VERSION ""

NS_ :

BS_:

BU_: L_DHRR_FD L_UWB_BLE_MST_FD L_UWB_RR_FD L_UWB_BLE_SLV_FD L_UWB_FR_FD L_ROA_FR_FD L_ROA_FD L_DHRL_FD L_UWB_TRNK_FD L_UWB_FRNK_FD L_EDT_FD L_UWB_FL_FD GW_BDC_FD L_UWB_RL_FD L_SAL_FD L_WPC_FD L_TPMS_FD L_DHL_FD L_DHR_FD

BO_ 2214592593 L_BDC_FD_IAU_02_00ms: 16 GW_BDC_FD
 SG_ L_BDC_FD_IAU_Crc2Val : 0|16@1+ (1,0) [0|0] "0" Vector__XXX
 SG_ DKID_Del : 104|8@1+ (1,0) [0|0] ""  L_UWB_BLE_MST_FD,L_UWB_BLE_SLV_FD
 SG_ UWB_Ranging_Cmd_DKID : 112|8@1+ (1,0) [0|0] ""  L_UWB_BLE_MST_FD,L_UWB_BLE_SLV_FD,L_UWB_FL_FD,L_UWB_FRNK_FD,L_UWB_FR_FD,L_UWB_RL_FD,L_UWB_RR_FD,L_UWB_TRNK_FD
 SG_ UWB_Ranging_Cmd_Val : 120|8@1+ (1,0) [0|0] ""  L_UWB_BLE_MST_FD,L_UWB_BLE_SLV_FD,L_UWB_FL_FD,L_UWB_FRNK_FD,L_UWB_FR_FD,L_UWB_RL_FD,L_UWB_RR_FD,L_UWB_TRNK_FD
 SG_ L_BDC_FD_IAU_AlvCnt2Val : 16|8@1+ (1,0) [0|0] "0" Vector__XXX
 SG_ BDC_RndNum_Trgt : 24|4@1+ (1,0) [0|0] ""  L_UWB_BLE_MST_FD,L_UWB_BLE_SLV_FD,L_UWB_FL_FD,L_UWB_FRNK_FD,L_UWB_FR_FD,L_UWB_RL_FD,L_UWB_RR_FD,L_UWB_TRNK_FD
 SG_ BDC_RndNum_TRCod : 28|4@1+ (1,0) [0|0] ""  L_UWB_BLE_MST_FD,L_UWB_BLE_SLV_FD,L_UWB_FL_FD,L_UWB_FRNK_FD,L_UWB_FR_FD,L_UWB_RL_FD,L_UWB_RR_FD,L_UWB_TRNK_FD
 SG_ BDC_RndNum_Cmd : 32|4@1+ (1,0) [0|0] ""  L_UWB_BLE_MST_FD,L_UWB_BLE_SLV_FD,L_UWB_FL_FD,L_UWB_FRNK_FD,L_UWB_FR_FD,L_UWB_RL_FD,L_UWB_RR_FD,L_UWB_TRNK_FD
 SG_ BDC_RndNum : 40|48@1+ (1,0) [0|0] ""  L_UWB_BLE_MST_FD,L_UWB_BLE_SLV_FD,L_UWB_FL_FD,L_UWB_FRNK_FD,L_UWB_FR_FD,L_UWB_RL_FD,L_UWB_RR_FD,L_UWB_TRNK_FD
 SG_ BDC_Decrypt_FB : 88|2@1+ (1,0) [0|0] ""  L_UWB_BLE_MST_FD,L_UWB_BLE_SLV_FD
 SG_ DKID_Set : 96|8@1+ (1,0) [0|0] ""  L_UWB_BLE_MST_FD,L_UWB_BLE_SLV_FD

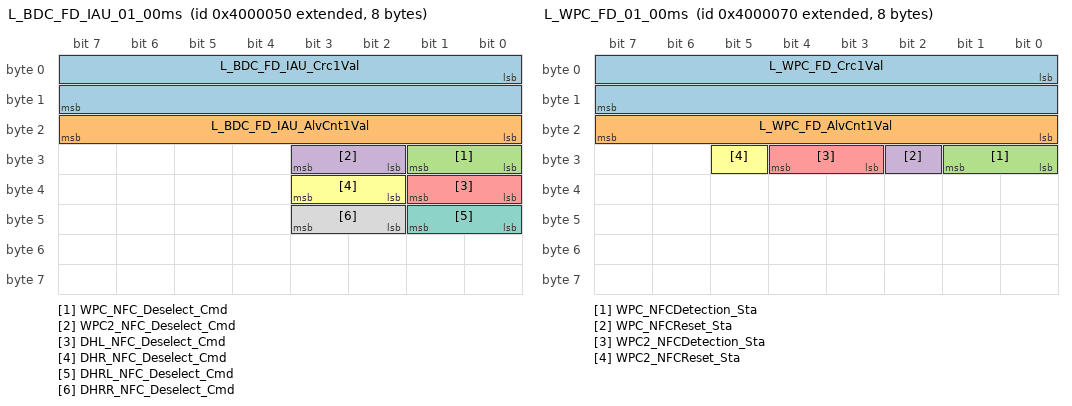
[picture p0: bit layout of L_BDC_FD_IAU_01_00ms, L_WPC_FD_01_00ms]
BO_ 2214592592 L_BDC_FD_IAU_01_00ms: 8 GW_BDC_FD
 SG_ L_BDC_FD_IAU_Crc1Val : 0|16@1+ (1,0) [0|0] "0" Vector__XXX
 SG_ L_BDC_FD_IAU_AlvCnt1Val : 16|8@1+ (1,0) [0|0] "0" Vector__XXX
 SG_ WPC_NFC_Deselect_Cmd : 24|2@1+ (1,0) [0|0] ""  L_WPC_FD
 SG_ WPC2_NFC_Deselect_Cmd : 26|2@1+ (1,0) [0|0] ""  L_WPC_FD
 SG_ DHL_NFC_Deselect_Cmd : 32|2@1+ (1,0) [0|0] ""  L_DHL_FD
 SG_ DHR_NFC_Deselect_Cmd : 34|2@1+ (1,0) [0|0] ""  L_DHR_FD
 SG_ DHRL_NFC_Deselect_Cmd : 40|2@1+ (1,0) [0|0] ""  L_DHRL_FD
 SG_ DHRR_NFC_Deselect_Cmd : 42|2@1+ (1,0) [0|0] ""  L_DHRR_FD

BO_ 2214592595 L_BDC_FD_IAU_04_00ms: 32 GW_BDC_FD
 SG_ L_BDC_FD_IAU_Crc4Val : 0|16@1+ (1,0) [0|0] "0" Vector__XXX
 SG_ L_BDC_FD_IAU_AlvCnt4Val : 16|8@1+ (1,0) [0|0] "0" Vector__XXX
 SG_ BDC_To_BLE_Enc_Data2 : 24|232@1+ (1,0) [0|0] ""  L_UWB_BLE_MST_FD,L_UWB_BLE_SLV_FD

BO_ 2214592594 L_BDC_FD_IAU_03_00ms: 32 GW_BDC_FD
 SG_ L_BDC_FD_IAU_Crc3Val : 0|16@1+ (1,0) [0|0] "0" Vector__XXX
 SG_ L_BDC_FD_IAU_AlvCnt3Val : 16|8@1+ (1,0) [0|0] "0" Vector__XXX
 SG_ BDC_To_BLE_Enc_Data1 : 24|232@1+ (1,0) [0|0] ""  L_UWB_BLE_MST_FD,L_UWB_BLE_SLV_FD

BO_ 2214592597 L_BDC_FD_IAU_06_00ms: 32 GW_BDC_FD
 SG_ L_BDC_FD_IAU_Crc6Val : 0|16@1+ (1,0) [0|0] "0" Vector__XXX
 SG_ L_BDC_FD_IAU_AlvCnt6Val : 16|8@1+ (1,0) [0|0] "0" Vector__XXX
 SG_ BDC_To_UWB_Enc_Data2 : 24|232@1+ (1,0) [0|0] ""  L_UWB_BLE_MST_FD,L_UWB_BLE_SLV_FD,L_UWB_FL_FD,L_UWB_FRNK_FD,L_UWB_FR_FD,L_UWB_RL_FD,L_UWB_RR_FD,L_UWB_TRNK_FD

BO_ 2214592596 L_BDC_FD_IAU_05_00ms: 32 GW_BDC_FD
 SG_ L_BDC_FD_IAU_Crc5Val : 0|16@1+ (1,0) [0|0] "0" Vector__XXX
 SG_ L_BDC_FD_IAU_AlvCnt5Val : 16|8@1+ (1,0) [0|0] "0" Vector__XXX
 SG_ BDC_To_UWB_Enc_Data1 : 24|232@1+ (1,0) [0|0] ""  L_UWB_BLE_MST_FD,L_UWB_BLE_SLV_FD,L_UWB_FL_FD,L_UWB_FRNK_FD,L_UWB_FR_FD,L_UWB_RL_FD,L_UWB_RR_FD,L_UWB_TRNK_FD

BO_ 2214592598 L_BDC_FD_IAU_07_00ms: 32 GW_BDC_FD
 SG_ L_BDC_FD_IAU_Crc7Val : 0|16@1+ (1,0) [0|0] "0" Vector__XXX
 SG_ L_BDC_FD_IAU_AlvCnt7Val : 16|8@1+ (1,0) [0|0] "0" Vector__XXX
 SG_ BDC_To_UWB_Enc_Data3 : 24|232@1+ (1,0) [0|0] ""  L_UWB_BLE_MST_FD,L_UWB_BLE_SLV_FD,L_UWB_FL_FD,L_UWB_FRNK_FD,L_UWB_FR_FD,L_UWB_RL_FD,L_UWB_RR_FD,L_UWB_TRNK_FD

BO_ 2281701632 L_UWB_RR_FD_10_200ms: 24 L_UWB_RR_FD
 SG_ L_UWB_RR_FD_Crc10Val : 0|16@1+ (1,0) [0|0] "0" Vector__XXX
 SG_ UWB_RR_SW_MCU_Ver_Major : 104|8@1+ (1,0) [0|0] ""  L_UWB_BLE_MST_FD
 SG_ UWB_RR_SW_MCU_Ver_Minor : 112|8@1+ (1,0) [0|0] ""  L_UWB_BLE_MST_FD
 SG_ UWB_RR_SW_IC_Ver_Major : 120|8@1+ (1,0) [0|0] ""  L_UWB_BLE_MST_FD
 SG_ UWB_RR_SW_IC_Ver_Minor : 128|8@1+ (1,0) [0|0] ""  L_UWB_BLE_MST_FD
 SG_ UWB_RR_DTC : 136|8@1+ (1,0) [0|0] ""  L_UWB_BLE_MST_FD
 SG_ L_UWB_RR_FD_AlvCnt10Val : 16|8@1+ (1,0) [0|0] "0" Vector__XXX
 SG_ UWB_RR_Status1 : 24|4@1+ (1,0) [0|7] ""  GW_BDC_FD,L_UWB_BLE_MST_FD
 SG_ UWB_RR_Status2 : 28|4@1+ (1,0) [0|0] ""  GW_BDC_FD,L_UWB_BLE_MST_FD
 SG_ UWB_RR_Status3 : 32|4@1+ (1,0) [0|0] ""  GW_BDC_FD,L_UWB_BLE_MST_FD
 SG_ UWB_RR_Status4 : 36|4@1+ (1,0) [0|0] ""  GW_BDC_FD,L_UWB_BLE_MST_FD
 SG_ UWB_RR_Status5 : 40|4@1+ (1,0) [0|0] ""  GW_BDC_FD,L_UWB_BLE_MST_FD
 SG_ UWB_RR_Status6 : 44|4@1+ (1,0) [0|0] ""  GW_BDC_FD,L_UWB_BLE_MST_FD
 SG_ UWB_RR_Status7 : 48|4@1+ (1,0) [0|0] ""  GW_BDC_FD,L_UWB_BLE_MST_FD
 SG_ UWB_RR_Status8 : 52|4@1+ (1,0) [0|0] ""  GW_BDC_FD,L_UWB_BLE_MST_FD
 SG_ UWB_RR_Status9 : 56|4@1+ (1,0) [0|0] ""  GW_BDC_FD,L_UWB_BLE_MST_FD
 SG_ UWB_RR_Status10 : 60|4@1+ (1,0) [0|0] ""  GW_BDC_FD,L_UWB_BLE_MST_FD
 SG_ UWB_RR_Status11 : 64|4@1+ (1,0) [0|0] ""  GW_BDC_FD,L_UWB_BLE_MST_FD
 SG_ UWB_RR_Status12 : 68|4@1+ (1,0) [0|0] ""  GW_BDC_FD,L_UWB_BLE_MST_FD
 SG_ UWB_RR_Status13 : 72|4@1+ (1,0) [0|0] ""  GW_BDC_FD,L_UWB_BLE_MST_FD
 SG_ UWB_RR_Status14 : 76|4@1+ (1,0) [0|0] ""  GW_BDC_FD,L_UWB_BLE_MST_FD
 SG_ UWB_RR_Status15 : 80|4@1+ (1,0) [0|0] ""  GW_BDC_FD,L_UWB_BLE_MST_FD
 SG_ UWB_RR_Status16 : 84|4@1+ (1,0) [0|0] ""  GW_BDC_FD,L_UWB_BLE_MST_FD
 SG_ UWB_RR_HW_Ver_Major : 88|8@1+ (1,0) [0|0] ""  L_UWB_BLE_MST_FD
 SG_ UWB_RR_HW_Ver_Minor : 96|8@1+ (1,0) [0|0] ""  L_UWB_BLE_MST_FD

BO_ 2525342209 L_UWB_FR_FD_06_00ms: 32 L_UWB_FR_FD
 SG_ L_UWB_FR_FD_Crc6Val : 0|16@1+ (1,0) [0|0] "" Vector__XXX
 SG_ L_UWB_FR_FD_AlvCnt6Val : 16|8@1+ (1,0) [0|0] "" Vector__XXX
 SG_ FR_SWID_4_IVD_1 : 24|232@1+ (1,0) [0|0] ""  L_UWB_BLE_MST_FD

BO_ 2281701648 L_UWB_TRNK_FD_10_200ms: 24 L_UWB_TRNK_FD
 SG_ L_UWB_TRNK_FD_Crc10Val : 0|16@1+ (1,0) [0|0] "0" Vector__XXX
 SG_ UWB_TRNK_SW_MCU_Ver_Major : 104|8@1+ (1,0) [0|0] ""  L_UWB_BLE_MST_FD
 SG_ UWB_TRNK_SW_MCU_Ver_Minor : 112|8@1+ (1,0) [0|0] ""  L_UWB_BLE_MST_FD
 SG_ UWB_TRNK_SW_IC_Ver_Major : 120|8@1+ (1,0) [0|0] ""  L_UWB_BLE_MST_FD
 SG_ UWB_TRNK_SW_IC_Ver_Minor : 128|8@1+ (1,0) [0|0] ""  L_UWB_BLE_MST_FD
 SG_ UWB_TRNK_DTC : 136|8@1+ (1,0) [0|0] ""  L_UWB_BLE_MST_FD
 SG_ L_UWB_TRNK_FD_AlvCnt10Val : 16|8@1+ (1,0) [0|0] "0" Vector__XXX
 SG_ UWB_TRNK_Status1 : 24|4@1+ (1,0) [0|7] ""  GW_BDC_FD,L_UWB_BLE_MST_FD
 SG_ UWB_TRNK_Status2 : 28|4@1+ (1,0) [0|0] ""  GW_BDC_FD,L_UWB_BLE_MST_FD
 SG_ UWB_TRNK_Status3 : 32|4@1+ (1,0) [0|0] ""  GW_BDC_FD,L_UWB_BLE_MST_FD
 SG_ UWB_TRNK_Status4 : 36|4@1+ (1,0) [0|0] ""  GW_BDC_FD,L_UWB_BLE_MST_FD
 SG_ UWB_TRNK_Status5 : 40|4@1+ (1,0) [0|0] ""  GW_BDC_FD,L_UWB_BLE_MST_FD
 SG_ UWB_TRNK_Status6 : 44|4@1+ (1,0) [0|0] ""  GW_BDC_FD,L_UWB_BLE_MST_FD
 SG_ UWB_TRNK_Status7 : 48|4@1+ (1,0) [0|0] ""  GW_BDC_FD,L_UWB_BLE_MST_FD
 SG_ UWB_TRNK_Status8 : 52|4@1+ (1,0) [0|0] ""  GW_BDC_FD,L_UWB_BLE_MST_FD
 SG_ UWB_TRNK_Status9 : 56|4@1+ (1,0) [0|0] ""  GW_BDC_FD,L_UWB_BLE_MST_FD
 SG_ UWB_TRNK_Status10 : 60|4@1+ (1,0) [0|0] ""  GW_BDC_FD,L_UWB_BLE_MST_FD
 SG_ UWB_TRNK_Status11 : 64|4@1+ (1,0) [0|0] ""  GW_BDC_FD,L_UWB_BLE_MST_FD
 SG_ UWB_TRNK_Status12 : 68|4@1+ (1,0) [0|0] ""  GW_BDC_FD,L_UWB_BLE_MST_FD
 SG_ UWB_TRNK_Status13 : 72|4@1+ (1,0) [0|0] ""  GW_BDC_FD,L_UWB_BLE_MST_FD
 SG_ UWB_TRNK_Status14 : 76|4@1+ (1,0) [0|0] ""  GW_BDC_FD,L_UWB_BLE_MST_FD
 SG_ UWB_TRNK_Status15 : 80|4@1+ (1,0) [0|0] ""  GW_BDC_FD,L_UWB_BLE_MST_FD
 SG_ UWB_TRNK_Status16 : 84|4@1+ (1,0) [0|0] ""  GW_BDC_FD,L_UWB_BLE_MST_FD
 SG_ UWB_TRNK_HW_Ver_Major : 88|8@1+ (1,0) [0|0] ""  L_UWB_BLE_MST_FD
 SG_ UWB_TRNK_HW_Ver_Minor : 96|8@1+ (1,0) [0|0] ""  L_UWB_BLE_MST_FD

BO_ 2214592624 L_WPC_FD_01_00ms: 8 L_WPC_FD
 SG_ L_WPC_FD_Crc1Val : 0|16@1+ (1,0) [0|0] "0" Vector__XXX
 SG_ L_WPC_FD_AlvCnt1Val : 16|8@1+ (1,0) [0|0] "0" Vector__XXX
 SG_ WPC_NFCDetection_Sta : 24|2@1+ (1,0) [0|0] ""  GW_BDC_FD
 SG_ WPC_NFCReset_Sta : 26|1@1+ (1,0) [0|0] ""  GW_BDC_FD
 SG_ WPC2_NFCDetection_Sta : 27|2@1+ (1,0) [0|0] ""  GW_BDC_FD
 SG_ WPC2_NFCReset_Sta : 29|1@1+ (1,0) [0|0] ""  GW_BDC_FD

BO_ 2281701664 L_ROA_FD_01_200ms: 32 L_ROA_FD
 SG_ L_ROA_FD_Crc1Val : 0|16@1+ (1,0) [0|0] "0" Vector__XXX
 SG_ L_ROA_FD_AlvCnt1Val : 16|8@1+ (1,0) [0|0] "0" Vector__XXX
 SG_ ROA_SW_Ver_Major : 24|7@1+ (1,0) [0|0] ""  GW_BDC_FD
 SG_ ROA_SW_Ver_Minor1 : 31|7@1+ (1,0) [0|0] ""  GW_BDC_FD
 SG_ ROA_SW_Ver_Minor2 : 38|7@1+ (1,0) [0|0] ""  GW_BDC_FD
 SG_ ROA_ClassStat : 45|3@1+ (1,0) [0|0] ""  GW_BDC_FD
 SG_ ROA_SnSrStat : 48|3@1+ (1,0) [0|0] ""  GW_BDC_FD
 SG_ ROA_DetInfo : 51|3@1+ (1,0) [0|0] ""  GW_BDC_FD
 SG_ ROA_SnSrBlckgeErrStat : 54|2@1+ (1,0) [0|0] ""  GW_BDC_FD
 SG_ ROA_SnSrErrStat : 56|2@1+ (1,0) [0|0] ""  GW_BDC_FD

BO_ 2281701666 L_ROA_FR_FD_01_200ms: 32 L_ROA_FR_FD
 SG_ L_ROA_FR_FD_Crc1Val : 0|16@1+ (1,0) [0|0] "0" Vector__XXX
 SG_ L_ROA_FR_FD_AlvCnt1Val : 16|8@1+ (1,0) [0|0] "0" Vector__XXX
 SG_ ROA_FR_SW_Ver_Major : 24|7@1+ (1,0) [0|0] ""  L_ROA_FD
 SG_ ROA_FR_SW_Ver_Minor1 : 31|7@1+ (1,0) [0|0] ""  L_ROA_FD
 SG_ ROA_FR_SW_Ver_Minor2 : 38|7@1+ (1,0) [0|0] ""  L_ROA_FD
 SG_ ROA_FR_ClassStat : 45|3@1+ (1,0) [0|0] ""  L_ROA_FD
 SG_ ROA_FR_SnSrStat : 48|3@1+ (1,0) [0|0] ""  L_ROA_FD
 SG_ ROA_FR_DetInfo : 51|3@1+ (1,0) [0|0] ""  L_ROA_FD
 SG_ ROA_FR_SnSrBlckgeErrStat : 54|2@1+ (1,0) [0|0] ""  L_ROA_FD
 SG_ ROA_FR_SnSrErrStat : 56|2@1+ (1,0) [0|0] ""  L_ROA_FD

BO_ 2214592608 L_BDC_FD_ROA_02_00ms: 32 GW_BDC_FD
 SG_ L_BDC_FD_ROA_Crc2Val : 0|16@1+ (1,0) [0|0] "0" Vector__XXX
 SG_ L_BDC_FD_ROA_AlvCnt2Val : 16|8@1+ (1,0) [0|0] "0" Vector__XXX
 SG_ BDCROADataByte0 : 24|8@1+ (1,0) [0|0] ""  L_ROA_FD,L_ROA_FR_FD
 SG_ BDCROADataByte1 : 32|8@1+ (1,0) [0|0] ""  L_ROA_FD,L_ROA_FR_FD
 SG_ BDCROADataByte2 : 40|8@1+ (1,0) [0|0] ""  L_ROA_FD,L_ROA_FR_FD
 SG_ BDCROADataByte3 : 48|8@1+ (1,0) [0|0] ""  L_ROA_FD,L_ROA_FR_FD
 SG_ BDCROADataByte4 : 56|8@1+ (1,0) [0|0] ""  L_ROA_FD,L_ROA_FR_FD
 SG_ BDCROADataByte5 : 64|8@1+ (1,0) [0|0] ""  L_ROA_FD,L_ROA_FR_FD
 SG_ BDCROADataByte6 : 72|8@1+ (1,0) [0|0] ""  L_ROA_FD,L_ROA_FR_FD
 SG_ BDCROADataByte7 : 80|8@1+ (1,0) [0|0] ""  L_ROA_FD,L_ROA_FR_FD

BO_ 2525341697 L_UWB_FR_FD_04_00ms: 32 L_UWB_FR_FD
 SG_ L_UWB_FR_FD_Crc4Val : 0|16@1+ (1,0) [0|0] "" Vector__XXX
 SG_ L_UWB_FR_FD_AlvCnt4Val : 16|8@1+ (1,0) [0|0] "" Vector__XXX
 SG_ FR_SWID_3_IVD_1 : 24|232@1+ (1,0) [0|0] ""  L_UWB_BLE_MST_FD

BO_ 2281701680 L_SAL_FD_01_200ms: 32 L_SAL_FD
 SG_ L_SAL_FD_Crc1Val : 0|16@1+ (1,0) [0|0] "0" Vector__XXX
 SG_ SAL_BttmBrightnessDutyRatio : 105|8@1+ (1,0) [0|0] ""  GW_BDC_FD
 SG_ SAL_BttmFadeInTime : 113|8@1+ (1,0) [0|0] ""  GW_BDC_FD
 SG_ SAL_BttmFadeOutTimeValue : 121|8@1+ (1,0) [0|0] ""  GW_BDC_FD
 SG_ SAL_MLNShiftModOptionState : 129|2@1+ (1,0) [0|0] ""  GW_BDC_FD
 SG_ L_SAL_FD_AlvCnt1Val : 16|8@1+ (1,0) [0|0] "0" Vector__XXX
 SG_ SAL_MLSALApplyState : 24|2@1+ (1,0) [0|0] ""  GW_BDC_FD
 SG_ SAL_MLAIVoiceOptionState : 26|2@1+ (1,0) [0|0] ""  GW_BDC_FD
 SG_ SAL_MLTherapyOptionState : 28|2@1+ (1,0) [0|0] ""  GW_BDC_FD
 SG_ SAL_MLDualColorOptionState : 30|2@1+ (1,0) [0|0] ""  GW_BDC_FD
 SG_ SAL_MLNumRecommendColor : 32|4@1+ (1,0) [0|0] ""  GW_BDC_FD
 SG_ SAL_UPRColorXValue : 36|8@1+ (1,0) [0|0] ""  GW_BDC_FD
 SG_ SAL_UPRColorYValue : 44|8@1+ (1,0) [0|0] ""  GW_BDC_FD
 SG_ SAL_BrightnessDutyRatio : 52|8@1+ (1,0) [0|0] ""  GW_BDC_FD
 SG_ SAL_FadeInTime : 60|8@1+ (1,0) [0|0] ""  GW_BDC_FD
 SG_ SAL_FadeOutTimeValue : 68|8@1+ (1,0) [0|0] ""  GW_BDC_FD
 SG_ SAL_MLEarlyEveningOptionState : 76|2@1+ (1,0) [0|0] ""  GW_BDC_FD
 SG_ SAL_MLTempChgOptionState : 78|2@1+ (1,0) [0|0] ""  GW_BDC_FD
 SG_ SAL_MLPhoneCallModOptionState : 80|2@1+ (1,0) [0|0] ""  GW_BDC_FD
 SG_ SAL_MLDoorWarnOptionState : 82|3@1+ (1,0) [0|0] ""  GW_BDC_FD
 SG_ SAL_MLHazardModOptionState : 85|2@1+ (1,0) [0|0] ""  GW_BDC_FD
 SG_ SAL_MLLowFuelModOptionState : 87|2@1+ (1,0) [0|0] ""  GW_BDC_FD
 SG_ SAL_BttmColorXValue : 89|8@1+ (1,0) [0|0] ""  GW_BDC_FD
 SG_ SAL_BttmColorYValue : 97|8@1+ (1,0) [0|0] ""  GW_BDC_FD

BO_ 1025 BDC_FD_SMK_02_200ms: 32 GW_BDC_FD
 SG_ BDC_FD_SMK_Crc2Val : 0|16@1+ (1,0) [0|0] "" Vector__XXX
 SG_ SMK_RpmLoByteVal_Copy_0 : 104|8@1+ (1,0) [0|0] "" Vector__XXX
 SG_ SMK_VehSpdDrctVal_Copy_0 : 112|8@1+ (1,0) [0|0] "" Vector__XXX
 SG_ Fob_BattStaInfo_Copy_0 : 120|2@1+ (1,0) [0|0] "" Vector__XXX
 SG_ Fob_FoundDrvWlcmArea_Copy_0 : 122|2@1+ (1,0) [0|0] "" Vector__XXX
 SG_ Fob_FoundAsstWlcmArea_Copy_0 : 124|2@1+ (1,0) [0|0] "" Vector__XXX
 SG_ Fob_FoundExtrnlArea_Copy_0 : 126|2@1+ (1,0) [0|0] "" Vector__XXX
 SG_ Fob_FoundIntArea_Copy_0 : 128|2@1+ (1,0) [0|0] "" Vector__XXX
 SG_ Fob_LearntSta_Copy_0 : 130|2@1+ (1,0) [0|0] "" Vector__XXX
 SG_ RSPA_LearntSta_Copy_0 : 132|2@1+ (1,0) [0|0] "" Vector__XXX
 SG_ RSPA_RFSigErrSta_Copy_0 : 134|2@1+ (1,0) [0|0] "" Vector__XXX
 SG_ RSPA_CanErrSta_Copy_0 : 136|2@1+ (1,0) [0|0] "" Vector__XXX
 SG_ RSPA_ModSta_SMK_Copy_0 : 138|3@1+ (1,0) [0|0] "" Vector__XXX
 SG_ RSPA_FobBattSta_Copy_0 : 141|3@1+ (1,0) [0|0] "" Vector__XXX
 SG_ Fob_BtnReleasedSta_Copy_0 : 144|2@1+ (1,0) [0|0] "" Vector__XXX
 SG_ Fob_FoundWlcmArea_Copy_0 : 146|2@1+ (1,0) [0|0] "" Vector__XXX
 SG_ USM_WALModSta_Copy_0 : 148|3@1+ (1,0) [0|0] "" Vector__XXX
 SG_ USM_SmrtTrnkTlgtModSta_Copy_0 : 152|3@1+ (1,0) [0|0] "" Vector__XXX
 SG_ USM_SAUModSta : 155|3@1+ (1,0) [0|0] "" Vector__XXX
 SG_ SMK_RLHndLkSnsrSta_Copy_0 : 158|2@1+ (1,0) [0|0] "" Vector__XXX
 SG_ BDC_FD_SMK_AlvCnt2Val : 16|8@1+ (1,0) [0|0] "" Vector__XXX
 SG_ SMK_RLDrHndUnLkSnsrSta_Copy_0 : 160|2@1+ (1,0) [0|0] "" Vector__XXX
 SG_ SMK_RRDrHndLkSnsrSta_Copy_0 : 162|2@1+ (1,0) [0|0] "" Vector__XXX
 SG_ SMK_RRDrHndUnLkSnsrSta_Copy_0 : 164|2@1+ (1,0) [0|0] "" Vector__XXX
 SG_ Fob_FoundCabinArea_Copy_0 : 166|2@1+ (1,0) [0|0] "" Vector__XXX
 SG_ SMK_ResultRmtStrt : 168|3@1+ (1,0) [0|0] "" Vector__XXX
 SG_ SMK_EncryptTeleOptSta : 171|2@1+ (1,0) [0|0] "" Vector__XXX
 SG_ Auth_ISKLearnSta2_Copy_0 : 173|3@1+ (1,0) [0|0] "" Vector__XXX
 SG_ Auth_ISKLearnSta_Copy_0 : 176|3@1+ (1,0) [0|0] "" Vector__XXX
 SG_ SMK_TlPwrOnSta_Copy_0 : 179|2@1+ (1,0) [0|0] "" Vector__XXX
 SG_ Fob_FoundForChargingDoor_Copy_0 : 181|2@1+ (1,0) [0|0] "" Vector__XXX
 SG_ SSB_StrtStpBtnSw1Sta_Copy_0 : 24|2@1+ (1,0) [0|0] ""  L_UWB_BLE_MST_FD
 SG_ SSB_StrtStpBtnSw2Sta_Copy_0 : 26|2@1+ (1,0) [0|0] ""  L_UWB_BLE_MST_FD
 SG_ SMK_AuthSta_Copy_0 : 28|3@1+ (1,0) [0|0] "" Vector__XXX
 SG_ SMK_TlPwrOnOpt_Copy_0 : 31|1@1+ (1,0) [0|0] "" Vector__XXX
 SG_ SMK_Ign1InSta_Copy_0 : 32|2@1+ (1,0) [0|0] "" Vector__XXX
 SG_ SMK_Ign1RlySta_Copy_0 : 34|2@1+ (1,0) [0|0] "" Vector__XXX
 SG_ SMK_Ign2InSta_Copy_0 : 36|2@1+ (1,0) [0|0] "" Vector__XXX
 SG_ SMK_Ign2RlySta_Copy_0 : 38|2@1+ (1,0) [0|0] "" Vector__XXX
 SG_ SMK_StrtFdbckSta_Copy_0 : 40|2@1+ (1,0) [0|0] "" Vector__XXX
 SG_ SMK_StrtrRlyOutSta_Copy_0 : 42|2@1+ (1,0) [0|0] "" Vector__XXX
 SG_ SMK_AccInSta_Copy_0 : 44|2@1+ (1,0) [0|0] "" Vector__XXX
 SG_ SMK_AccRlySta_Copy_0 : 46|2@1+ (1,0) [0|0] "" Vector__XXX
 SG_ SMK_CLUAccIndOnReq_Copy_0 : 48|2@1+ (1,0) [0|0] "" Vector__XXX
 SG_ SMK_VDModeActSta_Copy_0 : 50|2@1+ (1,0) [0|0] "" Vector__XXX
 SG_ SMK_SCULckUnlckSta_Copy_0 : 52|2@1+ (1,0) [0|0] "" Vector__XXX
 SG_ SMK_TlEngRunSta_Copy_0 : 54|2@1+ (1,0) [0|0] "" Vector__XXX
 SG_ SMK_TlCrnkModSta_Copy_0 : 56|2@1+ (1,0) [0|0] "" Vector__XXX
 SG_ SMK_RmtKeyEngRunSta_Copy_0 : 58|2@1+ (1,0) [0|0] "" Vector__XXX
 SG_ SMK_RmtKeyCrnkModSta_Copy_0 : 60|2@1+ (1,0) [0|0] "" Vector__XXX
 SG_ SMK_AsstTgglBtnSta_Copy_0 : 62|2@1+ (1,0) [0|0] "" Vector__XXX
 SG_ SMK_DrvTglBtnSta_Copy_0 : 64|2@1+ (1,0) [0|0] "" Vector__XXX
 SG_ SMK_RrLftTglBtnSta_Copy_0 : 66|2@1+ (1,0) [0|0] "" Vector__XXX
 SG_ SMK_RrRtTglBtnSta_Copy_0 : 68|2@1+ (1,0) [0|0] "" Vector__XXX
 SG_ SMK_TgglBtnStuckSta_Copy_0 : 70|2@1+ (1,0) [0|0] "" Vector__XXX
 SG_ SMK_AsstDrHndUnLkSnsrSta_Copy_0 : 72|2@1+ (1,0) [0|0] "" Vector__XXX
 SG_ SMK_BrkSwSta_Copy_0 : 74|2@1+ (1,0) [0|0] "" Vector__XXX
 SG_ SMK_GearPosPSwSta_Copy_0 : 76|2@1+ (1,0) [0|0] "" Vector__XXX
 SG_ SMK_CltchIgnLkSwSta_Copy_0 : 78|2@1+ (1,0) [0|0] "" Vector__XXX
 SG_ SMK_DrvDrHndLkSnsrSta_Copy_0 : 80|2@1+ (1,0) [0|0] "" Vector__XXX
 SG_ SMK_DrvDrHndUnLkSnsrSta_Copy_0 : 82|2@1+ (1,0) [0|0] "" Vector__XXX
 SG_ SMK_AsstDrHndLkSnsrSta_Copy_0 : 84|2@1+ (1,0) [0|0] "" Vector__XXX
 SG_ LFAnt_FltSta_Copy_0 : 86|2@1+ (1,0) [0|0] "" Vector__XXX
 SG_ LFAnt_SrchSta_Copy_0 : 88|2@1+ (1,0) [0|0] "" Vector__XXX
 SG_ Lamp_HzrdBlnkngSta_Copy_0 : 90|3@1+ (1,0) [0|0] "" Vector__XXX
 SG_ Lamp_SmrtWlcmLtOnReq_Copy_0 : 93|2@1+ (1,0) [0|0] "" Vector__XXX
 SG_ SMK_RpmHiByteVal_Copy_0 : 96|8@1+ (1,0) [0|0] "" Vector__XXX

BO_ 2529540353 L_UWB_RR_FD_05_00ms: 32 L_UWB_RR_FD
 SG_ L_UWB_RR_FD_Crc5Val : 0|16@1+ (1,0) [0|0] "" Vector__XXX
 SG_ L_UWB_RR_FD_AlvCnt5Val : 16|8@1+ (1,0) [0|0] "" Vector__XXX
 SG_ RR_SWID_3_IVD_2 : 24|24@1+ (1,0) [0|0] ""  L_UWB_BLE_MST_FD

BO_ 2521142529 L_UWB_BLE_SLV_FD_09_00ms: 32 L_UWB_BLE_SLV_FD
 SG_ L_UWB_BLE_SLV_FD_Crc9Val : 0|16@1+ (1,0) [0|0] "" Vector__XXX
 SG_ L_UWB_BLE_SLV_FD_AlvCnt9Val : 16|8@1+ (1,0) [0|0] "" Vector__XXX
 SG_ SLV_SWID_2_IVD_1 : 24|232@1+ (1,0) [0|0] ""  L_UWB_BLE_MST_FD

BO_ 2533738753 L_UWB_FRNK_FD_05_00ms: 32 L_UWB_FRNK_FD
 SG_ L_UWB_FRNK_FD_Crc5Val : 0|16@1+ (1,0) [0|0] "" Vector__XXX
 SG_ L_UWB_FRNK_FD_AlvCnt5Val : 16|8@1+ (1,0) [0|0] "" Vector__XXX
 SG_ FRNK_SWID_3_IVD_2 : 24|24@1+ (1,0) [0|0] ""  L_UWB_BLE_MST_FD

BO_ 2529540865 L_UWB_RR_FD_07_00ms: 32 L_UWB_RR_FD
 SG_ L_UWB_RR_FD_Crc7Val : 0|16@1+ (1,0) [0|0] "" Vector__XXX
 SG_ L_UWB_RR_FD_AlvCnt7Val : 16|8@1+ (1,0) [0|0] "" Vector__XXX
 SG_ RR_SWID_4_IVD_2 : 24|24@1+ (1,0) [0|0] ""  L_UWB_BLE_MST_FD

BO_ 2521143041 L_UWB_BLE_SLV_FD_11_00ms: 32 L_UWB_BLE_SLV_FD
 SG_ L_UWB_BLE_SLV_FD_Crc11Val : 0|16@1+ (1,0) [0|0] "" Vector__XXX
 SG_ L_UWB_BLE_SLV_FD_AlvCnt11Val : 16|8@1+ (1,0) [0|0] "" Vector__XXX
 SG_ SLV_SWID_3_IVD_1 : 24|232@1+ (1,0) [0|0] ""  L_UWB_BLE_MST_FD

BO_ 2533739265 L_UWB_FRNK_FD_07_00ms: 32 L_UWB_FRNK_FD
 SG_ L_UWB_FRNK_FD_Crc7Val : 0|16@1+ (1,0) [0|0] "" Vector__XXX
 SG_ L_UWB_FRNK_FD_AlvCnt7Val : 16|8@1+ (1,0) [0|0] "" Vector__XXX
 SG_ FRNK_SWID_4_IVD_2 : 24|24@1+ (1,0) [0|0] ""  L_UWB_BLE_MST_FD

BO_ 2214593024 L_EDT_FD_BLE_Dvp_01_00ms: 32 L_EDT_FD
 SG_ EDT_BLE_Dvp_Data : 0|256@1+ (1,0) [0|0] ""  L_UWB_BLE_MST_FD,L_UWB_BLE_SLV_FD,L_UWB_FL_FD,L_UWB_FRNK_FD,L_UWB_FR_FD,L_UWB_RL_FD,L_UWB_RR_FD,L_UWB_TRNK_FD

BO_ 2214593025 L_EDT_FD_DH_Dvp_02_00ms: 32 L_EDT_FD
 SG_ EDT_DH_Dvp_Data : 0|255@1+ (1,0) [0|0] ""  L_UWB_BLE_MST_FD,L_UWB_BLE_SLV_FD

BO_ 2214593026 L_EDT_FD_UWB_Dvp_03_00ms: 32 L_EDT_FD
 SG_ EDT_UWB_Dvp_Data : 0|256@1+ (1,0) [0|0] ""  L_UWB_BLE_MST_FD,L_UWB_BLE_SLV_FD,L_UWB_FL_FD,L_UWB_FRNK_FD,L_UWB_FR_FD,L_UWB_RL_FD,L_UWB_RR_FD,L_UWB_TRNK_FD

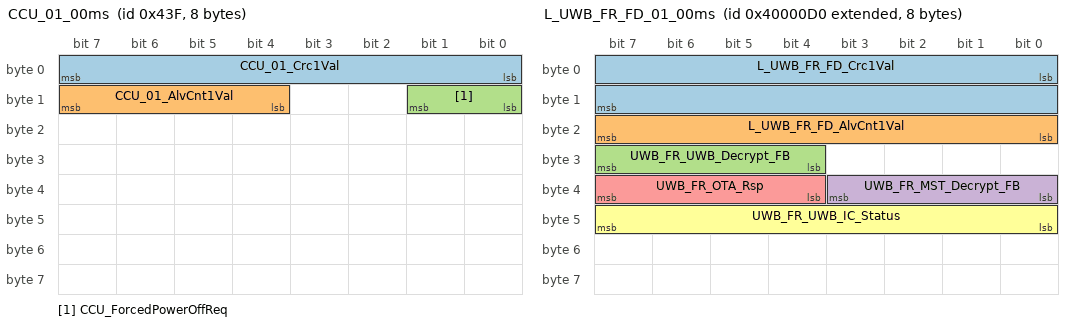
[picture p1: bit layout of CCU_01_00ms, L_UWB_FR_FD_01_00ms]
BO_ 1087 CCU_01_00ms: 8 GW_BDC_FD
 SG_ CCU_01_Crc1Val : 0|8@1+ (1,0) [0|0] "" Vector__XXX
 SG_ CCU_01_AlvCnt1Val : 12|4@1+ (1,0) [0|0] "" Vector__XXX
 SG_ CCU_ForcedPowerOffReq : 8|2@1+ (1,0) [0|0] ""  L_DHL_FD,L_DHRL_FD,L_DHRR_FD,L_DHR_FD,L_ROA_FD,L_ROA_FR_FD,L_SAL_FD,L_TPMS_FD,L_UWB_BLE_MST_FD,L_UWB_BLE_SLV_FD,L_UWB_FL_FD,L_UWB_FRNK_FD,L_UWB_FR_FD,L_UWB_RL_FD,L_UWB_RR_FD,L_UWB_TRNK_FD,L_WPC_FD

BO_ 2214592730 L_UWB_BLE_SLV_FD_22_00ms: 32 L_UWB_BLE_SLV_FD
 SG_ L_UWB_BLE_SLV_FD_Crc22Val : 0|16@1+ (1,0) [0|0] "0" Vector__XXX
 SG_ L_UWB_BLE_SLV_FD_AlvCnt22Val : 16|8@1+ (1,0) [0|0] "0" Vector__XXX
 SG_ SLV_DisconnectDKID : 24|8@1+ (1,0) [0|0] ""  L_EDT_FD
 SG_ SLV_DisconnectReason : 32|8@1+ (1,0) [0|0] ""  L_EDT_FD
 SG_ SLV_BLE_ErrorReturn : 40|8@1+ (1,0) [0|0] ""  L_EDT_FD,L_UWB_BLE_MST_FD

BO_ 2525340161 L_UWB_FL_FD_06_00ms: 32 L_UWB_FL_FD
 SG_ L_UWB_FL_FD_Crc6Val : 0|16@1+ (1,0) [0|0] "" Vector__XXX
 SG_ L_UWB_FL_FD_AlvCnt6Val : 16|8@1+ (1,0) [0|0] "" Vector__XXX
 SG_ FL_SWID_4_IVD_1 : 24|232@1+ (1,0) [0|0] ""  L_UWB_BLE_MST_FD

BO_ 2214592735 L_UWB_FR_FD_Dvp_01_00ms: 32 L_UWB_FR_FD
 SG_ UWB_FR_Dvp_Data : 0|255@1+ (1,0) [0|0] ""  L_EDT_FD

BO_ 2214592720 L_UWB_FR_FD_01_00ms: 8 L_UWB_FR_FD
 SG_ L_UWB_FR_FD_Crc1Val : 0|16@1+ (1,0) [0|0] "0" Vector__XXX
 SG_ L_UWB_FR_FD_AlvCnt1Val : 16|8@1+ (1,0) [0|0] "0" Vector__XXX
 SG_ UWB_FR_UWB_Decrypt_FB : 28|4@1+ (1,0) [0|0] ""  GW_BDC_FD
 SG_ UWB_FR_MST_Decrypt_FB : 32|4@1+ (1,0) [0|0] ""  L_UWB_BLE_MST_FD
 SG_ UWB_FR_OTA_Rsp : 36|4@1+ (1,0) [0|0] ""  L_UWB_BLE_MST_FD
 SG_ UWB_FR_UWB_IC_Status : 40|8@1+ (1,0) [0|0] ""  L_EDT_FD

BO_ 2214592721 L_UWB_FR_FD_02_00ms: 16 L_UWB_FR_FD
 SG_ L_UWB_FR_FD_Crc2Val : 0|16@1+ (1,0) [0|0] "0" Vector__XXX
 SG_ L_UWB_FR_FD_AlvCnt2Val : 16|8@1+ (1,0) [0|0] "0" Vector__XXX
 SG_ UWB_FR_FOB_RSD_Enc_Result : 24|64@1+ (1,0) [0|0] ""  GW_BDC_FD

CM_ BO_ 2214592593 "[EC] On Event and On Change";
CM_ SG_ 2214592593 L_BDC_FD_IAU_Crc2Val "L_BDC_FD_IAU_CyclicRedundancyCheck2Value";
CM_ SG_ 2214592593 DKID_Del "BLE DK ID Delete";
CM_ SG_ 2214592593 UWB_Ranging_Cmd_DKID "UWB Ranging CMD DKID to UWB";
CM_ SG_ 2214592593 UWB_Ranging_Cmd_Val "UWB Ranging CMD Value to UWB";
CM_ SG_ 2214592593 L_BDC_FD_IAU_AlvCnt2Val "L_BDC_FD_IAU_AliveCounter2Value";
CM_ SG_ 2214592593 BDC_RndNum_Trgt "Local Random Number Target Define";
CM_ SG_ 2214592593 BDC_RndNum_TRCod "Local Random Number TRCode";
CM_ SG_ 2214592593 BDC_RndNum_Cmd "Local Random Number CMD";
CM_ SG_ 2214592593 BDC_RndNum "Local Random Number from BDC";
CM_ SG_ 2214592593 BDC_Decrypt_FB "BLE Enc Data Decryption Feed Back";
CM_ SG_ 2214592593 DKID_Set "BLE DK ID Setting";
CM_ BO_ 2214592592 "[EC] On Event and On Change";
CM_ SG_ 2214592592 L_BDC_FD_IAU_Crc1Val "L_BDC_FD_IAU_CyclicRedundancyCheck1Value";
CM_ SG_ 2214592592 L_BDC_FD_IAU_AlvCnt1Val "L_BDC_FD_IAU_AliveCounter1Value";
CM_ SG_ 2214592592 WPC_NFC_Deselect_Cmd "NFC Searchig Start/Stop command to WPC";
CM_ SG_ 2214592592 WPC2_NFC_Deselect_Cmd "NFC Searchig Start/Stop command to WPC#2";
CM_ SG_ 2214592592 DHL_NFC_Deselect_Cmd "NFC Searchig Start/Stop command to DHL";
CM_ SG_ 2214592592 DHR_NFC_Deselect_Cmd "NFC Searchig Start/Stop command to DHR";
CM_ SG_ 2214592592 DHRL_NFC_Deselect_Cmd "NFC Searchig Start/Stop command to DHRL";
CM_ SG_ 2214592592 DHRR_NFC_Deselect_Cmd "NFC Searchig Start/Stop command to DHRR";
CM_ BO_ 2214592595 "[EC] On Event and On Change";
CM_ SG_ 2214592595 L_BDC_FD_IAU_Crc4Val "L_BDC_FD_IAU_CyclicRedundancyCheck4Value";
CM_ SG_ 2214592595 L_BDC_FD_IAU_AlvCnt4Val "L_BDC_FD_IAU_AliveCounter4Value";
CM_ SG_ 2214592595 BDC_To_BLE_Enc_Data2 "Encrypted Data From BDC to BLE";
CM_ BO_ 2214592594 "[EC] On Event and On Change";
CM_ SG_ 2214592594 L_BDC_FD_IAU_Crc3Val "L_BDC_FD_IAU_CyclicRedundancyCheck3Value";
CM_ SG_ 2214592594 L_BDC_FD_IAU_AlvCnt3Val "L_BDC_FD_IAU_AliveCounter3Value";
CM_ SG_ 2214592594 BDC_To_BLE_Enc_Data1 "Encrypted Data From BDC to BLE";
CM_ BO_ 2214592597 "[EC] On Event and On Change";
CM_ SG_ 2214592597 L_BDC_FD_IAU_Crc6Val "L_BDC_FD_IAU_CyclicRedundancyCheck6Value";
CM_ SG_ 2214592597 L_BDC_FD_IAU_AlvCnt6Val "L_BDC_FD_IAU_AliveCounter6Value";
CM_ SG_ 2214592597 BDC_To_UWB_Enc_Data2 "Encrypted Data From BDC to UWB ALL";
CM_ BO_ 2214592596 "[EC] On Event and On Change";
CM_ SG_ 2214592596 L_BDC_FD_IAU_Crc5Val "L_BDC_FD_IAU_CyclicRedundancyCheck5Value";
CM_ SG_ 2214592596 L_BDC_FD_IAU_AlvCnt5Val "L_BDC_FD_IAU_AliveCounter5Value";
CM_ SG_ 2214592596 BDC_To_UWB_Enc_Data1 "Encrypted Data From BDC to UWB ALL";
CM_ BO_ 2214592598 "[EC] On Event and On Change";
CM_ SG_ 2214592598 L_BDC_FD_IAU_Crc7Val "L_BDC_FD_IAU_CyclicRedundancyCheck7Value";
CM_ SG_ 2214592598 L_BDC_FD_IAU_AlvCnt7Val "L_BDC_FD_IAU_AliveCounter7Value";
CM_ SG_ 2214592598 BDC_To_UWB_Enc_Data3 "Encrypted Data From BDC to UWB ALL";
CM_ BO_ 2281701632 "[PE] Periodic and On Event";
CM_ SG_ 2281701632 L_UWB_RR_FD_Crc10Val "L_UWB_RR_FD_CyclicRedundancyCheck10Value";
CM_ SG_ 2281701632 UWB_RR_SW_MCU_Ver_Major "UWB RR SW MCU Version Major";
CM_ SG_ 2281701632 UWB_RR_SW_MCU_Ver_Minor "UWB RR SW MCU Version Minor";
CM_ SG_ 2281701632 UWB_RR_SW_IC_Ver_Major "UWB RR SW IC Version Major";
CM_ SG_ 2281701632 UWB_RR_SW_IC_Ver_Minor "UWB RR SW IC Version Minor";
CM_ SG_ 2281701632 UWB_RR_DTC "UWB RR DTC Data";
CM_ SG_ 2281701632 L_UWB_RR_FD_AlvCnt10Val "L_UWB_RR_FD_AliveCounter10Value";
CM_ SG_ 2281701632 UWB_RR_Status1 "UWB_RR Processing Status 1";
CM_ SG_ 2281701632 UWB_RR_Status2 "UWB_RR Processing Status 2";
CM_ SG_ 2281701632 UWB_RR_Status3 "UWB_RR Processing Status 3";
CM_ SG_ 2281701632 UWB_RR_Status4 "UWB_RR Processing Status 4";
CM_ SG_ 2281701632 UWB_RR_Status5 "UWB_RR Processing Status 5";
CM_ SG_ 2281701632 UWB_RR_Status6 "UWB_RR Processing Status 6";
CM_ SG_ 2281701632 UWB_RR_Status7 "UWB_RR Processing Status 7";
CM_ SG_ 2281701632 UWB_RR_Status8 "UWB_RR Processing Status 8";
CM_ SG_ 2281701632 UWB_RR_Status9 "UWB_RR Processing Status 9";
CM_ SG_ 2281701632 UWB_RR_Status10 "UWB_RR Processing Status 10";
CM_ SG_ 2281701632 UWB_RR_Status11 "UWB_RR Processing Status 11";
CM_ SG_ 2281701632 UWB_RR_Status12 "UWB_RR Processing Status 12";
CM_ SG_ 2281701632 UWB_RR_Status13 "UWB_RR Processing Status 13";
CM_ SG_ 2281701632 UWB_RR_Status14 "UWB_RR Processing Status 14";
CM_ SG_ 2281701632 UWB_RR_Status15 "UWB_RR Processing Status 15";
CM_ SG_ 2281701632 UWB_RR_Status16 "UWB_RR Processing Status 16";
CM_ SG_ 2281701632 UWB_RR_HW_Ver_Major "UWB RR HW Version Major";
CM_ SG_ 2281701632 UWB_RR_HW_Ver_Minor "UWB RR HW Version Minor";
CM_ BO_ 2525342209 "[EW] On Event and On Write";
CM_ SG_ 2525342209 L_UWB_FR_FD_Crc6Val "L_UWB_FR_FD_CyclicRedundancyCheck6Value";
CM_ SG_ 2525342209 L_UWB_FR_FD_AlvCnt6Val "L_UWB_FR_FD_AliveCounter6Value";
CM_ SG_ 2525342209 FR_SWID_4_IVD_1 "UWB FR SW Unit 4 IVD1";
CM_ BO_ 2281701648 "[PE] Periodic and On Event";
CM_ SG_ 2281701648 L_UWB_TRNK_FD_Crc10Val "L_UWB_TRNK_FD_CyclicRedundancyCheck10Value";
CM_ SG_ 2281701648 UWB_TRNK_SW_MCU_Ver_Major "UWB TRNK SW MCU Version Major";
CM_ SG_ 2281701648 UWB_TRNK_SW_MCU_Ver_Minor "UWB TRNK SW MCU Version Minor";
CM_ SG_ 2281701648 UWB_TRNK_SW_IC_Ver_Major "UWB TRNK SW IC Version Major";
CM_ SG_ 2281701648 UWB_TRNK_SW_IC_Ver_Minor "UWB TRNK SW IC Version Minor";
CM_ SG_ 2281701648 UWB_TRNK_DTC "UWB TRNK DTC Data";
CM_ SG_ 2281701648 L_UWB_TRNK_FD_AlvCnt10Val "L_UWB_TRNK_FD_AliveCounter10Value";
CM_ SG_ 2281701648 UWB_TRNK_Status1 "UWB_TRNK Processing Status 1";
CM_ SG_ 2281701648 UWB_TRNK_Status2 "UWB_TRNK Processing Status 2";
CM_ SG_ 2281701648 UWB_TRNK_Status3 "UWB_TRNK Processing Status 3";
CM_ SG_ 2281701648 UWB_TRNK_Status4 "UWB_TRNK Processing Status 4";
CM_ SG_ 2281701648 UWB_TRNK_Status5 "UWB_TRNK Processing Status 5";
CM_ SG_ 2281701648 UWB_TRNK_Status6 "UWB_TRNK Processing Status 6";
CM_ SG_ 2281701648 UWB_TRNK_Status7 "UWB_TRNK Processing Status 7";
CM_ SG_ 2281701648 UWB_TRNK_Status8 "UWB_TRNK Processing Status 8";
CM_ SG_ 2281701648 UWB_TRNK_Status9 "UWB_TRNK Processing Status 9";
CM_ SG_ 2281701648 UWB_TRNK_Status10 "UWB_TRNK Processing Status 10";
CM_ SG_ 2281701648 UWB_TRNK_Status11 "UWB_TRNK Processing Status 11";
CM_ SG_ 2281701648 UWB_TRNK_Status12 "UWB_TRNK Processing Status 12";
CM_ SG_ 2281701648 UWB_TRNK_Status13 "UWB_TRNK Processing Status 13";
CM_ SG_ 2281701648 UWB_TRNK_Status14 "UWB_TRNK Processing Status 14";
CM_ SG_ 2281701648 UWB_TRNK_Status15 "UWB_TRNK Processing Status 15";
CM_ SG_ 2281701648 UWB_TRNK_Status16 "UWB_TRNK Processing Status 16";
CM_ SG_ 2281701648 UWB_TRNK_HW_Ver_Major "UWB TRNK HW Version Major";
CM_ SG_ 2281701648 UWB_TRNK_HW_Ver_Minor "UWB TRNK HW Version Minor";
CM_ BO_ 2214592624 "[EC] On Event and On Change";
CM_ SG_ 2214592624 L_WPC_FD_Crc1Val "L_WPC_FD_CyclicRedundancyCheck1Value";
CM_ SG_ 2214592624 L_WPC_FD_AlvCnt1Val "L_WPC_FD_AliveCounter1Value";
CM_ SG_ 2214592624 WPC_NFCDetection_Sta "Indicate NFC Device is detected or not";
CM_ SG_ 2214592624 WPC_NFCReset_Sta "NFC Deselect Result";
CM_ SG_ 2214592624 WPC2_NFCDetection_Sta "Indicate NFC Device of WPC2 is detected or not  in Dual WPC";
CM_ SG_ 2214592624 WPC2_NFCReset_Sta "NFC Deselect Result of WPC2 in DUAL WPC";
CM_ BO_ 2281701664 "[PE] Periodic and On Event";
CM_ SG_ 2281701664 L_ROA_FD_Crc1Val "L_ROA_FD_CyclicRedundancyCheck1Value";
CM_ SG_ 2281701664 L_ROA_FD_AlvCnt1Val "L_ROA_FD_AliveCounter1Value";
CM_ SG_ 2281701664 ROA_SW_Ver_Major "Radar ROA SW Version Major";
CM_ SG_ 2281701664 ROA_SW_Ver_Minor1 "Radar ROA SW Version Minor1";
CM_ SG_ 2281701664 ROA_SW_Ver_Minor2 "Radar ROA SW Version Minor2";
CM_ SG_ 2281701664 ROA_ClassStat "ROA Sensor Status for diagnosis";
CM_ SG_ 2281701664 ROA_SnSrStat "ROA Sensor Status";
CM_ SG_ 2281701664 ROA_DetInfo "ROA Detection info";
CM_ SG_ 2281701664 ROA_SnSrBlckgeErrStat "ROA Sensor Blockage Error";
CM_ SG_ 2281701664 ROA_SnSrErrStat "ROA Internal Error";
CM_ BO_ 2281701666 "[PE] Periodic and On Event";
CM_ SG_ 2281701666 L_ROA_FR_FD_Crc1Val "L_ROA_FR_FD_CyclicRedundancyCheck1Value";
CM_ SG_ 2281701666 L_ROA_FR_FD_AlvCnt1Val "L_ROA_FR_FD_AliveCounter1Value";
CM_ SG_ 2281701666 ROA_FR_SW_Ver_Major "Radar ROA_FR SW Version Major";
CM_ SG_ 2281701666 ROA_FR_SW_Ver_Minor1 "Radar ROA_FR SW Version Minor1";
CM_ SG_ 2281701666 ROA_FR_SW_Ver_Minor2 "Radar ROA_FR SW Version Minor2";
CM_ SG_ 2281701666 ROA_FR_ClassStat "ROA_FR Sensor Status for diagnosis";
CM_ SG_ 2281701666 ROA_FR_SnSrStat "ROA_FR Sensor Status";
CM_ SG_ 2281701666 ROA_FR_DetInfo "ROA_FR Detection info";
CM_ SG_ 2281701666 ROA_FR_SnSrBlckgeErrStat "ROA_FR Sensor Blockage Error";
CM_ SG_ 2281701666 ROA_FR_SnSrErrStat "ROA_FR Internal Error";
CM_ BO_ 2214592608 "[EW] On Event and On Write";
CM_ SG_ 2214592608 L_BDC_FD_ROA_Crc2Val "L_BDC_FD_ROA_CyclicRedundancyCheck2Value";
CM_ SG_ 2214592608 L_BDC_FD_ROA_AlvCnt2Val "L_BDC_FD_ROA_AliveCounter2Value";
CM_ SG_ 2214592608 BDCROADataByte0 "Parameter Data";
CM_ SG_ 2214592608 BDCROADataByte1 "Parameter Data";
CM_ SG_ 2214592608 BDCROADataByte2 "Parameter Data";
CM_ SG_ 2214592608 BDCROADataByte3 "Parameter Data";
CM_ SG_ 2214592608 BDCROADataByte4 "Parameter Data";
CM_ SG_ 2214592608 BDCROADataByte5 "Parameter Data";
CM_ SG_ 2214592608 BDCROADataByte6 "Parameter Data";
CM_ SG_ 2214592608 BDCROADataByte7 "Parameter Data";
CM_ BO_ 2525341697 "[EW] On Event and On Write";
CM_ SG_ 2525341697 L_UWB_FR_FD_Crc4Val "L_UWB_FR_FD_CyclicRedundancyCheck4Value";
CM_ SG_ 2525341697 L_UWB_FR_FD_AlvCnt4Val "L_UWB_FR_FD_AliveCounter4Value";
CM_ SG_ 2525341697 FR_SWID_3_IVD_1 "UWB FR SW Unit 3 IVD1";
CM_ BO_ 2281701680 "[PE] Periodic and On Event";
CM_ SG_ 2281701680 L_SAL_FD_Crc1Val "L_SAL_FD_CyclicRedundancyCheck1Value";
CM_ SG_ 2281701680 SAL_BttmBrightnessDutyRatio "Current Brigthness duty ratio on Bottom area";
CM_ SG_ 2281701680 SAL_BttmFadeInTime "Current Fade in time on Bottom area";
CM_ SG_ 2281701680 SAL_BttmFadeOutTimeValue "Current Fade Out time on Bottom area";
CM_ SG_ 2281701680 SAL_MLNShiftModOptionState "N shift Option State";
CM_ SG_ 2281701680 L_SAL_FD_AlvCnt1Val "L_SAL_FD_AliveCounter1Value";
CM_ SG_ 2281701680 SAL_UPRColorXValue "Current Color X value on upr area";
CM_ SG_ 2281701680 SAL_UPRColorYValue "Curremt Color Y value on Upr area";
CM_ SG_ 2281701680 SAL_BrightnessDutyRatio "Current Brigthness duty ratio";
CM_ SG_ 2281701680 SAL_FadeInTime "Current Fade in time value";
CM_ SG_ 2281701680 SAL_FadeOutTimeValue "Current Fade out time value";
CM_ SG_ 2281701680 SAL_BttmColorXValue "Current Color X value on Bottom area";
CM_ SG_ 2281701680 SAL_BttmColorYValue "Current Color Y value on Bottom area";
CM_ BO_ 1025 "[PE] Periodic and On Event";
CM_ SG_ 1025 BDC_FD_SMK_Crc2Val "BDC_FD_SMK_CyclicRedundancyCheck2Value";
CM_ SG_ 1025 SMK_RpmLoByteVal_Copy_0 "SMK_RpmLowByteValue ##2G##SMK - SMKmsg65 - C_RPMLowByte";
CM_ SG_ 1025 SMK_VehSpdDrctVal_Copy_0 "SMK_VehicleSpeedDirectValue ##2G##SMK - SMKmsg65 - C_VehicleSpeedDirect";
CM_ SG_ 1025 Fob_BattStaInfo_Copy_0 "Fob_BatteryStatusInformation ##2G##SMK - SMKmsg17 - C_FOBBatteryStatusInfo";
CM_ SG_ 1025 Fob_FoundDrvWlcmArea_Copy_0 "Fob_FoundDriverWelcomeArea ##2G##SMK - SMKmsg17 - C_WelcomeFobFoundDrv";
CM_ SG_ 1025 Fob_FoundAsstWlcmArea_Copy_0 "Fob_FoundAssistWelcomeArea ##2G##SMK - SMKmsg17 - C_WelcomeFobFoundAst";
CM_ SG_ 1025 Fob_FoundExtrnlArea_Copy_0 "Fob_FoundExternalArea ##2G##SMK - SMKmsg18 - C_ExtFobPos";
CM_ SG_ 1025 Fob_FoundIntArea_Copy_0 "Fob_FoundInternalArea ##2G##SMK - SMKmsg18 - C_IntFobPos";
CM_ SG_ 1025 Fob_LearntSta_Copy_0 "Fob_LearntStatus ##2G##SMK - SMKmsg18 - C_FobLearntState";
CM_ SG_ 1025 RSPA_RFSigErrSta_Copy_0 "RSPA_RFSignalErrorState";
CM_ SG_ 1025 RSPA_CanErrSta_Copy_0 "RSPA_CANErrorState";
CM_ SG_ 1025 RSPA_ModSta_SMK_Copy_0 "RSPA_ModeStatus ##2G##SMK - SMKmsg18 - C_SMKRSPAMode";
CM_ SG_ 1025 RSPA_FobBattSta_Copy_0 "RSPA_FobBatteryStatus ##2G##SMK - SMKmsg18 - C_FobBATState";
CM_ SG_ 1025 Fob_FoundWlcmArea_Copy_0 "Fob_FoundWlcmArea ##2G##SMK - SMKmsg17 -C_FobFoundWlcmArea";
CM_ SG_ 1025 USM_WALModSta_Copy_0 "USM_WalkAwayLockModeStatus ##2G##SMK - SMKmsg20 - C_WALRValue";
CM_ SG_ 1025 USM_SmrtTrnkTlgtModSta_Copy_0 "USM_SmartTunkTailgateModeStatus ##2G##SMK - SMKmsg20 - C_HfreeTrunkTgRValue";
CM_ SG_ 1025 BDC_FD_SMK_AlvCnt2Val "BDC_FD_SMK_AliveCounter2Value";
CM_ SG_ 1025 SMK_ResultRmtStrt "This signal is used to check for Tele Engine Running Result.";
CM_ SG_ 1025 SMK_EncryptTeleOptSta "This signal is used to check for option applied Remote Start Encryption.";
CM_ SG_ 1025 Auth_ISKLearnSta2_Copy_0 "This signal is State of IAU Learning for New China BLE";
CM_ SG_ 1025 Auth_ISKLearnSta_Copy_0 "Fob_FoundAssistWelcomeArea ##2G##SMK - SMKmsg178 - C_IBUISKLearnState";
CM_ SG_ 1025 SMK_TlPwrOnSta_Copy_0 "This signal is state of Tele Power On";
CM_ SG_ 1025 SSB_StrtStpBtnSw1Sta_Copy_0 "SSB_StartStopButtonSwitch1Status ##2G##SMK - SMKmsg19 - C_SSBSW1";
CM_ SG_ 1025 SSB_StrtStpBtnSw2Sta_Copy_0 "SSB_StartStopButtonSwitch2Status ##2G##SMK - SMKmsg19 - C_SSBSW2";
CM_ SG_ 1025 SMK_AuthSta_Copy_0 "SMK_AuthentificationStatus ##2G##SMK - SMKmsg18 - C_AuthState";
CM_ SG_ 1025 SMK_TlPwrOnOpt_Copy_0 "This signal is used to check option status of Tele Power On";
CM_ SG_ 1025 SMK_Ign1InSta_Copy_0 "SMK_Ign1InputStatus ##2G##SMK - SMKmsg19 - C_Ign1SMK";
CM_ SG_ 1025 SMK_Ign1RlySta_Copy_0 "SMK_Ign1RelayStatus ##2G##SMK - SMKmsg19 - C_Ign1RelayState";
CM_ SG_ 1025 SMK_Ign2InSta_Copy_0 "SMK_Ign2InputStatus ##2G##SMK - SMKmsg19 - C_Ign2SMK";
CM_ SG_ 1025 SMK_Ign2RlySta_Copy_0 "SMK_Ign2RelayStatus ##2G##SMK - SMKmsg19 - C_Ign2RelayState";
CM_ SG_ 1025 SMK_StrtFdbckSta_Copy_0 "SMK_StartFeedbackStatus ##2G##SMK - SMKmsg19 - C_StartFeedback";
CM_ SG_ 1025 SMK_StrtrRlyOutSta_Copy_0 "SMK_StarterRelayOutputStatus ##2G##SMK - SMKmsg18 - C_StarterRlyState";
CM_ SG_ 1025 SMK_AccInSta_Copy_0 "SMK_AccInputStatus ##2G##SMK - SMKmsg19 - C_AccSMK";
CM_ SG_ 1025 SMK_AccRlySta_Copy_0 "SMK_AccRelayStatus ##2G##SMK - SMKmsg19 - C_AccRelayStatus";
CM_ SG_ 1025 SMK_CLUAccIndOnReq_Copy_0 "SMK_ClusterACCIndicatorOnRequest ##2G##SMK - SMKmsg19 - C_AccINDforCLU";
CM_ SG_ 1025 SMK_VDModeActSta_Copy_0 "SMK_VirtualDriverModeActState";
CM_ SG_ 1025 SMK_SCULckUnlckSta_Copy_0 "SCU Lock/Unlock Status";
CM_ SG_ 1025 SMK_TlEngRunSta_Copy_0 "SMK_TeleEngineRunStatus ##2G##SMK - SMKmsg18 - C_SMKTeleEngineRunning";
CM_ SG_ 1025 SMK_TlCrnkModSta_Copy_0 "SMK_TeleCrankingModeStatus ##2G##SMK - SMKmsg18 - C_SMKTeleCrankingState";
CM_ SG_ 1025 SMK_RmtKeyEngRunSta_Copy_0 "SMK_RemoteKeyEngineRunStatus";
CM_ SG_ 1025 SMK_RmtKeyCrnkModSta_Copy_0 "SMK_RemoteKeyCrankingModeStatus";
CM_ SG_ 1025 SMK_AsstTgglBtnSta_Copy_0 "SMK_AssistToggleButtonStatus ##2G##SMK - SMKmsg19 - C_AstToggleButton";
CM_ SG_ 1025 SMK_DrvTglBtnSta_Copy_0 "SMK_DriverToggleButtonStatus ##2G##SMK - SMKmsg19 - C_DrvToggleButton";
CM_ SG_ 1025 SMK_RrLftTglBtnSta_Copy_0 "SMK_RearLeftToggleButtonStatus ##2G##SMK - SMKmsg19 - C_RRDRVToggleButton";
CM_ SG_ 1025 SMK_RrRtTglBtnSta_Copy_0 "SMK_RearRightToggleButtonStatus ##2G##SMK - SMKmsg19 - C_RRASTToggleButton";
CM_ SG_ 1025 SMK_TgglBtnStuckSta_Copy_0 "SMK_ToggleButtonStuckStatus ##2G##SMK - SMKmsg18 - C_ToggleButtonStuck";
CM_ SG_ 1025 SMK_AsstDrHndUnLkSnsrSta_Copy_0 "SMK_AssistToggleButtonStatus ##2G##SMK - SMKmsg19 - C_ASTDoorUnLock";
CM_ SG_ 1025 SMK_BrkSwSta_Copy_0 "SMK_BrakeSwitchStatus ##2G##SMK - SMKmsg19 - C_BrakeSW";
CM_ SG_ 1025 SMK_GearPosPSwSta_Copy_0 "SMK_GearPositionPSwitchStatus ##2G##SMK - SMKmsg19 - C_PpositionClutch";
CM_ SG_ 1025 SMK_CltchIgnLkSwSta_Copy_0 "SMK_ClutchIgnLockSwitchStatus ##2G##SMK - SMKmsg19 - C_ClutchIgnLockSW";
CM_ SG_ 1025 SMK_DrvDrHndLkSnsrSta_Copy_0 "SMK_DriverToggleButtonStatus ##2G##SMK - SMKmsg19 - C_DRVDoorLock";
CM_ SG_ 1025 SMK_DrvDrHndUnLkSnsrSta_Copy_0 "SMK_AssistToggleButtonStatus ##2G##SMK - SMKmsg19 - C_DRVDoorUnlock";
CM_ SG_ 1025 SMK_AsstDrHndLkSnsrSta_Copy_0 "SMK_AssistToggleButtonStatus ##2G##SMK - SMKmsg19 - C_ASTDoorLock";
CM_ SG_ 1025 LFAnt_FltSta_Copy_0 "LFAntenna_FaultSatus ##2G##SMK - SMKmsg18 - C_LFANTState";
CM_ SG_ 1025 LFAnt_SrchSta_Copy_0 "LFAntenna_SearchingStatus ##2G##SMK - SMKmsg19 - C_LFSearchingOn";
CM_ SG_ 1025 Lamp_HzrdBlnkngSta_Copy_0 "Lamp_HazardBlinkingStatus ##2G##SMK - SMKmsg17 - C_HazardFromSMK";
CM_ SG_ 1025 Lamp_SmrtWlcmLtOnReq_Copy_0 "Lamp_SmartWelcomeLightOnRequest ##2G##SMK - SMKmsg17 - C_WlightOn";
CM_ SG_ 1025 SMK_RpmHiByteVal_Copy_0 "SMK_RpmHighByteValue ##2G##SMK - SMKmsg65 - C_RPMHighByte";
CM_ BO_ 2529540353 "[EW] On Event and On Write";
CM_ SG_ 2529540353 L_UWB_RR_FD_Crc5Val "L_UWB_RR_FD_CyclicRedundancyCheck5Value";
CM_ SG_ 2529540353 L_UWB_RR_FD_AlvCnt5Val "L_UWB_RR_FD_AliveCounter5Value";
CM_ SG_ 2529540353 RR_SWID_3_IVD_2 "UWB RR SW Unit 3 IVD2";
CM_ BO_ 2521142529 "[EW] On Event and On Write";
CM_ SG_ 2521142529 L_UWB_BLE_SLV_FD_Crc9Val "L_UWB_BLE_SLV_FD_CyclicRedundancyCheck9Value";
CM_ SG_ 2521142529 L_UWB_BLE_SLV_FD_AlvCnt9Val "L_UWB_BLE_SLV_FD_AliveCounter9Value";
CM_ SG_ 2521142529 SLV_SWID_2_IVD_1 "Slave SW Unit 2 IVD1";
CM_ BO_ 2533738753 "[EW] On Event and On Write";
CM_ SG_ 2533738753 L_UWB_FRNK_FD_Crc5Val "L_UWB_FRNK_FD_CyclicRedundancyCheck5Value";
CM_ SG_ 2533738753 L_UWB_FRNK_FD_AlvCnt5Val "L_UWB_FRNK_FD_AliveCounter5Value";
CM_ SG_ 2533738753 FRNK_SWID_3_IVD_2 "UWB FRNK SW Unit 3 IVD2";
CM_ BO_ 2529540865 "[EW] On Event and On Write";
CM_ SG_ 2529540865 L_UWB_RR_FD_Crc7Val "L_UWB_RR_FD_CyclicRedundancyCheck7Value";
CM_ SG_ 2529540865 L_UWB_RR_FD_AlvCnt7Val "L_UWB_RR_FD_AliveCounter7Value";
CM_ SG_ 2529540865 RR_SWID_4_IVD_2 "UWB RR SW Unit 4 IVD2";
CM_ BO_ 2521143041 "[EW] On Event and On Write";
CM_ SG_ 2521143041 L_UWB_BLE_SLV_FD_Crc11Val "L_UWB_BLE_SLV_FD_CyclicRedundancyCheck11Value";
CM_ SG_ 2521143041 L_UWB_BLE_SLV_FD_AlvCnt11Val "L_UWB_BLE_SLV_FD_AliveCounter11Value";
CM_ SG_ 2521143041 SLV_SWID_3_IVD_1 "Slave SW Unit 3 IVD1";
CM_ BO_ 2533739265 "[EW] On Event and On Write";
CM_ SG_ 2533739265 L_UWB_FRNK_FD_Crc7Val "L_UWB_FRNK_FD_CyclicRedundancyCheck7Value";
CM_ SG_ 2533739265 L_UWB_FRNK_FD_AlvCnt7Val "L_UWB_FRNK_FD_AliveCounter7Value";
CM_ SG_ 2533739265 FRNK_SWID_4_IVD_2 "UWB FRNK SW Unit 4 IVD2";
CM_ BO_ 2214593024 "[EW] On Event and On Write";
CM_ SG_ 2214593024 EDT_BLE_Dvp_Data "Development Message";
CM_ BO_ 2214593025 "[EW] On Event and On Write";
CM_ SG_ 2214593025 EDT_DH_Dvp_Data "Development Message";
CM_ BO_ 2214593026 "[EW] On Event and On Write";
CM_ SG_ 2214593026 EDT_UWB_Dvp_Data "Development Message";
CM_ BO_ 1087 "[EC] On Event and On Change";
CM_ SG_ 1087 CCU_01_Crc1Val "CCU_01_CyclicRedundancyCheck1Value";
CM_ SG_ 1087 CCU_01_AlvCnt1Val "CCU_01_AliveCounter1Value";
CM_ SG_ 1087 CCU_ForcedPowerOffReq "CCU sends this signal to ICU for  the power off logic according to the conditions(vehicle normal mode/there are non-sleep ECUs in 1 hour/all ECUs go into the sleep mode)";
CM_ BO_ 2214592730 "[EC] On Event and On Change";
CM_ SG_ 2214592730 L_UWB_BLE_SLV_FD_Crc22Val "L_UWB_BLE_SLV_FD_CyclicRedundancyCheck22Value";
CM_ SG_ 2214592730 L_UWB_BLE_SLV_FD_AlvCnt22Val "L_UWB_BLE_SLV_FD_AliveCounter22Value";
CM_ SG_ 2214592730 SLV_DisconnectDKID "Disconnected DK ID";
CM_ SG_ 2214592730 SLV_DisconnectReason "Disconnected Reason";
CM_ SG_ 2214592730 SLV_BLE_ErrorReturn "Slave BLE Error Data";
CM_ BO_ 2525340161 "[EW] On Event and On Write";
CM_ SG_ 2525340161 L_UWB_FL_FD_Crc6Val "L_UWB_FL_FD_CyclicRedundancyCheck6Value";
CM_ SG_ 2525340161 L_UWB_FL_FD_AlvCnt6Val "L_UWB_FL_FD_AliveCounter6Value";
CM_ SG_ 2525340161 FL_SWID_4_IVD_1 "UWB FL SW Unit 4 IVD1";
CM_ BO_ 2214592735 "[EW] On Event and On Write";
CM_ SG_ 2214592735 UWB_FR_Dvp_Data "Development Message";
CM_ BO_ 2214592720 "[EC] On Event and On Change";
CM_ SG_ 2214592720 L_UWB_FR_FD_Crc1Val "L_UWB_FR_FD_CyclicRedundancyCheck1Value";
CM_ SG_ 2214592720 L_UWB_FR_FD_AlvCnt1Val "L_UWB_FR_FD_AliveCounter1Value";
CM_ SG_ 2214592720 UWB_FR_UWB_Decrypt_FB "Decryption Feedback for UWB (to BDC)";
CM_ SG_ 2214592720 UWB_FR_MST_Decrypt_FB "UWB FR Decryption FeedBack (to Master)";
CM_ SG_ 2214592720 UWB_FR_OTA_Rsp "UWB FR OTA response";
CM_ SG_ 2214592720 UWB_FR_UWB_IC_Status "UWB IC Status Message";
CM_ BO_ 2214592721 "[EC] On Event and On Change";
CM_ SG_ 2214592721 L_UWB_FR_FD_Crc2Val "L_UWB_FR_FD_CyclicRedundancyCheck2Value";
CM_ SG_ 2214592721 L_UWB_FR_FD_AlvCnt2Val "L_UWB_FR_FD_AliveCounter2Value";
CM_ SG_ 2214592721 UWB_FR_FOB_RSD_Enc_Result "UWB Ranging Result with FOB";
BA_DEF_ BO_  "CANFD_BRS" ENUM  "0","1";
BA_DEF_ BO_  "GenMsgEVName" STRING ;
BA_DEF_ BU_  "NmAsrNodeIdentifier" HEX 0 255;
BA_DEF_ BU_  "NmAsrCanMsgReducedTime" INT 0 1000;
BA_DEF_  "NmAsrWaitBusSleepTime" INT 0 100000;
BA_DEF_  "NmAsrTimeoutTime" INT 0 100000;
BA_DEF_  "NmAsrRepeatMessageTime" INT 0 100000;
BA_DEF_  "NmAsrMessageCount" INT 0 255;
BA_DEF_  "NmAsrCanMsgCycleTime" INT 0 100;
BA_DEF_  "NmAsrBaseAddress" HEX 0 536870911;
BA_DEF_ BO_  "NmAsrMessage" ENUM  "No","Yes";
BA_DEF_ BO_  "DiagState" ENUM  "No","Yes";
BA_DEF_ BO_  "DiagResponse" ENUM  "No","Yes";
BA_DEF_ BO_  "DiagRequest" ENUM  "No","Yes";
BA_DEF_ BO_  "TpMessage" ENUM  "No","Yes";
BA_DEF_ BO_  "UsrMsgIDSforwardDeviation" INT 0 100;
BA_DEF_ BO_  "UsrMsgIDSbackwardDeviation" INT 50 1000;
BA_DEF_  "BusType" STRING ;
BA_DEF_  "DBName" STRING ;
BA_DEF_  "Baudrate" INT 50000 1000000;
BA_DEF_  "BRS" INT 0 1;
BA_DEF_  "GenEnvVarEndingDsp" STRING ;
BA_DEF_  "GenEnvVarEndingSnd" STRING ;
BA_DEF_  "GenEnvVarPrefix" STRING ;
BA_DEF_  "GenNWMApBusSleep" STRING ;
BA_DEF_  "GenNWMApCanNormal" STRING ;
BA_DEF_  "GenNWMApCanOff" STRING ;
BA_DEF_  "GenNWMApCanOn" STRING ;
BA_DEF_  "GenNWMApCanSleep" STRING ;
BA_DEF_  "GenNWMApCanWakeUp" STRING ;
BA_DEF_  "GenNWMGotoMode_Awake" STRING ;
BA_DEF_  "GenNWMGotoMode_BusSleep" STRING ;
BA_DEF_  "GenNWMSleepTime" INT 1375 1650;
BA_DEF_  "GenNWMTalkNM" STRING ;
BA_DEF_  "Manufacturer" STRING ;
BA_DEF_  "NmBaseAddress" HEX 0 2047;
BA_DEF_  "NmMessageCount" INT 0 128;
BA_DEF_  "NmType" STRING ;
BA_DEF_  "SamplePointMax" INT 50 85;
BA_DEF_  "SamplePointMin" INT 55 85;
BA_DEF_  "SyncJumpWidthMax" INT 1 8;
BA_DEF_  "SyncJumpWidthMin" INT 1 4;
BA_DEF_  "VersionDay" INT 1 31;
BA_DEF_  "VersionMonth" INT 1 12;
BA_DEF_  "VersionNumber" INT 0 999999;
BA_DEF_  "VersionNumberInternal" INT 0 9999;
BA_DEF_  "VersionWeek" INT 1 53;
BA_DEF_  "VersionYear" INT 0 9999;
BA_DEF_ BU_  "NmStationAddress" HEX 0 127;
BA_DEF_ BU_  "NmNode" ENUM  "No","Yes";
BA_DEF_ BU_  "GenNodSleepTime" INT 1375 1650;
BA_DEF_ BU_  "ILUsed" ENUM  "No","Yes";
BA_DEF_ BU_  "NmCAN" INT 1 2;
BA_DEF_ BU_  "NodeLayerModules" STRING ;
BA_DEF_ BU_  "NWM_Knoten" ENUM  "No","Yes";
BA_DEF_ BO_  "GenMsgCycleTime" INT 0 2000;
BA_DEF_ BO_  "GenMsgStartDelayTime" INT 0 2000;
BA_DEF_ BO_  "GenMsgSendType" ENUM  "Cyclic","NoMsgSendType";
BA_DEF_ BO_  "GenMsgCycleTimeFast" INT 0 500;
BA_DEF_ BO_  "GenMsgDelayTime" INT 0 20;
BA_DEF_ BO_  "GenMsgILSupport" ENUM  "No","Yes";
BA_DEF_ BO_  "GenMsgNrOfRepetition" INT 0 3;
BA_DEF_ BO_  "TpTxIndex" INT 0 65535;
BA_DEF_ BO_  "VFrameFormat" ENUM  "StandardCAN","ExtendedCAN","reserved","reserved","reserved","reserved","reserved","reserved","reserved","reserved","reserved","reserved","reserved","reserved","StandardCAN_FD","ExtendedCAN_FD";
BA_DEF_ SG_  "UserSigValidity" ENUM  "B+","ACC","IG","IG1","IG2","IG3","IG1 or IG2","IG1 or IG3","Undef";
BA_DEF_ SG_  "TimeoutValue" STRING ;
BA_DEF_ SG_  "UsrSigPurpose" ENUM  "Undef","FN","DIAG","DIAG(Req)","DIAG(Res)","DIAG(Func)","DEV","CCP","NM","TP";
BA_DEF_ SG_  "GenSigStartValue" INT 0 1215752192;
BA_DEF_ SG_  "NetworkRequest" ENUM  "Yes","No";
BA_DEF_ SG_  "NetworkRequestHoldingTime" INT 0 65535;
BA_DEF_ SG_  "Description" STRING ;
BA_DEF_ SG_  "Version" STRING ;
BA_DEF_ SG_  "GenSigEnvVarType" ENUM  "Int","Float","Undef";
BA_DEF_ SG_  "GenSigSendType" ENUM  "Cyclic","OnWrite","OnWriteWithRepetition","OnChange","OnChangeWithRepetition","IfActive","IfActiveWithRepetition","NoSigSendType","OnChangeAndIfActive","OnChangeAndIfActiveWithRepetition";
BA_DEF_ SG_  "GwSigLatencyTime" INT 0 65536;
BA_DEF_ SG_  "GwSigMissingSourceType" ENUM  "Undef","OldValue","DefaultValue","InitialValue";
BA_DEF_ SG_  "NWM-WakeupAllowed" ENUM  "<n.a.>";
BA_DEF_ SG_  "RoutingFactor" INT 1 1215752192;
BA_DEF_  "Datarate" INT 1000000 8000000;
BA_DEF_ SG_  "SystemSignalLongSymbol" STRING ;
BA_DEF_REL_ BU_SG_REL_  "GenSigTimeoutTime" INT 0 7000;
BA_DEF_DEF_  "CANFD_BRS" "1";
BA_DEF_DEF_  "GenMsgEVName" "@Signame";
BA_DEF_DEF_  "NmAsrNodeIdentifier" 0;
BA_DEF_DEF_  "NmAsrCanMsgReducedTime" 1000;
BA_DEF_DEF_  "NmAsrWaitBusSleepTime" 1500;
BA_DEF_DEF_  "NmAsrTimeoutTime" 1000;
BA_DEF_DEF_  "NmAsrRepeatMessageTime" 1200;
BA_DEF_DEF_  "NmAsrMessageCount" 255;
BA_DEF_DEF_  "NmAsrCanMsgCycleTime" 100;
BA_DEF_DEF_  "NmAsrBaseAddress" 402391040;
BA_DEF_DEF_  "NmAsrMessage" "No";
BA_DEF_DEF_  "DiagState" "No";
BA_DEF_DEF_  "DiagResponse" "No";
BA_DEF_DEF_  "DiagRequest" "No";
BA_DEF_DEF_  "TpMessage" "No";
BA_DEF_DEF_  "UsrMsgIDSforwardDeviation" 10;
BA_DEF_DEF_  "UsrMsgIDSbackwardDeviation" 100;
BA_DEF_DEF_  "BusType" "CAN FD";
BA_DEF_DEF_  "DBName" "";
BA_DEF_DEF_  "Baudrate" 500000;
BA_DEF_DEF_  "BRS" 1;
BA_DEF_DEF_  "GenEnvVarEndingDsp" "Dsp_";
BA_DEF_DEF_  "GenEnvVarEndingSnd" "_";
BA_DEF_DEF_  "GenEnvVarPrefix" "Env";
BA_DEF_DEF_  "GenNWMApBusSleep" "AppNmCanBusSleep()";
BA_DEF_DEF_  "GenNWMApCanNormal" "AppNmCanNormal()";
BA_DEF_DEF_  "GenNWMApCanOff" "ApplCanOffline()";
BA_DEF_DEF_  "GenNWMApCanOn" "ApplCanOnline()";
BA_DEF_DEF_  "GenNWMApCanSleep" "ApplNmCanSleep()";
BA_DEF_DEF_  "GenNWMApCanWakeUp" "ApplCanWakeUp()";
BA_DEF_DEF_  "GenNWMGotoMode_Awake" "GotoMode_Awake()";
BA_DEF_DEF_  "GenNWMGotoMode_BusSleep" "GotoMode_BusSleep()";
BA_DEF_DEF_  "GenNWMSleepTime" 1500;
BA_DEF_DEF_  "GenNWMTalkNM" "TalkNM()";
BA_DEF_DEF_  "Manufacturer" "HMC";
BA_DEF_DEF_  "NmBaseAddress" 1280;
BA_DEF_DEF_  "NmMessageCount" 128;
BA_DEF_DEF_  "NmType" "AsrNm";
BA_DEF_DEF_  "SamplePointMax" 80;
BA_DEF_DEF_  "SamplePointMin" 80;
BA_DEF_DEF_  "SyncJumpWidthMax" 3;
BA_DEF_DEF_  "SyncJumpWidthMin" 2;
BA_DEF_DEF_  "VersionDay" 1;
BA_DEF_DEF_  "VersionMonth" 1;
BA_DEF_DEF_  "VersionNumber" 0;
BA_DEF_DEF_  "VersionNumberInternal" 0;
BA_DEF_DEF_  "VersionWeek" 1;
BA_DEF_DEF_  "VersionYear" 0;
BA_DEF_DEF_  "NmStationAddress" 0;
BA_DEF_DEF_  "NmNode" "No";
BA_DEF_DEF_  "GenNodSleepTime" 1500;
BA_DEF_DEF_  "ILUsed" "Yes";
BA_DEF_DEF_  "NmCAN" 1;
BA_DEF_DEF_  "NodeLayerModules" "AsrNM33.DLL,CANoeILNLVector.DLL";
BA_DEF_DEF_  "NWM_Knoten" "Yes";
BA_DEF_DEF_  "GenMsgCycleTime" 200;
BA_DEF_DEF_  "GenMsgStartDelayTime" 0;
BA_DEF_DEF_  "GenMsgSendType" "NoMsgSendType";
BA_DEF_DEF_  "GenMsgCycleTimeFast" 40;
BA_DEF_DEF_  "GenMsgDelayTime" 20;
BA_DEF_DEF_  "GenMsgILSupport" "Yes";
BA_DEF_DEF_  "GenMsgNrOfRepetition" 3;
BA_DEF_DEF_  "TpTxIndex" 0;
BA_DEF_DEF_  "VFrameFormat" "StandardCAN";
BA_DEF_DEF_  "UserSigValidity" "IG";
BA_DEF_DEF_  "TimeoutValue" "";
BA_DEF_DEF_  "UsrSigPurpose" "FN";
BA_DEF_DEF_  "GenSigStartValue" 0;
BA_DEF_DEF_  "NetworkRequest" "No";
BA_DEF_DEF_  "NetworkRequestHoldingTime" 0;
BA_DEF_DEF_  "Description" "";
BA_DEF_DEF_  "Version" "";
BA_DEF_DEF_  "GenSigEnvVarType" "Undef";
BA_DEF_DEF_  "GenSigSendType" "NoSigSendType";
BA_DEF_DEF_  "GwSigLatencyTime" 40;
BA_DEF_DEF_  "GwSigMissingSourceType" "Undef";
BA_DEF_DEF_  "NWM-WakeupAllowed" "<n.a.>";
BA_DEF_DEF_  "RoutingFactor" 1;
BA_DEF_DEF_  "Datarate" 1000000;
BA_DEF_DEF_REL_ "GenSigTimeoutTime" 500;
BA_DEF_DEF_  "SystemSignalLongSymbol" "";
BA_ "VersionNumber" 240801;
BA_ "VersionYear" 1;
BA_ "DBName" "Local_FD_BDC";
BA_ "NmAsrNodeIdentifier" BU_ L_DHRR_FD 45;
BA_ "NmNode" BU_ L_DHRR_FD 1;
BA_ "NmStationAddress" BU_ L_DHRR_FD 45;
BA_ "NmAsrNodeIdentifier" BU_ L_UWB_BLE_MST_FD 32;
BA_ "NmNode" BU_ L_UWB_BLE_MST_FD 1;
BA_ "NmStationAddress" BU_ L_UWB_BLE_MST_FD 32;
BA_ "NmAsrNodeIdentifier" BU_ L_UWB_RR_FD 38;
BA_ "NmNode" BU_ L_UWB_RR_FD 1;
BA_ "NmStationAddress" BU_ L_UWB_RR_FD 38;
BA_ "NmAsrNodeIdentifier" BU_ L_UWB_BLE_SLV_FD 33;
BA_ "NmNode" BU_ L_UWB_BLE_SLV_FD 1;
BA_ "NmStationAddress" BU_ L_UWB_BLE_SLV_FD 33;
BA_ "NmAsrNodeIdentifier" BU_ L_UWB_FR_FD 35;
BA_ "NmNode" BU_ L_UWB_FR_FD 1;
BA_ "NmStationAddress" BU_ L_UWB_FR_FD 35;
BA_ "NmAsrNodeIdentifier" BU_ L_DHRL_FD 44;
BA_ "NmNode" BU_ L_DHRL_FD 1;
BA_ "NmStationAddress" BU_ L_DHRL_FD 44;
BA_ "NmAsrNodeIdentifier" BU_ L_UWB_TRNK_FD 39;
BA_ "NmNode" BU_ L_UWB_TRNK_FD 1;
BA_ "NmStationAddress" BU_ L_UWB_TRNK_FD 39;
BA_ "NmAsrNodeIdentifier" BU_ L_UWB_FRNK_FD 36;
BA_ "NmNode" BU_ L_UWB_FRNK_FD 1;
BA_ "NmStationAddress" BU_ L_UWB_FRNK_FD 36;
BA_ "NmAsrNodeIdentifier" BU_ L_UWB_FL_FD 34;
BA_ "NmNode" BU_ L_UWB_FL_FD 1;
BA_ "NmStationAddress" BU_ L_UWB_FL_FD 34;
BA_ "NmAsrNodeIdentifier" BU_ GW_BDC_FD 128;
BA_ "NmNode" BU_ GW_BDC_FD 1;
BA_ "NmStationAddress" BU_ GW_BDC_FD 128;
BA_ "NmAsrNodeIdentifier" BU_ L_UWB_RL_FD 37;
BA_ "NmNode" BU_ L_UWB_RL_FD 1;
BA_ "NmStationAddress" BU_ L_UWB_RL_FD 37;
BA_ "NmAsrNodeIdentifier" BU_ L_SAL_FD 169;
BA_ "NmNode" BU_ L_SAL_FD 1;
BA_ "NmStationAddress" BU_ L_SAL_FD 169;
BA_ "NmAsrNodeIdentifier" BU_ L_WPC_FD 30;
BA_ "NmNode" BU_ L_WPC_FD 1;
BA_ "NmStationAddress" BU_ L_WPC_FD 30;
BA_ "NmAsrNodeIdentifier" BU_ L_TPMS_FD 40;
BA_ "NmNode" BU_ L_TPMS_FD 1;
BA_ "NmStationAddress" BU_ L_TPMS_FD 40;
BA_ "NmAsrNodeIdentifier" BU_ L_DHL_FD 42;
BA_ "NmNode" BU_ L_DHL_FD 1;
BA_ "NmStationAddress" BU_ L_DHL_FD 42;
BA_ "NmAsrNodeIdentifier" BU_ L_DHR_FD 43;
BA_ "NmNode" BU_ L_DHR_FD 1;
BA_ "NmStationAddress" BU_ L_DHR_FD 43;
BA_ "GenMsgCycleTime" BO_ 2214592593 0;
BA_ "VFrameFormat" BO_ 2214592593 15;
BA_ "GenMsgCycleTime" BO_ 2214592592 0;
BA_ "VFrameFormat" BO_ 2214592592 15;
BA_ "GenMsgCycleTime" BO_ 2214592595 0;
BA_ "VFrameFormat" BO_ 2214592595 15;
BA_ "GenMsgCycleTime" BO_ 2214592594 0;
BA_ "VFrameFormat" BO_ 2214592594 15;
BA_ "GenMsgCycleTime" BO_ 2214592597 0;
BA_ "VFrameFormat" BO_ 2214592597 15;
BA_ "GenMsgCycleTime" BO_ 2214592596 0;
BA_ "VFrameFormat" BO_ 2214592596 15;
BA_ "GenMsgCycleTime" BO_ 2214592598 0;
BA_ "VFrameFormat" BO_ 2214592598 15;
BA_ "GenMsgSendType" BO_ 2281701632 0;
BA_ "VFrameFormat" BO_ 2281701632 15;
BA_ "GenMsgDelayTime" BO_ 2525342209 10;
BA_ "GenMsgCycleTime" BO_ 2525342209 0;
BA_ "VFrameFormat" BO_ 2525342209 15;
BA_ "GenMsgSendType" BO_ 2281701648 0;
BA_ "VFrameFormat" BO_ 2281701648 15;
BA_ "GenMsgCycleTime" BO_ 2214592624 0;
BA_ "VFrameFormat" BO_ 2214592624 15;
BA_ "GenMsgSendType" BO_ 2281701664 0;
BA_ "VFrameFormat" BO_ 2281701664 15;
BA_ "GenMsgSendType" BO_ 2281701666 0;
BA_ "VFrameFormat" BO_ 2281701666 15;
BA_ "GenMsgDelayTime" BO_ 2214592608 10;
BA_ "GenMsgCycleTime" BO_ 2214592608 0;
BA_ "VFrameFormat" BO_ 2214592608 15;
BA_ "GenMsgDelayTime" BO_ 2525341697 10;
BA_ "GenMsgCycleTime" BO_ 2525341697 0;
BA_ "VFrameFormat" BO_ 2525341697 15;
BA_ "GenMsgSendType" BO_ 2281701680 0;
BA_ "VFrameFormat" BO_ 2281701680 15;
BA_ "GenMsgStartDelayTime" BO_ 1025 30;
BA_ "GenMsgSendType" BO_ 1025 0;
BA_ "VFrameFormat" BO_ 1025 14;
BA_ "GenMsgDelayTime" BO_ 2529540353 10;
BA_ "GenMsgCycleTime" BO_ 2529540353 0;
BA_ "VFrameFormat" BO_ 2529540353 15;
BA_ "GenMsgDelayTime" BO_ 2521142529 10;
BA_ "GenMsgCycleTime" BO_ 2521142529 0;
BA_ "VFrameFormat" BO_ 2521142529 15;
BA_ "GenMsgDelayTime" BO_ 2533738753 10;
BA_ "GenMsgCycleTime" BO_ 2533738753 0;
BA_ "VFrameFormat" BO_ 2533738753 15;
BA_ "GenMsgDelayTime" BO_ 2529540865 10;
BA_ "GenMsgCycleTime" BO_ 2529540865 0;
BA_ "VFrameFormat" BO_ 2529540865 15;
BA_ "GenMsgDelayTime" BO_ 2521143041 10;
BA_ "GenMsgCycleTime" BO_ 2521143041 0;
BA_ "VFrameFormat" BO_ 2521143041 15;
BA_ "GenMsgDelayTime" BO_ 2533739265 10;
BA_ "GenMsgCycleTime" BO_ 2533739265 0;
BA_ "VFrameFormat" BO_ 2533739265 15;
BA_ "GenMsgDelayTime" BO_ 2214593024 10;
BA_ "GenMsgCycleTime" BO_ 2214593024 0;
BA_ "VFrameFormat" BO_ 2214593024 15;
BA_ "GenMsgDelayTime" BO_ 2214593025 10;
BA_ "GenMsgCycleTime" BO_ 2214593025 0;
BA_ "VFrameFormat" BO_ 2214593025 15;
BA_ "GenMsgDelayTime" BO_ 2214593026 10;
BA_ "GenMsgCycleTime" BO_ 2214593026 0;
BA_ "VFrameFormat" BO_ 2214593026 15;
BA_ "GenMsgCycleTime" BO_ 1087 0;
BA_ "VFrameFormat" BO_ 1087 14;
BA_ "GenMsgCycleTime" BO_ 2214592730 0;
BA_ "VFrameFormat" BO_ 2214592730 15;
BA_ "GenMsgDelayTime" BO_ 2525340161 10;
BA_ "GenMsgCycleTime" BO_ 2525340161 0;
BA_ "VFrameFormat" BO_ 2525340161 15;
BA_ "GenMsgDelayTime" BO_ 2214592735 10;
BA_ "GenMsgCycleTime" BO_ 2214592735 0;
BA_ "VFrameFormat" BO_ 2214592735 15;
BA_ "GenMsgCycleTime" BO_ 2214592720 0;
BA_ "VFrameFormat" BO_ 2214592720 15;
BA_ "GenMsgCycleTime" BO_ 2214592721 0;
BA_ "VFrameFormat" BO_ 2214592721 15;
BA_ "Version" SG_ 2214592593 L_BDC_FD_IAU_Crc2Val "23.01.02";
BA_ "UserSigValidity" SG_ 2214592593 L_BDC_FD_IAU_Crc2Val 3;
BA_ "GenSigStartValue" SG_ 2214592593 L_BDC_FD_IAU_Crc2Val 65535;
BA_ "GenSigSendType" SG_ 2214592593 L_BDC_FD_IAU_Crc2Val 4;
BA_ "Description" SG_ 2214592593 L_BDC_FD_IAU_Crc2Val "The data area for CRC calculation is based on the data length (DLC) of the message DB.

The CRC shall be calculated over the entire data block (excluding the CRC bytes) including the user data, alive counter and Data ID



- CRC Polynomial (0x1021) , Ini";
BA_ "Version" SG_ 2214592593 DKID_Del "23.01.02";
BA_ "UserSigValidity" SG_ 2214592593 DKID_Del 0;
BA_ "GenSigSendType" SG_ 2214592593 DKID_Del 4;
BA_ "Version" SG_ 2214592593 UWB_Ranging_Cmd_DKID "23.01.02";
BA_ "UserSigValidity" SG_ 2214592593 UWB_Ranging_Cmd_DKID 0;
BA_ "GenSigSendType" SG_ 2214592593 UWB_Ranging_Cmd_DKID 4;
BA_ "Version" SG_ 2214592593 UWB_Ranging_Cmd_Val "23.01.02";
BA_ "UserSigValidity" SG_ 2214592593 UWB_Ranging_Cmd_Val 0;
BA_ "GenSigSendType" SG_ 2214592593 UWB_Ranging_Cmd_Val 4;
BA_ "Version" SG_ 2214592593 L_BDC_FD_IAU_AlvCnt2Val "23.01.02";
BA_ "UserSigValidity" SG_ 2214592593 L_BDC_FD_IAU_AlvCnt2Val 3;
BA_ "GenSigSendType" SG_ 2214592593 L_BDC_FD_IAU_AlvCnt2Val 4;
BA_ "Description" SG_ 2214592593 L_BDC_FD_IAU_AlvCnt2Val "For the first transmission request for a data element the counter shall be initialized with 0 and shall be incremented by 1 for every subsequent send request. 

When the counter reaches the maximum value(0xFF), then it shall restart with 0 for the next s";
BA_ "Version" SG_ 2214592593 BDC_RndNum_Trgt "23.01.02";
BA_ "UserSigValidity" SG_ 2214592593 BDC_RndNum_Trgt 0;
BA_ "GenSigSendType" SG_ 2214592593 BDC_RndNum_Trgt 4;
BA_ "Version" SG_ 2214592593 BDC_RndNum_TRCod "23.01.02";
BA_ "UserSigValidity" SG_ 2214592593 BDC_RndNum_TRCod 0;
BA_ "GenSigSendType" SG_ 2214592593 BDC_RndNum_TRCod 4;
BA_ "Version" SG_ 2214592593 BDC_RndNum_Cmd "23.01.02";
BA_ "UserSigValidity" SG_ 2214592593 BDC_RndNum_Cmd 0;
BA_ "GenSigSendType" SG_ 2214592593 BDC_RndNum_Cmd 4;
BA_ "Version" SG_ 2214592593 BDC_RndNum "23.01.02";
BA_ "UserSigValidity" SG_ 2214592593 BDC_RndNum 0;
BA_ "GenSigSendType" SG_ 2214592593 BDC_RndNum 4;
BA_ "Version" SG_ 2214592593 BDC_Decrypt_FB "23.01.02";
BA_ "UserSigValidity" SG_ 2214592593 BDC_Decrypt_FB 0;
BA_ "GenSigSendType" SG_ 2214592593 BDC_Decrypt_FB 4;
BA_ "Version" SG_ 2214592593 DKID_Set "23.01.02";
BA_ "UserSigValidity" SG_ 2214592593 DKID_Set 0;
BA_ "GenSigSendType" SG_ 2214592593 DKID_Set 4;
BA_ "Version" SG_ 2214592592 L_BDC_FD_IAU_Crc1Val "23.01.02";
BA_ "UserSigValidity" SG_ 2214592592 L_BDC_FD_IAU_Crc1Val 3;
BA_ "GenSigStartValue" SG_ 2214592592 L_BDC_FD_IAU_Crc1Val 65535;
BA_ "GenSigSendType" SG_ 2214592592 L_BDC_FD_IAU_Crc1Val 4;
BA_ "Description" SG_ 2214592592 L_BDC_FD_IAU_Crc1Val "The data area for CRC calculation is based on the data length (DLC) of the message DB.

The CRC shall be calculated over the entire data block (excluding the CRC bytes) including the user data, alive counter and Data ID



- CRC Polynomial (0x1021) , Ini";
BA_ "Version" SG_ 2214592592 L_BDC_FD_IAU_AlvCnt1Val "23.01.02";
BA_ "UserSigValidity" SG_ 2214592592 L_BDC_FD_IAU_AlvCnt1Val 3;
BA_ "GenSigSendType" SG_ 2214592592 L_BDC_FD_IAU_AlvCnt1Val 4;
BA_ "Description" SG_ 2214592592 L_BDC_FD_IAU_AlvCnt1Val "For the first transmission request for a data element the counter shall be initialized with 0 and shall be incremented by 1 for every subsequent send request. 

When the counter reaches the maximum value(0xFF), then it shall restart with 0 for the next s";
BA_ "Version" SG_ 2214592592 WPC_NFC_Deselect_Cmd "23.01.02";
BA_ "UserSigValidity" SG_ 2214592592 WPC_NFC_Deselect_Cmd 0;
BA_ "GenSigSendType" SG_ 2214592592 WPC_NFC_Deselect_Cmd 4;
BA_ "Version" SG_ 2214592592 WPC2_NFC_Deselect_Cmd "24.06.01";
BA_ "UserSigValidity" SG_ 2214592592 WPC2_NFC_Deselect_Cmd 0;
BA_ "GenSigSendType" SG_ 2214592592 WPC2_NFC_Deselect_Cmd 4;
BA_ "Version" SG_ 2214592592 DHL_NFC_Deselect_Cmd "23.01.02";
BA_ "UserSigValidity" SG_ 2214592592 DHL_NFC_Deselect_Cmd 0;
BA_ "GenSigSendType" SG_ 2214592592 DHL_NFC_Deselect_Cmd 4;
BA_ "Version" SG_ 2214592592 DHR_NFC_Deselect_Cmd "23.01.02";
BA_ "UserSigValidity" SG_ 2214592592 DHR_NFC_Deselect_Cmd 0;
BA_ "GenSigSendType" SG_ 2214592592 DHR_NFC_Deselect_Cmd 4;
BA_ "Version" SG_ 2214592592 DHRL_NFC_Deselect_Cmd "23.06.01";
BA_ "UserSigValidity" SG_ 2214592592 DHRL_NFC_Deselect_Cmd 0;
BA_ "GenSigSendType" SG_ 2214592592 DHRL_NFC_Deselect_Cmd 4;
BA_ "Version" SG_ 2214592592 DHRR_NFC_Deselect_Cmd "23.06.01";
BA_ "UserSigValidity" SG_ 2214592592 DHRR_NFC_Deselect_Cmd 0;
BA_ "GenSigSendType" SG_ 2214592592 DHRR_NFC_Deselect_Cmd 4;
BA_ "Version" SG_ 2214592595 L_BDC_FD_IAU_Crc4Val "23.01.02";
BA_ "UserSigValidity" SG_ 2214592595 L_BDC_FD_IAU_Crc4Val 3;
BA_ "GenSigStartValue" SG_ 2214592595 L_BDC_FD_IAU_Crc4Val 65535;
BA_ "GenSigSendType" SG_ 2214592595 L_BDC_FD_IAU_Crc4Val 4;
BA_ "Description" SG_ 2214592595 L_BDC_FD_IAU_Crc4Val "The data area for CRC calculation is based on the data length (DLC) of the message DB.

The CRC shall be calculated over the entire data block (excluding the CRC bytes) including the user data, alive counter and Data ID



- CRC Polynomial (0x1021) , Ini";
BA_ "Version" SG_ 2214592595 L_BDC_FD_IAU_AlvCnt4Val "23.01.02";
BA_ "UserSigValidity" SG_ 2214592595 L_BDC_FD_IAU_AlvCnt4Val 3;
BA_ "GenSigSendType" SG_ 2214592595 L_BDC_FD_IAU_AlvCnt4Val 4;
BA_ "Description" SG_ 2214592595 L_BDC_FD_IAU_AlvCnt4Val "For the first transmission request for a data element the counter shall be initialized with 0 and shall be incremented by 1 for every subsequent send request. 

When the counter reaches the maximum value(0xFF), then it shall restart with 0 for the next s";
BA_ "Version" SG_ 2214592595 BDC_To_BLE_Enc_Data2 "23.01.02";
BA_ "UserSigValidity" SG_ 2214592595 BDC_To_BLE_Enc_Data2 0;
BA_ "GenSigSendType" SG_ 2214592595 BDC_To_BLE_Enc_Data2 4;
BA_ "Version" SG_ 2214592594 L_BDC_FD_IAU_Crc3Val "23.01.02";
BA_ "UserSigValidity" SG_ 2214592594 L_BDC_FD_IAU_Crc3Val 3;
BA_ "GenSigStartValue" SG_ 2214592594 L_BDC_FD_IAU_Crc3Val 65535;
BA_ "GenSigSendType" SG_ 2214592594 L_BDC_FD_IAU_Crc3Val 4;
BA_ "Description" SG_ 2214592594 L_BDC_FD_IAU_Crc3Val "The data area for CRC calculation is based on the data length (DLC) of the message DB.

The CRC shall be calculated over the entire data block (excluding the CRC bytes) including the user data, alive counter and Data ID



- CRC Polynomial (0x1021) , Ini";
BA_ "Version" SG_ 2214592594 L_BDC_FD_IAU_AlvCnt3Val "23.01.02";
BA_ "UserSigValidity" SG_ 2214592594 L_BDC_FD_IAU_AlvCnt3Val 3;
BA_ "GenSigSendType" SG_ 2214592594 L_BDC_FD_IAU_AlvCnt3Val 4;
BA_ "Description" SG_ 2214592594 L_BDC_FD_IAU_AlvCnt3Val "For the first transmission request for a data element the counter shall be initialized with 0 and shall be incremented by 1 for every subsequent send request. 

When the counter reaches the maximum value(0xFF), then it shall restart with 0 for the next s";
BA_ "Version" SG_ 2214592594 BDC_To_BLE_Enc_Data1 "23.01.02";
BA_ "UserSigValidity" SG_ 2214592594 BDC_To_BLE_Enc_Data1 0;
BA_ "GenSigSendType" SG_ 2214592594 BDC_To_BLE_Enc_Data1 4;
BA_ "Version" SG_ 2214592597 L_BDC_FD_IAU_Crc6Val "23.01.02";
BA_ "UserSigValidity" SG_ 2214592597 L_BDC_FD_IAU_Crc6Val 3;
BA_ "GenSigStartValue" SG_ 2214592597 L_BDC_FD_IAU_Crc6Val 65535;
BA_ "GenSigSendType" SG_ 2214592597 L_BDC_FD_IAU_Crc6Val 4;
BA_ "Description" SG_ 2214592597 L_BDC_FD_IAU_Crc6Val "The data area for CRC calculation is based on the data length (DLC) of the message DB.

The CRC shall be calculated over the entire data block (excluding the CRC bytes) including the user data, alive counter and Data ID



- CRC Polynomial (0x1021) , Ini";
BA_ "Version" SG_ 2214592597 L_BDC_FD_IAU_AlvCnt6Val "23.01.02";
BA_ "UserSigValidity" SG_ 2214592597 L_BDC_FD_IAU_AlvCnt6Val 3;
BA_ "GenSigSendType" SG_ 2214592597 L_BDC_FD_IAU_AlvCnt6Val 4;
BA_ "Description" SG_ 2214592597 L_BDC_FD_IAU_AlvCnt6Val "For the first transmission request for a data element the counter shall be initialized with 0 and shall be incremented by 1 for every subsequent send request. 

When the counter reaches the maximum value(0xFF), then it shall restart with 0 for the next s";
BA_ "Version" SG_ 2214592597 BDC_To_UWB_Enc_Data2 "23.01.02";
BA_ "UserSigValidity" SG_ 2214592597 BDC_To_UWB_Enc_Data2 0;
BA_ "GenSigSendType" SG_ 2214592597 BDC_To_UWB_Enc_Data2 4;
BA_ "Version" SG_ 2214592596 L_BDC_FD_IAU_Crc5Val "23.01.02";
BA_ "UserSigValidity" SG_ 2214592596 L_BDC_FD_IAU_Crc5Val 3;
BA_ "GenSigStartValue" SG_ 2214592596 L_BDC_FD_IAU_Crc5Val 65535;
BA_ "GenSigSendType" SG_ 2214592596 L_BDC_FD_IAU_Crc5Val 4;
BA_ "Description" SG_ 2214592596 L_BDC_FD_IAU_Crc5Val "The data area for CRC calculation is based on the data length (DLC) of the message DB.

The CRC shall be calculated over the entire data block (excluding the CRC bytes) including the user data, alive counter and Data ID



- CRC Polynomial (0x1021) , Ini";
BA_ "Version" SG_ 2214592596 L_BDC_FD_IAU_AlvCnt5Val "23.01.02";
BA_ "UserSigValidity" SG_ 2214592596 L_BDC_FD_IAU_AlvCnt5Val 3;
BA_ "GenSigSendType" SG_ 2214592596 L_BDC_FD_IAU_AlvCnt5Val 4;
BA_ "Description" SG_ 2214592596 L_BDC_FD_IAU_AlvCnt5Val "For the first transmission request for a data element the counter shall be initialized with 0 and shall be incremented by 1 for every subsequent send request. 

When the counter reaches the maximum value(0xFF), then it shall restart with 0 for the next s";
BA_ "Version" SG_ 2214592596 BDC_To_UWB_Enc_Data1 "23.01.02";
BA_ "UserSigValidity" SG_ 2214592596 BDC_To_UWB_Enc_Data1 0;
BA_ "GenSigSendType" SG_ 2214592596 BDC_To_UWB_Enc_Data1 4;
BA_ "Version" SG_ 2214592598 L_BDC_FD_IAU_Crc7Val "23.01.02";
BA_ "UserSigValidity" SG_ 2214592598 L_BDC_FD_IAU_Crc7Val 3;
BA_ "GenSigStartValue" SG_ 2214592598 L_BDC_FD_IAU_Crc7Val 65535;
BA_ "GenSigSendType" SG_ 2214592598 L_BDC_FD_IAU_Crc7Val 4;
BA_ "Description" SG_ 2214592598 L_BDC_FD_IAU_Crc7Val "The data area for CRC calculation is based on the data length (DLC) of the message DB.

The CRC shall be calculated over the entire data block (excluding the CRC bytes) including the user data, alive counter and Data ID



- CRC Polynomial (0x1021) , Ini";
BA_ "Version" SG_ 2214592598 L_BDC_FD_IAU_AlvCnt7Val "23.01.02";
BA_ "UserSigValidity" SG_ 2214592598 L_BDC_FD_IAU_AlvCnt7Val 3;
BA_ "GenSigSendType" SG_ 2214592598 L_BDC_FD_IAU_AlvCnt7Val 4;
BA_ "Description" SG_ 2214592598 L_BDC_FD_IAU_AlvCnt7Val "For the first transmission request for a data element the counter shall be initialized with 0 and shall be incremented by 1 for every subsequent send request. 

When the counter reaches the maximum value(0xFF), then it shall restart with 0 for the next s";
BA_ "Version" SG_ 2214592598 BDC_To_UWB_Enc_Data3 "23.01.02";
BA_ "UserSigValidity" SG_ 2214592598 BDC_To_UWB_Enc_Data3 0;
BA_ "GenSigSendType" SG_ 2214592598 BDC_To_UWB_Enc_Data3 4;
BA_ "Version" SG_ 2281701632 L_UWB_RR_FD_Crc10Val "23.01.02";
BA_ "UserSigValidity" SG_ 2281701632 L_UWB_RR_FD_Crc10Val 3;
BA_ "GenSigStartValue" SG_ 2281701632 L_UWB_RR_FD_Crc10Val 65535;
BA_ "GenSigSendType" SG_ 2281701632 L_UWB_RR_FD_Crc10Val 4;
BA_ "Description" SG_ 2281701632 L_UWB_RR_FD_Crc10Val "The data area for CRC calculation is based on the data length (DLC) of the message DB.

The CRC shall be calculated over the entire data block (excluding the CRC bytes) including the user data, alive counter and Data ID



- CRC Polynomial (0x1021) , Ini";
BA_ "Version" SG_ 2281701632 UWB_RR_SW_MCU_Ver_Major "23.01.02";
BA_ "UserSigValidity" SG_ 2281701632 UWB_RR_SW_MCU_Ver_Major 0;
BA_ "GenSigSendType" SG_ 2281701632 UWB_RR_SW_MCU_Ver_Major 4;
BA_ "Version" SG_ 2281701632 UWB_RR_SW_MCU_Ver_Minor "23.01.02";
BA_ "UserSigValidity" SG_ 2281701632 UWB_RR_SW_MCU_Ver_Minor 0;
BA_ "GenSigSendType" SG_ 2281701632 UWB_RR_SW_MCU_Ver_Minor 4;
BA_ "Version" SG_ 2281701632 UWB_RR_SW_IC_Ver_Major "23.01.02";
BA_ "UserSigValidity" SG_ 2281701632 UWB_RR_SW_IC_Ver_Major 0;
BA_ "GenSigSendType" SG_ 2281701632 UWB_RR_SW_IC_Ver_Major 4;
BA_ "Version" SG_ 2281701632 UWB_RR_SW_IC_Ver_Minor "23.01.02";
BA_ "UserSigValidity" SG_ 2281701632 UWB_RR_SW_IC_Ver_Minor 0;
BA_ "GenSigSendType" SG_ 2281701632 UWB_RR_SW_IC_Ver_Minor 4;
BA_ "Version" SG_ 2281701632 UWB_RR_DTC "23.01.02";
BA_ "UserSigValidity" SG_ 2281701632 UWB_RR_DTC 0;
BA_ "GenSigSendType" SG_ 2281701632 UWB_RR_DTC 4;
BA_ "Version" SG_ 2281701632 L_UWB_RR_FD_AlvCnt10Val "23.01.02";
BA_ "UserSigValidity" SG_ 2281701632 L_UWB_RR_FD_AlvCnt10Val 3;
BA_ "GenSigSendType" SG_ 2281701632 L_UWB_RR_FD_AlvCnt10Val 4;
BA_ "Description" SG_ 2281701632 L_UWB_RR_FD_AlvCnt10Val "For the first transmission request for a data element the counter shall be initialized with 0 and shall be incremented by 1 for every subsequent send request. 

When the counter reaches the maximum value(0xFF), then it shall restart with 0 for the next s";
BA_ "Version" SG_ 2281701632 UWB_RR_Status1 "24.04.04";
BA_ "UserSigValidity" SG_ 2281701632 UWB_RR_Status1 0;
BA_ "GenSigSendType" SG_ 2281701632 UWB_RR_Status1 4;
BA_ "Description" SG_ 2281701632 UWB_RR_Status1 "UWB_RR Processing Status 1";
BA_ "Version" SG_ 2281701632 UWB_RR_Status2 "24.04.04";
BA_ "UserSigValidity" SG_ 2281701632 UWB_RR_Status2 0;
BA_ "GenSigSendType" SG_ 2281701632 UWB_RR_Status2 4;
BA_ "Description" SG_ 2281701632 UWB_RR_Status2 "UWB_RR Processing Status 2";
BA_ "Version" SG_ 2281701632 UWB_RR_Status3 "24.04.04";
BA_ "UserSigValidity" SG_ 2281701632 UWB_RR_Status3 0;
BA_ "GenSigSendType" SG_ 2281701632 UWB_RR_Status3 4;
BA_ "Description" SG_ 2281701632 UWB_RR_Status3 "UWB_RR Processing Status 3";
BA_ "Version" SG_ 2281701632 UWB_RR_Status4 "24.04.04";
BA_ "UserSigValidity" SG_ 2281701632 UWB_RR_Status4 0;
BA_ "GenSigSendType" SG_ 2281701632 UWB_RR_Status4 4;
BA_ "Description" SG_ 2281701632 UWB_RR_Status4 "UWB_RR Processing Status 4";
BA_ "Version" SG_ 2281701632 UWB_RR_Status5 "24.04.04";
BA_ "UserSigValidity" SG_ 2281701632 UWB_RR_Status5 0;
BA_ "GenSigSendType" SG_ 2281701632 UWB_RR_Status5 4;
BA_ "Description" SG_ 2281701632 UWB_RR_Status5 "UWB_RR Processing Status 5";
BA_ "Version" SG_ 2281701632 UWB_RR_Status6 "24.04.04";
BA_ "UserSigValidity" SG_ 2281701632 UWB_RR_Status6 0;
BA_ "GenSigSendType" SG_ 2281701632 UWB_RR_Status6 4;
BA_ "Description" SG_ 2281701632 UWB_RR_Status6 "UWB_RR Processing Status 6";
BA_ "Version" SG_ 2281701632 UWB_RR_Status7 "24.04.04";
BA_ "UserSigValidity" SG_ 2281701632 UWB_RR_Status7 0;
BA_ "GenSigSendType" SG_ 2281701632 UWB_RR_Status7 4;
BA_ "Description" SG_ 2281701632 UWB_RR_Status7 "UWB_RR Processing Status 7";
BA_ "Version" SG_ 2281701632 UWB_RR_Status8 "24.04.04";
BA_ "UserSigValidity" SG_ 2281701632 UWB_RR_Status8 0;
BA_ "GenSigSendType" SG_ 2281701632 UWB_RR_Status8 4;
BA_ "Description" SG_ 2281701632 UWB_RR_Status8 "UWB_RR Processing Status 8";
BA_ "Version" SG_ 2281701632 UWB_RR_Status9 "24.04.04";
BA_ "UserSigValidity" SG_ 2281701632 UWB_RR_Status9 0;
BA_ "GenSigSendType" SG_ 2281701632 UWB_RR_Status9 4;
BA_ "Description" SG_ 2281701632 UWB_RR_Status9 "UWB_RR Processing Status 9";
BA_ "Version" SG_ 2281701632 UWB_RR_Status10 "24.04.04";
BA_ "UserSigValidity" SG_ 2281701632 UWB_RR_Status10 0;
BA_ "GenSigSendType" SG_ 2281701632 UWB_RR_Status10 4;
BA_ "Description" SG_ 2281701632 UWB_RR_Status10 "UWB_RR Processing Status 10";
BA_ "Version" SG_ 2281701632 UWB_RR_Status11 "24.04.04";
BA_ "UserSigValidity" SG_ 2281701632 UWB_RR_Status11 0;
BA_ "GenSigSendType" SG_ 2281701632 UWB_RR_Status11 4;
BA_ "Description" SG_ 2281701632 UWB_RR_Status11 "UWB_RR Processing Status 11";
BA_ "Version" SG_ 2281701632 UWB_RR_Status12 "24.04.04";
BA_ "UserSigValidity" SG_ 2281701632 UWB_RR_Status12 0;
BA_ "GenSigSendType" SG_ 2281701632 UWB_RR_Status12 4;
BA_ "Description" SG_ 2281701632 UWB_RR_Status12 "UWB_RR Processing Status 12";
BA_ "Version" SG_ 2281701632 UWB_RR_Status13 "24.04.04";
BA_ "UserSigValidity" SG_ 2281701632 UWB_RR_Status13 0;
BA_ "GenSigSendType" SG_ 2281701632 UWB_RR_Status13 4;
BA_ "Description" SG_ 2281701632 UWB_RR_Status13 "UWB_RR Processing Status 13";
BA_ "Version" SG_ 2281701632 UWB_RR_Status14 "24.04.04";
BA_ "UserSigValidity" SG_ 2281701632 UWB_RR_Status14 0;
BA_ "GenSigSendType" SG_ 2281701632 UWB_RR_Status14 4;
BA_ "Description" SG_ 2281701632 UWB_RR_Status14 "UWB_RR Processing Status 14";
BA_ "Version" SG_ 2281701632 UWB_RR_Status15 "24.04.04";
BA_ "UserSigValidity" SG_ 2281701632 UWB_RR_Status15 0;
BA_ "GenSigSendType" SG_ 2281701632 UWB_RR_Status15 4;
BA_ "Description" SG_ 2281701632 UWB_RR_Status15 "UWB_RR Processing Status 15";
BA_ "Version" SG_ 2281701632 UWB_RR_Status16 "24.04.04";
BA_ "UserSigValidity" SG_ 2281701632 UWB_RR_Status16 0;
BA_ "GenSigSendType" SG_ 2281701632 UWB_RR_Status16 4;
BA_ "Description" SG_ 2281701632 UWB_RR_Status16 "UWB_RR Processing Status 16";
BA_ "Version" SG_ 2281701632 UWB_RR_HW_Ver_Major "23.01.02";
BA_ "UserSigValidity" SG_ 2281701632 UWB_RR_HW_Ver_Major 0;
BA_ "GenSigSendType" SG_ 2281701632 UWB_RR_HW_Ver_Major 4;
BA_ "Version" SG_ 2281701632 UWB_RR_HW_Ver_Minor "23.01.02";
BA_ "UserSigValidity" SG_ 2281701632 UWB_RR_HW_Ver_Minor 0;
BA_ "GenSigSendType" SG_ 2281701632 UWB_RR_HW_Ver_Minor 4;
BA_ "Version" SG_ 2525342209 L_UWB_FR_FD_Crc6Val "24.07.05";
BA_ "RoutingFactor" SG_ 2525342209 L_UWB_FR_FD_Crc6Val 0;
BA_ "UserSigValidity" SG_ 2525342209 L_UWB_FR_FD_Crc6Val 3;
BA_ "GenSigStartValue" SG_ 2525342209 L_UWB_FR_FD_Crc6Val 65535;
BA_ "GenSigSendType" SG_ 2525342209 L_UWB_FR_FD_Crc6Val 2;
BA_ "Description" SG_ 2525342209 L_UWB_FR_FD_Crc6Val "The data area for CRC calculation is based on the data length (DLC) of the message DB.

The CRC shall be calculated over the entire data block (excluding the CRC bytes) including the user data, alive counter and Data ID



- CRC Polynomial (0x1021) , Ini";
BA_ "Version" SG_ 2525342209 L_UWB_FR_FD_AlvCnt6Val "24.07.05";
BA_ "RoutingFactor" SG_ 2525342209 L_UWB_FR_FD_AlvCnt6Val 0;
BA_ "UserSigValidity" SG_ 2525342209 L_UWB_FR_FD_AlvCnt6Val 3;
BA_ "GenSigSendType" SG_ 2525342209 L_UWB_FR_FD_AlvCnt6Val 2;
BA_ "Description" SG_ 2525342209 L_UWB_FR_FD_AlvCnt6Val "For the first transmission request for a data element the counter shall be initialized with 0 and shall be incremented by 1 for every subsequent send request. 

When the counter reaches the maximum value(0xFF), then it shall restart with 0 for the next s";
BA_ "Version" SG_ 2525342209 FR_SWID_4_IVD_1 "24.07.05";
BA_ "RoutingFactor" SG_ 2525342209 FR_SWID_4_IVD_1 0;
BA_ "UserSigValidity" SG_ 2525342209 FR_SWID_4_IVD_1 0;
BA_ "GenSigSendType" SG_ 2525342209 FR_SWID_4_IVD_1 2;
BA_ "Version" SG_ 2281701648 L_UWB_TRNK_FD_Crc10Val "23.01.02";
BA_ "UserSigValidity" SG_ 2281701648 L_UWB_TRNK_FD_Crc10Val 3;
BA_ "GenSigStartValue" SG_ 2281701648 L_UWB_TRNK_FD_Crc10Val 65535;
BA_ "GenSigSendType" SG_ 2281701648 L_UWB_TRNK_FD_Crc10Val 4;
BA_ "Description" SG_ 2281701648 L_UWB_TRNK_FD_Crc10Val "The data area for CRC calculation is based on the data length (DLC) of the message DB.

The CRC shall be calculated over the entire data block (excluding the CRC bytes) including the user data, alive counter and Data ID



- CRC Polynomial (0x1021) , Ini";
BA_ "Version" SG_ 2281701648 UWB_TRNK_SW_MCU_Ver_Major "23.01.02";
BA_ "UserSigValidity" SG_ 2281701648 UWB_TRNK_SW_MCU_Ver_Major 0;
BA_ "GenSigSendType" SG_ 2281701648 UWB_TRNK_SW_MCU_Ver_Major 4;
BA_ "Version" SG_ 2281701648 UWB_TRNK_SW_MCU_Ver_Minor "23.01.02";
BA_ "UserSigValidity" SG_ 2281701648 UWB_TRNK_SW_MCU_Ver_Minor 0;
BA_ "GenSigSendType" SG_ 2281701648 UWB_TRNK_SW_MCU_Ver_Minor 4;
BA_ "Version" SG_ 2281701648 UWB_TRNK_SW_IC_Ver_Major "23.01.02";
BA_ "UserSigValidity" SG_ 2281701648 UWB_TRNK_SW_IC_Ver_Major 0;
BA_ "GenSigSendType" SG_ 2281701648 UWB_TRNK_SW_IC_Ver_Major 4;
BA_ "Version" SG_ 2281701648 UWB_TRNK_SW_IC_Ver_Minor "23.01.02";
BA_ "UserSigValidity" SG_ 2281701648 UWB_TRNK_SW_IC_Ver_Minor 0;
BA_ "GenSigSendType" SG_ 2281701648 UWB_TRNK_SW_IC_Ver_Minor 4;
BA_ "Version" SG_ 2281701648 UWB_TRNK_DTC "23.01.02";
BA_ "UserSigValidity" SG_ 2281701648 UWB_TRNK_DTC 0;
BA_ "GenSigSendType" SG_ 2281701648 UWB_TRNK_DTC 4;
BA_ "Version" SG_ 2281701648 L_UWB_TRNK_FD_AlvCnt10Val "23.01.02";
BA_ "UserSigValidity" SG_ 2281701648 L_UWB_TRNK_FD_AlvCnt10Val 3;
BA_ "GenSigSendType" SG_ 2281701648 L_UWB_TRNK_FD_AlvCnt10Val 4;
BA_ "Description" SG_ 2281701648 L_UWB_TRNK_FD_AlvCnt10Val "For the first transmission request for a data element the counter shall be initialized with 0 and shall be incremented by 1 for every subsequent send request. 

When the counter reaches the maximum value(0xFF), then it shall restart with 0 for the next s";
BA_ "Version" SG_ 2281701648 UWB_TRNK_Status1 "24.04.04";
BA_ "UserSigValidity" SG_ 2281701648 UWB_TRNK_Status1 0;
BA_ "GenSigSendType" SG_ 2281701648 UWB_TRNK_Status1 4;
BA_ "Description" SG_ 2281701648 UWB_TRNK_Status1 "UWB_TRNK Processing Status 1";
BA_ "Version" SG_ 2281701648 UWB_TRNK_Status2 "24.04.04";
BA_ "UserSigValidity" SG_ 2281701648 UWB_TRNK_Status2 0;
BA_ "GenSigSendType" SG_ 2281701648 UWB_TRNK_Status2 4;
BA_ "Description" SG_ 2281701648 UWB_TRNK_Status2 "UWB_TRNK Processing Status 2";
BA_ "Version" SG_ 2281701648 UWB_TRNK_Status3 "24.04.04";
BA_ "UserSigValidity" SG_ 2281701648 UWB_TRNK_Status3 0;
BA_ "GenSigSendType" SG_ 2281701648 UWB_TRNK_Status3 4;
BA_ "Description" SG_ 2281701648 UWB_TRNK_Status3 "UWB_TRNK Processing Status 3";
BA_ "Version" SG_ 2281701648 UWB_TRNK_Status4 "24.04.04";
BA_ "UserSigValidity" SG_ 2281701648 UWB_TRNK_Status4 0;
BA_ "GenSigSendType" SG_ 2281701648 UWB_TRNK_Status4 4;
BA_ "Description" SG_ 2281701648 UWB_TRNK_Status4 "UWB_TRNK Processing Status 4";
BA_ "Version" SG_ 2281701648 UWB_TRNK_Status5 "24.04.04";
BA_ "UserSigValidity" SG_ 2281701648 UWB_TRNK_Status5 0;
BA_ "GenSigSendType" SG_ 2281701648 UWB_TRNK_Status5 4;
BA_ "Description" SG_ 2281701648 UWB_TRNK_Status5 "UWB_TRNK Processing Status 5";
BA_ "Version" SG_ 2281701648 UWB_TRNK_Status6 "24.04.04";
BA_ "UserSigValidity" SG_ 2281701648 UWB_TRNK_Status6 0;
BA_ "GenSigSendType" SG_ 2281701648 UWB_TRNK_Status6 4;
BA_ "Description" SG_ 2281701648 UWB_TRNK_Status6 "UWB_TRNK Processing Status 6";
BA_ "Version" SG_ 2281701648 UWB_TRNK_Status7 "24.04.04";
BA_ "UserSigValidity" SG_ 2281701648 UWB_TRNK_Status7 0;
BA_ "GenSigSendType" SG_ 2281701648 UWB_TRNK_Status7 4;
BA_ "Description" SG_ 2281701648 UWB_TRNK_Status7 "UWB_TRNK Processing Status 7";
BA_ "Version" SG_ 2281701648 UWB_TRNK_Status8 "24.04.04";
BA_ "UserSigValidity" SG_ 2281701648 UWB_TRNK_Status8 0;
BA_ "GenSigSendType" SG_ 2281701648 UWB_TRNK_Status8 4;
BA_ "Description" SG_ 2281701648 UWB_TRNK_Status8 "UWB_TRNK Processing Status 8";
BA_ "Version" SG_ 2281701648 UWB_TRNK_Status9 "24.04.04";
BA_ "UserSigValidity" SG_ 2281701648 UWB_TRNK_Status9 0;
BA_ "GenSigSendType" SG_ 2281701648 UWB_TRNK_Status9 4;
BA_ "Description" SG_ 2281701648 UWB_TRNK_Status9 "UWB_TRNK Processing Status 9";
BA_ "Version" SG_ 2281701648 UWB_TRNK_Status10 "24.04.04";
BA_ "UserSigValidity" SG_ 2281701648 UWB_TRNK_Status10 0;
BA_ "GenSigSendType" SG_ 2281701648 UWB_TRNK_Status10 4;
BA_ "Description" SG_ 2281701648 UWB_TRNK_Status10 "UWB_TRNK Processing Status 10";
BA_ "Version" SG_ 2281701648 UWB_TRNK_Status11 "24.04.04";
BA_ "UserSigValidity" SG_ 2281701648 UWB_TRNK_Status11 0;
BA_ "GenSigSendType" SG_ 2281701648 UWB_TRNK_Status11 4;
BA_ "Description" SG_ 2281701648 UWB_TRNK_Status11 "UWB_TRNK Processing Status 11";
BA_ "Version" SG_ 2281701648 UWB_TRNK_Status12 "24.04.04";
BA_ "UserSigValidity" SG_ 2281701648 UWB_TRNK_Status12 0;
BA_ "GenSigSendType" SG_ 2281701648 UWB_TRNK_Status12 4;
BA_ "Description" SG_ 2281701648 UWB_TRNK_Status12 "UWB_TRNK Processing Status 12";
BA_ "Version" SG_ 2281701648 UWB_TRNK_Status13 "24.04.04";
BA_ "UserSigValidity" SG_ 2281701648 UWB_TRNK_Status13 0;
BA_ "GenSigSendType" SG_ 2281701648 UWB_TRNK_Status13 4;
BA_ "Description" SG_ 2281701648 UWB_TRNK_Status13 "UWB_TRNK Processing Status 13";
BA_ "Version" SG_ 2281701648 UWB_TRNK_Status14 "24.04.04";
BA_ "UserSigValidity" SG_ 2281701648 UWB_TRNK_Status14 0;
BA_ "GenSigSendType" SG_ 2281701648 UWB_TRNK_Status14 4;
BA_ "Description" SG_ 2281701648 UWB_TRNK_Status14 "UWB_TRNK Processing Status 14";
BA_ "Version" SG_ 2281701648 UWB_TRNK_Status15 "24.04.04";
BA_ "UserSigValidity" SG_ 2281701648 UWB_TRNK_Status15 0;
BA_ "GenSigSendType" SG_ 2281701648 UWB_TRNK_Status15 4;
BA_ "Description" SG_ 2281701648 UWB_TRNK_Status15 "UWB_TRNK Processing Status 15";
BA_ "Version" SG_ 2281701648 UWB_TRNK_Status16 "24.04.04";
BA_ "UserSigValidity" SG_ 2281701648 UWB_TRNK_Status16 0;
BA_ "GenSigSendType" SG_ 2281701648 UWB_TRNK_Status16 4;
BA_ "Description" SG_ 2281701648 UWB_TRNK_Status16 "UWB_TRNK Processing Status 16";
BA_ "Version" SG_ 2281701648 UWB_TRNK_HW_Ver_Major "23.01.02";
BA_ "UserSigValidity" SG_ 2281701648 UWB_TRNK_HW_Ver_Major 0;
BA_ "GenSigSendType" SG_ 2281701648 UWB_TRNK_HW_Ver_Major 4;
BA_ "Version" SG_ 2281701648 UWB_TRNK_HW_Ver_Minor "23.01.02";
BA_ "UserSigValidity" SG_ 2281701648 UWB_TRNK_HW_Ver_Minor 0;
BA_ "GenSigSendType" SG_ 2281701648 UWB_TRNK_HW_Ver_Minor 4;
BA_ "Version" SG_ 2214592624 L_WPC_FD_Crc1Val "23.01.02";
BA_ "UserSigValidity" SG_ 2214592624 L_WPC_FD_Crc1Val 3;
BA_ "GenSigStartValue" SG_ 2214592624 L_WPC_FD_Crc1Val 65535;
BA_ "GenSigSendType" SG_ 2214592624 L_WPC_FD_Crc1Val 4;
BA_ "Description" SG_ 2214592624 L_WPC_FD_Crc1Val "The data area for CRC calculation is based on the data length (DLC) of the message DB.

The CRC shall be calculated over the entire data block (excluding the CRC bytes) including the user data, alive counter and Data ID



- CRC Polynomial (0x1021) , Ini";
BA_ "Version" SG_ 2214592624 L_WPC_FD_AlvCnt1Val "23.01.02";
BA_ "UserSigValidity" SG_ 2214592624 L_WPC_FD_AlvCnt1Val 3;
BA_ "GenSigSendType" SG_ 2214592624 L_WPC_FD_AlvCnt1Val 4;
BA_ "Description" SG_ 2214592624 L_WPC_FD_AlvCnt1Val "For the first transmission request for a data element the counter shall be initialized with 0 and shall be incremented by 1 for every subsequent send request. 

When the counter reaches the maximum value(0xFF), then it shall restart with 0 for the next s";
BA_ "Version" SG_ 2214592624 WPC_NFCDetection_Sta "23.01.02";
BA_ "UserSigValidity" SG_ 2214592624 WPC_NFCDetection_Sta 0;
BA_ "GenSigSendType" SG_ 2214592624 WPC_NFCDetection_Sta 4;
BA_ "Version" SG_ 2214592624 WPC_NFCReset_Sta "23.01.02";
BA_ "UserSigValidity" SG_ 2214592624 WPC_NFCReset_Sta 0;
BA_ "GenSigSendType" SG_ 2214592624 WPC_NFCReset_Sta 4;
BA_ "Version" SG_ 2214592624 WPC2_NFCDetection_Sta "24.07.02";
BA_ "UserSigValidity" SG_ 2214592624 WPC2_NFCDetection_Sta 0;
BA_ "GenSigSendType" SG_ 2214592624 WPC2_NFCDetection_Sta 4;
BA_ "Version" SG_ 2214592624 WPC2_NFCReset_Sta "24.07.02";
BA_ "UserSigValidity" SG_ 2214592624 WPC2_NFCReset_Sta 0;
BA_ "GenSigSendType" SG_ 2214592624 WPC2_NFCReset_Sta 4;
BA_ "Version" SG_ 2281701664 L_ROA_FD_Crc1Val "23.01.03";
BA_ "UserSigValidity" SG_ 2281701664 L_ROA_FD_Crc1Val 3;
BA_ "GenSigStartValue" SG_ 2281701664 L_ROA_FD_Crc1Val 65535;
BA_ "GenSigSendType" SG_ 2281701664 L_ROA_FD_Crc1Val 4;
BA_ "Description" SG_ 2281701664 L_ROA_FD_Crc1Val "The data area for CRC calculation is based on the data length (DLC) of the message DB.

The CRC shall be calculated over the entire data block (excluding the CRC bytes) including the user data, alive counter and Data ID



- CRC Polynomial (0x1021) , Ini";
BA_ "Version" SG_ 2281701664 L_ROA_FD_AlvCnt1Val "23.01.03";
BA_ "UserSigValidity" SG_ 2281701664 L_ROA_FD_AlvCnt1Val 3;
BA_ "GenSigSendType" SG_ 2281701664 L_ROA_FD_AlvCnt1Val 4;
BA_ "Description" SG_ 2281701664 L_ROA_FD_AlvCnt1Val "For the first transmission request for a data element the counter shall be initialized with 0 and shall be incremented by 1 for every subsequent send request. 

When the counter reaches the maximum value(0xFF), then it shall restart with 0 for the next s";
BA_ "Version" SG_ 2281701664 ROA_SW_Ver_Major "23.01.03";
BA_ "UserSigValidity" SG_ 2281701664 ROA_SW_Ver_Major 0;
BA_ "GenSigSendType" SG_ 2281701664 ROA_SW_Ver_Major 4;
BA_ "Version" SG_ 2281701664 ROA_SW_Ver_Minor1 "23.01.03";
BA_ "UserSigValidity" SG_ 2281701664 ROA_SW_Ver_Minor1 0;
BA_ "GenSigSendType" SG_ 2281701664 ROA_SW_Ver_Minor1 4;
BA_ "Version" SG_ 2281701664 ROA_SW_Ver_Minor2 "23.01.03";
BA_ "UserSigValidity" SG_ 2281701664 ROA_SW_Ver_Minor2 0;
BA_ "GenSigSendType" SG_ 2281701664 ROA_SW_Ver_Minor2 4;
BA_ "Version" SG_ 2281701664 ROA_ClassStat "23.01.03";
BA_ "UserSigValidity" SG_ 2281701664 ROA_ClassStat 0;
BA_ "GenSigSendType" SG_ 2281701664 ROA_ClassStat 4;
BA_ "Version" SG_ 2281701664 ROA_SnSrStat "23.01.03";
BA_ "UserSigValidity" SG_ 2281701664 ROA_SnSrStat 0;
BA_ "GenSigSendType" SG_ 2281701664 ROA_SnSrStat 4;
BA_ "Version" SG_ 2281701664 ROA_DetInfo "23.01.03";
BA_ "UserSigValidity" SG_ 2281701664 ROA_DetInfo 0;
BA_ "GenSigSendType" SG_ 2281701664 ROA_DetInfo 4;
BA_ "Version" SG_ 2281701664 ROA_SnSrBlckgeErrStat "23.01.03";
BA_ "UserSigValidity" SG_ 2281701664 ROA_SnSrBlckgeErrStat 0;
BA_ "GenSigSendType" SG_ 2281701664 ROA_SnSrBlckgeErrStat 4;
BA_ "Version" SG_ 2281701664 ROA_SnSrErrStat "23.01.03";
BA_ "UserSigValidity" SG_ 2281701664 ROA_SnSrErrStat 0;
BA_ "GenSigSendType" SG_ 2281701664 ROA_SnSrErrStat 4;
BA_ "Version" SG_ 2281701666 L_ROA_FR_FD_Crc1Val "23.01.03";
BA_ "UserSigValidity" SG_ 2281701666 L_ROA_FR_FD_Crc1Val 3;
BA_ "GenSigStartValue" SG_ 2281701666 L_ROA_FR_FD_Crc1Val 65535;
BA_ "GenSigSendType" SG_ 2281701666 L_ROA_FR_FD_Crc1Val 4;
BA_ "Description" SG_ 2281701666 L_ROA_FR_FD_Crc1Val "The data area for CRC calculation is based on the data length (DLC) of the message DB.

The CRC shall be calculated over the entire data block (excluding the CRC bytes) including the user data, alive counter and Data ID



- CRC Polynomial (0x1021) , Ini";
BA_ "Version" SG_ 2281701666 L_ROA_FR_FD_AlvCnt1Val "23.01.03";
BA_ "UserSigValidity" SG_ 2281701666 L_ROA_FR_FD_AlvCnt1Val 3;
BA_ "GenSigSendType" SG_ 2281701666 L_ROA_FR_FD_AlvCnt1Val 4;
BA_ "Description" SG_ 2281701666 L_ROA_FR_FD_AlvCnt1Val "For the first transmission request for a data element the counter shall be initialized with 0 and shall be incremented by 1 for every subsequent send request. 

When the counter reaches the maximum value(0xFF), then it shall restart with 0 for the next s";
BA_ "Version" SG_ 2281701666 ROA_FR_SW_Ver_Major "23.01.03";
BA_ "UserSigValidity" SG_ 2281701666 ROA_FR_SW_Ver_Major 0;
BA_ "GenSigSendType" SG_ 2281701666 ROA_FR_SW_Ver_Major 4;
BA_ "Version" SG_ 2281701666 ROA_FR_SW_Ver_Minor1 "23.01.03";
BA_ "UserSigValidity" SG_ 2281701666 ROA_FR_SW_Ver_Minor1 0;
BA_ "GenSigSendType" SG_ 2281701666 ROA_FR_SW_Ver_Minor1 4;
BA_ "Version" SG_ 2281701666 ROA_FR_SW_Ver_Minor2 "23.01.03";
BA_ "UserSigValidity" SG_ 2281701666 ROA_FR_SW_Ver_Minor2 0;
BA_ "GenSigSendType" SG_ 2281701666 ROA_FR_SW_Ver_Minor2 4;
BA_ "Version" SG_ 2281701666 ROA_FR_ClassStat "23.01.03";
BA_ "UserSigValidity" SG_ 2281701666 ROA_FR_ClassStat 0;
BA_ "GenSigSendType" SG_ 2281701666 ROA_FR_ClassStat 4;
BA_ "Version" SG_ 2281701666 ROA_FR_SnSrStat "23.01.03";
BA_ "UserSigValidity" SG_ 2281701666 ROA_FR_SnSrStat 0;
BA_ "GenSigSendType" SG_ 2281701666 ROA_FR_SnSrStat 4;
BA_ "Version" SG_ 2281701666 ROA_FR_DetInfo "23.01.03";
BA_ "UserSigValidity" SG_ 2281701666 ROA_FR_DetInfo 0;
BA_ "GenSigSendType" SG_ 2281701666 ROA_FR_DetInfo 4;
BA_ "Version" SG_ 2281701666 ROA_FR_SnSrBlckgeErrStat "23.01.03";
BA_ "UserSigValidity" SG_ 2281701666 ROA_FR_SnSrBlckgeErrStat 0;
BA_ "GenSigSendType" SG_ 2281701666 ROA_FR_SnSrBlckgeErrStat 4;
BA_ "Version" SG_ 2281701666 ROA_FR_SnSrErrStat "23.01.03";
BA_ "UserSigValidity" SG_ 2281701666 ROA_FR_SnSrErrStat 0;
BA_ "GenSigSendType" SG_ 2281701666 ROA_FR_SnSrErrStat 4;
BA_ "Version" SG_ 2214592608 L_BDC_FD_ROA_Crc2Val "23.01.02";
BA_ "UserSigValidity" SG_ 2214592608 L_BDC_FD_ROA_Crc2Val 3;
BA_ "GenSigStartValue" SG_ 2214592608 L_BDC_FD_ROA_Crc2Val 65535;
BA_ "GenSigSendType" SG_ 2214592608 L_BDC_FD_ROA_Crc2Val 2;
BA_ "Description" SG_ 2214592608 L_BDC_FD_ROA_Crc2Val "The data area for CRC calculation is based on the data length (DLC) of the message DB.

The CRC shall be calculated over the entire data block (excluding the CRC bytes) including the user data, alive counter and Data ID



- CRC Polynomial (0x1021) , Ini";
BA_ "Version" SG_ 2214592608 L_BDC_FD_ROA_AlvCnt2Val "23.01.02";
BA_ "UserSigValidity" SG_ 2214592608 L_BDC_FD_ROA_AlvCnt2Val 3;
BA_ "GenSigSendType" SG_ 2214592608 L_BDC_FD_ROA_AlvCnt2Val 2;
BA_ "Description" SG_ 2214592608 L_BDC_FD_ROA_AlvCnt2Val "For the first transmission request for a data element the counter shall be initialized with 0 and shall be incremented by 1 for every subsequent send request. 

When the counter reaches the maximum value(0xFF), then it shall restart with 0 for the next s";
BA_ "Version" SG_ 2214592608 BDCROADataByte0 "23.01.02";
BA_ "UserSigValidity" SG_ 2214592608 BDCROADataByte0 0;
BA_ "GenSigSendType" SG_ 2214592608 BDCROADataByte0 2;
BA_ "Version" SG_ 2214592608 BDCROADataByte1 "23.01.02";
BA_ "UserSigValidity" SG_ 2214592608 BDCROADataByte1 0;
BA_ "GenSigSendType" SG_ 2214592608 BDCROADataByte1 2;
BA_ "Version" SG_ 2214592608 BDCROADataByte2 "23.01.02";
BA_ "UserSigValidity" SG_ 2214592608 BDCROADataByte2 0;
BA_ "GenSigSendType" SG_ 2214592608 BDCROADataByte2 2;
BA_ "Version" SG_ 2214592608 BDCROADataByte3 "23.01.02";
BA_ "UserSigValidity" SG_ 2214592608 BDCROADataByte3 0;
BA_ "GenSigSendType" SG_ 2214592608 BDCROADataByte3 2;
BA_ "Version" SG_ 2214592608 BDCROADataByte4 "23.01.02";
BA_ "UserSigValidity" SG_ 2214592608 BDCROADataByte4 0;
BA_ "GenSigSendType" SG_ 2214592608 BDCROADataByte4 2;
BA_ "Version" SG_ 2214592608 BDCROADataByte5 "23.01.02";
BA_ "UserSigValidity" SG_ 2214592608 BDCROADataByte5 0;
BA_ "GenSigSendType" SG_ 2214592608 BDCROADataByte5 2;
BA_ "Version" SG_ 2214592608 BDCROADataByte6 "23.01.02";
BA_ "UserSigValidity" SG_ 2214592608 BDCROADataByte6 0;
BA_ "GenSigSendType" SG_ 2214592608 BDCROADataByte6 2;
BA_ "Version" SG_ 2214592608 BDCROADataByte7 "23.01.02";
BA_ "UserSigValidity" SG_ 2214592608 BDCROADataByte7 0;
BA_ "GenSigSendType" SG_ 2214592608 BDCROADataByte7 2;
BA_ "Version" SG_ 2525341697 L_UWB_FR_FD_Crc4Val "24.07.05";
BA_ "RoutingFactor" SG_ 2525341697 L_UWB_FR_FD_Crc4Val 0;
BA_ "UserSigValidity" SG_ 2525341697 L_UWB_FR_FD_Crc4Val 3;
BA_ "GenSigStartValue" SG_ 2525341697 L_UWB_FR_FD_Crc4Val 65535;
BA_ "GenSigSendType" SG_ 2525341697 L_UWB_FR_FD_Crc4Val 2;
BA_ "Description" SG_ 2525341697 L_UWB_FR_FD_Crc4Val "The data area for CRC calculation is based on the data length (DLC) of the message DB.

The CRC shall be calculated over the entire data block (excluding the CRC bytes) including the user data, alive counter and Data ID



- CRC Polynomial (0x1021) , Ini";
BA_ "Version" SG_ 2525341697 L_UWB_FR_FD_AlvCnt4Val "24.07.05";
BA_ "RoutingFactor" SG_ 2525341697 L_UWB_FR_FD_AlvCnt4Val 0;
BA_ "UserSigValidity" SG_ 2525341697 L_UWB_FR_FD_AlvCnt4Val 3;
BA_ "GenSigSendType" SG_ 2525341697 L_UWB_FR_FD_AlvCnt4Val 2;
BA_ "Description" SG_ 2525341697 L_UWB_FR_FD_AlvCnt4Val "For the first transmission request for a data element the counter shall be initialized with 0 and shall be incremented by 1 for every subsequent send request. 

When the counter reaches the maximum value(0xFF), then it shall restart with 0 for the next s";
BA_ "Version" SG_ 2525341697 FR_SWID_3_IVD_1 "24.07.05";
BA_ "RoutingFactor" SG_ 2525341697 FR_SWID_3_IVD_1 0;
BA_ "UserSigValidity" SG_ 2525341697 FR_SWID_3_IVD_1 0;
BA_ "GenSigSendType" SG_ 2525341697 FR_SWID_3_IVD_1 2;
BA_ "Version" SG_ 2281701680 L_SAL_FD_Crc1Val "23.01.02";
BA_ "UserSigValidity" SG_ 2281701680 L_SAL_FD_Crc1Val 3;
BA_ "GenSigStartValue" SG_ 2281701680 L_SAL_FD_Crc1Val 65535;
BA_ "GenSigSendType" SG_ 2281701680 L_SAL_FD_Crc1Val 4;
BA_ "Description" SG_ 2281701680 L_SAL_FD_Crc1Val "The data area for CRC calculation is based on the data length (DLC) of the message DB.

The CRC shall be calculated over the entire data block (excluding the CRC bytes) including the user data, alive counter and Data ID



- CRC Polynomial (0x1021) , Ini";
BA_ "Version" SG_ 2281701680 SAL_BttmBrightnessDutyRatio "24.07.03";
BA_ "UserSigValidity" SG_ 2281701680 SAL_BttmBrightnessDutyRatio 0;
BA_ "GenSigSendType" SG_ 2281701680 SAL_BttmBrightnessDutyRatio 4;
BA_ "Version" SG_ 2281701680 SAL_BttmFadeInTime "24.07.03";
BA_ "UserSigValidity" SG_ 2281701680 SAL_BttmFadeInTime 0;
BA_ "GenSigSendType" SG_ 2281701680 SAL_BttmFadeInTime 4;
BA_ "Version" SG_ 2281701680 SAL_BttmFadeOutTimeValue "24.07.03";
BA_ "UserSigValidity" SG_ 2281701680 SAL_BttmFadeOutTimeValue 0;
BA_ "GenSigSendType" SG_ 2281701680 SAL_BttmFadeOutTimeValue 4;
BA_ "Version" SG_ 2281701680 SAL_MLNShiftModOptionState "24.07.03";
BA_ "UserSigValidity" SG_ 2281701680 SAL_MLNShiftModOptionState 0;
BA_ "GenSigSendType" SG_ 2281701680 SAL_MLNShiftModOptionState 4;
BA_ "Version" SG_ 2281701680 L_SAL_FD_AlvCnt1Val "23.01.02";
BA_ "UserSigValidity" SG_ 2281701680 L_SAL_FD_AlvCnt1Val 3;
BA_ "GenSigSendType" SG_ 2281701680 L_SAL_FD_AlvCnt1Val 4;
BA_ "Description" SG_ 2281701680 L_SAL_FD_AlvCnt1Val "For the first transmission request for a data element the counter shall be initialized with 0 and shall be incremented by 1 for every subsequent send request. 

When the counter reaches the maximum value(0xFF), then it shall restart with 0 for the next s";
BA_ "Version" SG_ 2281701680 SAL_MLSALApplyState "23.01.02";
BA_ "NetworkRequestHoldingTime" SG_ 2281701680 SAL_MLSALApplyState 5000;
BA_ "NetworkRequest" SG_ 2281701680 SAL_MLSALApplyState 0;
BA_ "UserSigValidity" SG_ 2281701680 SAL_MLSALApplyState 0;
BA_ "GenSigSendType" SG_ 2281701680 SAL_MLSALApplyState 4;
BA_ "Version" SG_ 2281701680 SAL_MLAIVoiceOptionState "23.01.02";
BA_ "NetworkRequestHoldingTime" SG_ 2281701680 SAL_MLAIVoiceOptionState 5000;
BA_ "NetworkRequest" SG_ 2281701680 SAL_MLAIVoiceOptionState 0;
BA_ "UserSigValidity" SG_ 2281701680 SAL_MLAIVoiceOptionState 0;
BA_ "GenSigSendType" SG_ 2281701680 SAL_MLAIVoiceOptionState 4;
BA_ "Version" SG_ 2281701680 SAL_MLTherapyOptionState "23.01.02";
BA_ "NetworkRequestHoldingTime" SG_ 2281701680 SAL_MLTherapyOptionState 5000;
BA_ "NetworkRequest" SG_ 2281701680 SAL_MLTherapyOptionState 0;
BA_ "UserSigValidity" SG_ 2281701680 SAL_MLTherapyOptionState 0;
BA_ "GenSigSendType" SG_ 2281701680 SAL_MLTherapyOptionState 4;
BA_ "Version" SG_ 2281701680 SAL_MLDualColorOptionState "23.01.02";
BA_ "NetworkRequestHoldingTime" SG_ 2281701680 SAL_MLDualColorOptionState 5000;
BA_ "NetworkRequest" SG_ 2281701680 SAL_MLDualColorOptionState 0;
BA_ "UserSigValidity" SG_ 2281701680 SAL_MLDualColorOptionState 0;
BA_ "GenSigSendType" SG_ 2281701680 SAL_MLDualColorOptionState 4;
BA_ "Version" SG_ 2281701680 SAL_MLNumRecommendColor "23.01.02";
BA_ "NetworkRequestHoldingTime" SG_ 2281701680 SAL_MLNumRecommendColor 5000;
BA_ "NetworkRequest" SG_ 2281701680 SAL_MLNumRecommendColor 0;
BA_ "UserSigValidity" SG_ 2281701680 SAL_MLNumRecommendColor 0;
BA_ "GenSigSendType" SG_ 2281701680 SAL_MLNumRecommendColor 4;
BA_ "Version" SG_ 2281701680 SAL_UPRColorXValue "23.08.00";
BA_ "UserSigValidity" SG_ 2281701680 SAL_UPRColorXValue 0;
BA_ "GenSigSendType" SG_ 2281701680 SAL_UPRColorXValue 4;
BA_ "Version" SG_ 2281701680 SAL_UPRColorYValue "23.08.00";
BA_ "UserSigValidity" SG_ 2281701680 SAL_UPRColorYValue 0;
BA_ "GenSigSendType" SG_ 2281701680 SAL_UPRColorYValue 4;
BA_ "Version" SG_ 2281701680 SAL_BrightnessDutyRatio "23.08.00";
BA_ "UserSigValidity" SG_ 2281701680 SAL_BrightnessDutyRatio 0;
BA_ "GenSigSendType" SG_ 2281701680 SAL_BrightnessDutyRatio 4;
BA_ "Version" SG_ 2281701680 SAL_FadeInTime "23.08.00";
BA_ "UserSigValidity" SG_ 2281701680 SAL_FadeInTime 0;
BA_ "GenSigSendType" SG_ 2281701680 SAL_FadeInTime 4;
BA_ "Version" SG_ 2281701680 SAL_FadeOutTimeValue "23.08.00";
BA_ "UserSigValidity" SG_ 2281701680 SAL_FadeOutTimeValue 0;
BA_ "GenSigSendType" SG_ 2281701680 SAL_FadeOutTimeValue 4;
BA_ "Version" SG_ 2281701680 SAL_MLEarlyEveningOptionState "24.02.00";
BA_ "UserSigValidity" SG_ 2281701680 SAL_MLEarlyEveningOptionState 0;
BA_ "GenSigSendType" SG_ 2281701680 SAL_MLEarlyEveningOptionState 4;
BA_ "Description" SG_ 2281701680 SAL_MLEarlyEveningOptionState "In order to improve the problem of mood lamp reflection when driving at night, 

it is necessary to apply the light dimming function optimization specification (dimming separately for early evening/night).

Regarding the addition of the OVk vehicle early";
BA_ "Version" SG_ 2281701680 SAL_MLTempChgOptionState "24.05.01";
BA_ "UserSigValidity" SG_ 2281701680 SAL_MLTempChgOptionState 0;
BA_ "GenSigSendType" SG_ 2281701680 SAL_MLTempChgOptionState 4;
BA_ "Description" SG_ 2281701680 SAL_MLTempChgOptionState "Temperature control ambient light option signal";
BA_ "Version" SG_ 2281701680 SAL_MLPhoneCallModOptionState "24.05.01";
BA_ "UserSigValidity" SG_ 2281701680 SAL_MLPhoneCallModOptionState 0;
BA_ "GenSigSendType" SG_ 2281701680 SAL_MLPhoneCallModOptionState 4;
BA_ "Description" SG_ 2281701680 SAL_MLPhoneCallModOptionState "Ambient light option signal linked to phone reception";
BA_ "Version" SG_ 2281701680 SAL_MLDoorWarnOptionState "24.05.01";
BA_ "UserSigValidity" SG_ 2281701680 SAL_MLDoorWarnOptionState 0;
BA_ "GenSigSendType" SG_ 2281701680 SAL_MLDoorWarnOptionState 4;
BA_ "Description" SG_ 2281701680 SAL_MLDoorWarnOptionState "Ambient option linked ADAS warning signal";
BA_ "Version" SG_ 2281701680 SAL_MLHazardModOptionState "24.05.01";
BA_ "UserSigValidity" SG_ 2281701680 SAL_MLHazardModOptionState 0;
BA_ "GenSigSendType" SG_ 2281701680 SAL_MLHazardModOptionState 4;
BA_ "Description" SG_ 2281701680 SAL_MLHazardModOptionState "Ambient light linked hazard warning signal";
BA_ "Version" SG_ 2281701680 SAL_MLLowFuelModOptionState "24.05.01";
BA_ "UserSigValidity" SG_ 2281701680 SAL_MLLowFuelModOptionState 0;
BA_ "GenSigSendType" SG_ 2281701680 SAL_MLLowFuelModOptionState 4;
BA_ "Description" SG_ 2281701680 SAL_MLLowFuelModOptionState "Ambiet Light linked low fuel warning signal";
BA_ "Version" SG_ 2281701680 SAL_BttmColorXValue "24.07.03";
BA_ "UserSigValidity" SG_ 2281701680 SAL_BttmColorXValue 0;
BA_ "GenSigSendType" SG_ 2281701680 SAL_BttmColorXValue 4;
BA_ "Version" SG_ 2281701680 SAL_BttmColorYValue "24.07.03";
BA_ "UserSigValidity" SG_ 2281701680 SAL_BttmColorYValue 0;
BA_ "GenSigSendType" SG_ 2281701680 SAL_BttmColorYValue 4;
BA_ "Version" SG_ 1025 BDC_FD_SMK_Crc2Val "22.11.04";
BA_ "UserSigValidity" SG_ 1025 BDC_FD_SMK_Crc2Val 0;
BA_ "GenSigStartValue" SG_ 1025 BDC_FD_SMK_Crc2Val 65535;
BA_ "GenSigSendType" SG_ 1025 BDC_FD_SMK_Crc2Val 4;
BA_ "Description" SG_ 1025 BDC_FD_SMK_Crc2Val "The data area for CRC calculation is based on the data length (DLC) of the message DB.

The CRC shall be calculated over the entire data block (excluding the CRC bytes) including the user data, alive counter and Data ID



- CRC Polynomial (0x1021) , Ini";
BA_ "Version" SG_ 1025 SMK_RpmLoByteVal_Copy_0 "21.07.05";
BA_ "UserSigValidity" SG_ 1025 SMK_RpmLoByteVal_Copy_0 0;
BA_ "GenSigSendType" SG_ 1025 SMK_RpmLoByteVal_Copy_0 4;
BA_ "Version" SG_ 1025 SMK_VehSpdDrctVal_Copy_0 "21.07.05";
BA_ "UserSigValidity" SG_ 1025 SMK_VehSpdDrctVal_Copy_0 0;
BA_ "GenSigSendType" SG_ 1025 SMK_VehSpdDrctVal_Copy_0 4;
BA_ "Version" SG_ 1025 Fob_BattStaInfo_Copy_0 "17.12.00";
BA_ "UserSigValidity" SG_ 1025 Fob_BattStaInfo_Copy_0 0;
BA_ "GenSigSendType" SG_ 1025 Fob_BattStaInfo_Copy_0 4;
BA_ "Description" SG_ 1025 Fob_BattStaInfo_Copy_0 "Received Fob Battery Status for Telematics Vehicle Information Service";
BA_ "Version" SG_ 1025 Fob_FoundDrvWlcmArea_Copy_0 "17.12.00";
BA_ "UserSigValidity" SG_ 1025 Fob_FoundDrvWlcmArea_Copy_0 0;
BA_ "GenSigSendType" SG_ 1025 Fob_FoundDrvWlcmArea_Copy_0 4;
BA_ "Description" SG_ 1025 Fob_FoundDrvWlcmArea_Copy_0 "This Signal Indicates direction of user approach to vehicle.

If User Approach to vehicle Driver direction, This signal set On.";
BA_ "Version" SG_ 1025 Fob_FoundAsstWlcmArea_Copy_0 "17.12.00";
BA_ "UserSigValidity" SG_ 1025 Fob_FoundAsstWlcmArea_Copy_0 0;
BA_ "GenSigSendType" SG_ 1025 Fob_FoundAsstWlcmArea_Copy_0 4;
BA_ "Description" SG_ 1025 Fob_FoundAsstWlcmArea_Copy_0 "This Signal Indicates direction of user approach to vehicle.

If User Approach to vehicle Assistant direction, This signal set On.";
BA_ "Version" SG_ 1025 Fob_FoundExtrnlArea_Copy_0 "17.12.00";
BA_ "UserSigValidity" SG_ 1025 Fob_FoundExtrnlArea_Copy_0 0;
BA_ "GenSigSendType" SG_ 1025 Fob_FoundExtrnlArea_Copy_0 4;
BA_ "Description" SG_ 1025 Fob_FoundExtrnlArea_Copy_0 "Exterior FOB Position recognize";
BA_ "Version" SG_ 1025 Fob_FoundIntArea_Copy_0 "17.12.00";
BA_ "UserSigValidity" SG_ 1025 Fob_FoundIntArea_Copy_0 0;
BA_ "GenSigSendType" SG_ 1025 Fob_FoundIntArea_Copy_0 4;
BA_ "Description" SG_ 1025 Fob_FoundIntArea_Copy_0 "Interior FOB Position recognize";
BA_ "Version" SG_ 1025 Fob_LearntSta_Copy_0 "17.12.00";
BA_ "NetworkRequestHoldingTime" SG_ 1025 Fob_LearntSta_Copy_0 5000;
BA_ "NetworkRequest" SG_ 1025 Fob_LearntSta_Copy_0 0;
BA_ "UserSigValidity" SG_ 1025 Fob_LearntSta_Copy_0 0;
BA_ "GenSigStartValue" SG_ 1025 Fob_LearntSta_Copy_0 1;
BA_ "GenSigSendType" SG_ 1025 Fob_LearntSta_Copy_0 4;
BA_ "Description" SG_ 1025 Fob_LearntSta_Copy_0 "Fob key registration status information";
BA_ "Version" SG_ 1025 RSPA_LearntSta_Copy_0 "19.07.01";
BA_ "UserSigValidity" SG_ 1025 RSPA_LearntSta_Copy_0 0;
BA_ "GenSigSendType" SG_ 1025 RSPA_LearntSta_Copy_0 4;
BA_ "Description" SG_ 1025 RSPA_LearntSta_Copy_0 "IBU RSPA learnt state signal.

This signal is used only for ADAS_PRK.";
BA_ "Version" SG_ 1025 RSPA_RFSigErrSta_Copy_0 "18.05.02";
BA_ "NetworkRequestHoldingTime" SG_ 1025 RSPA_RFSigErrSta_Copy_0 5000;
BA_ "NetworkRequest" SG_ 1025 RSPA_RFSigErrSta_Copy_0 0;
BA_ "UserSigValidity" SG_ 1025 RSPA_RFSigErrSta_Copy_0 0;
BA_ "GenSigSendType" SG_ 1025 RSPA_RFSigErrSta_Copy_0 4;
BA_ "Description" SG_ 1025 RSPA_RFSigErrSta_Copy_0 "Error status of RKE_BtnReq signal.



If RF frame data from FOB defferent with CAN signal data(RKE_BtnReq), 

RSPA_RFSigErrSta signal send 0x1 Signal Invalid.";
BA_ "Version" SG_ 1025 RSPA_CanErrSta_Copy_0 "18.05.02";
BA_ "UserSigValidity" SG_ 1025 RSPA_CanErrSta_Copy_0 0;
BA_ "GenSigSendType" SG_ 1025 RSPA_CanErrSta_Copy_0 4;
BA_ "Description" SG_ 1025 RSPA_CanErrSta_Copy_0 "Error status of RSPA control signals.(From ADAS_PRK)";
BA_ "Version" SG_ 1025 RSPA_ModSta_SMK_Copy_0 "19.03.08";
BA_ "UserSigValidity" SG_ 1025 RSPA_ModSta_SMK_Copy_0 0;
BA_ "GenSigSendType" SG_ 1025 RSPA_ModSta_SMK_Copy_0 4;
BA_ "Description" SG_ 1025 RSPA_ModSta_SMK_Copy_0 "State of RSPA system operate";
BA_ "Version" SG_ 1025 RSPA_FobBattSta_Copy_0 "17.12.00";
BA_ "UserSigValidity" SG_ 1025 RSPA_FobBattSta_Copy_0 0;
BA_ "GenSigSendType" SG_ 1025 RSPA_FobBattSta_Copy_0 4;
BA_ "Description" SG_ 1025 RSPA_FobBattSta_Copy_0 "FOB Battery's Low Battery(discharge) state.

Low Battery condition is same with 'C_KeyBATDischargeWarn' Signal";
BA_ "Version" SG_ 1025 Fob_BtnReleasedSta_Copy_0 "18.10.09";
BA_ "UserSigValidity" SG_ 1025 Fob_BtnReleasedSta_Copy_0 0;
BA_ "GenSigSendType" SG_ 1025 Fob_BtnReleasedSta_Copy_0 4;
BA_ "Description" SG_ 1025 Fob_BtnReleasedSta_Copy_0 "this signal indicate fob butten released state during RSPA mode. 

##2G##IBU##SMK18##C_FobButtenReleased";
BA_ "Version" SG_ 1025 Fob_FoundWlcmArea_Copy_0 "19.03.09";
BA_ "UserSigValidity" SG_ 1025 Fob_FoundWlcmArea_Copy_0 0;
BA_ "GenSigSendType" SG_ 1025 Fob_FoundWlcmArea_Copy_0 4;
BA_ "Description" SG_ 1025 Fob_FoundWlcmArea_Copy_0 "This signal indicates that there is Fob around the welcome area. 

 -to inform the door handle (Lock/Unlock touch sensor)";
BA_ "Version" SG_ 1025 USM_WALModSta_Copy_0 "17.12.00";
BA_ "UserSigValidity" SG_ 1025 USM_WALModSta_Copy_0 0;
BA_ "GenSigSendType" SG_ 1025 USM_WALModSta_Copy_0 4;
BA_ "Description" SG_ 1025 USM_WALModSta_Copy_0 "Current USM Setting value of Walk Away Lock(WAL) mode";
BA_ "Version" SG_ 1025 USM_SmrtTrnkTlgtModSta_Copy_0 "18.05.01";
BA_ "UserSigValidity" SG_ 1025 USM_SmrtTrnkTlgtModSta_Copy_0 0;
BA_ "GenSigSendType" SG_ 1025 USM_SmrtTrnkTlgtModSta_Copy_0 4;
BA_ "Version" SG_ 1025 USM_SAUModSta "22.11.07";
BA_ "NetworkRequestHoldingTime" SG_ 1025 USM_SAUModSta 5000;
BA_ "NetworkRequest" SG_ 1025 USM_SAUModSta 0;
BA_ "UserSigValidity" SG_ 1025 USM_SAUModSta 0;
BA_ "GenSigSendType" SG_ 1025 USM_SAUModSta 4;
BA_ "Version" SG_ 1025 SMK_RLHndLkSnsrSta_Copy_0 "23.07.00";
BA_ "UserSigValidity" SG_ 1025 SMK_RLHndLkSnsrSta_Copy_0 0;
BA_ "GenSigSendType" SG_ 1025 SMK_RLHndLkSnsrSta_Copy_0 4;
BA_ "Description" SG_ 1025 SMK_RLHndLkSnsrSta_Copy_0 "Development for SMK

Rear Left Door Handle Lock Touch Sensor Signal";
BA_ "Version" SG_ 1025 BDC_FD_SMK_AlvCnt2Val "22.11.04";
BA_ "UserSigValidity" SG_ 1025 BDC_FD_SMK_AlvCnt2Val 0;
BA_ "GenSigSendType" SG_ 1025 BDC_FD_SMK_AlvCnt2Val 4;
BA_ "Description" SG_ 1025 BDC_FD_SMK_AlvCnt2Val "For the first transmission request for a data element the counter shall be initialized with 0 and shall be incremented by 1 for every subsequent send request. 

When the counter reaches the maximum value(0xFF), then it shall restart with 0 for the next s";
BA_ "Version" SG_ 1025 SMK_RLDrHndUnLkSnsrSta_Copy_0 "23.07.00";
BA_ "UserSigValidity" SG_ 1025 SMK_RLDrHndUnLkSnsrSta_Copy_0 0;
BA_ "GenSigSendType" SG_ 1025 SMK_RLDrHndUnLkSnsrSta_Copy_0 4;
BA_ "Description" SG_ 1025 SMK_RLDrHndUnLkSnsrSta_Copy_0 "Development for SMK

Rear Left  Door Handle Unlock Touch Sensor Signal";
BA_ "Version" SG_ 1025 SMK_RRDrHndLkSnsrSta_Copy_0 "23.07.00";
BA_ "UserSigValidity" SG_ 1025 SMK_RRDrHndLkSnsrSta_Copy_0 0;
BA_ "GenSigSendType" SG_ 1025 SMK_RRDrHndLkSnsrSta_Copy_0 4;
BA_ "Description" SG_ 1025 SMK_RRDrHndLkSnsrSta_Copy_0 "Development for SMK

Rear Right Door Handle Lock Touch Sensor Signal";
BA_ "Version" SG_ 1025 SMK_RRDrHndUnLkSnsrSta_Copy_0 "23.07.00";
BA_ "UserSigValidity" SG_ 1025 SMK_RRDrHndUnLkSnsrSta_Copy_0 0;
BA_ "GenSigSendType" SG_ 1025 SMK_RRDrHndUnLkSnsrSta_Copy_0 4;
BA_ "Description" SG_ 1025 SMK_RRDrHndUnLkSnsrSta_Copy_0 "Development for SMK

Rear Right Door Handle Unlock Touch Sensor Signal";
BA_ "Version" SG_ 1025 Fob_FoundCabinArea_Copy_0 "23.09.04";
BA_ "UserSigValidity" SG_ 1025 Fob_FoundCabinArea_Copy_0 0;
BA_ "GenSigSendType" SG_ 1025 Fob_FoundCabinArea_Copy_0 4;
BA_ "Description" SG_ 1025 Fob_FoundCabinArea_Copy_0 "Fob searching result in cabin area for SWA function

*SWA : Smart Walk Away Lock";
BA_ "Version" SG_ 1025 SMK_ResultRmtStrt "24.07.06";
BA_ "UserSigValidity" SG_ 1025 SMK_ResultRmtStrt 0;
BA_ "GenSigSendType" SG_ 1025 SMK_ResultRmtStrt 4;
BA_ "Description" SG_ 1025 SMK_ResultRmtStrt "1) Control Raw Data OK + Valid code OK

     бц Run Tele Engine Running, and If it success, then send 0x1

2) Control Raw Data OK + Valid code NG

     бц Don't run Tele Engine Running, and it Fail, then send 0x2

3) Control Raw Data NG + Valid code OK

";
BA_ "Version" SG_ 1025 SMK_EncryptTeleOptSta "24.04.01";
BA_ "UserSigValidity" SG_ 1025 SMK_EncryptTeleOptSta 0;
BA_ "GenSigSendType" SG_ 1025 SMK_EncryptTeleOptSta 4;
BA_ "Description" SG_ 1025 SMK_EncryptTeleOptSta "If applied Remote Start Encryption, then send 0x1";
BA_ "Version" SG_ 1025 Auth_ISKLearnSta2_Copy_0 "24.04.03";
BA_ "UserSigValidity" SG_ 1025 Auth_ISKLearnSta2_Copy_0 0;
BA_ "GenSigSendType" SG_ 1025 Auth_ISKLearnSta2_Copy_0 4;
BA_ "Version" SG_ 1025 Auth_ISKLearnSta_Copy_0 "19.02.07";
BA_ "UserSigValidity" SG_ 1025 Auth_ISKLearnSta_Copy_0 0;
BA_ "GenSigSendType" SG_ 1025 Auth_ISKLearnSta_Copy_0 4;
BA_ "Description" SG_ 1025 Auth_ISKLearnSta_Copy_0 "This signal is State of IAU Learning";
BA_ "Version" SG_ 1025 SMK_TlPwrOnSta_Copy_0 "24.04.03";
BA_ "UserSigValidity" SG_ 1025 SMK_TlPwrOnSta_Copy_0 0;
BA_ "GenSigSendType" SG_ 1025 SMK_TlPwrOnSta_Copy_0 4;
BA_ "Version" SG_ 1025 Fob_FoundForChargingDoor_Copy_0 "24.04.10";
BA_ "UserSigValidity" SG_ 1025 Fob_FoundForChargingDoor_Copy_0 0;
BA_ "GenSigSendType" SG_ 1025 Fob_FoundForChargingDoor_Copy_0 4;
BA_ "Description" SG_ 1025 Fob_FoundForChargingDoor_Copy_0 "Fob searching result for charging door open";
BA_ "Version" SG_ 1025 SSB_StrtStpBtnSw1Sta_Copy_0 "17.12.00";
BA_ "UserSigValidity" SG_ 1025 SSB_StrtStpBtnSw1Sta_Copy_0 0;
BA_ "GenSigSendType" SG_ 1025 SSB_StrtStpBtnSw1Sta_Copy_0 4;
BA_ "Description" SG_ 1025 SSB_StrtStpBtnSw1Sta_Copy_0 "StartStop button switch #1 status";
BA_ "Version" SG_ 1025 SSB_StrtStpBtnSw2Sta_Copy_0 "17.12.00";
BA_ "UserSigValidity" SG_ 1025 SSB_StrtStpBtnSw2Sta_Copy_0 0;
BA_ "GenSigSendType" SG_ 1025 SSB_StrtStpBtnSw2Sta_Copy_0 4;
BA_ "Description" SG_ 1025 SSB_StrtStpBtnSw2Sta_Copy_0 "StartStop button switch #2 status";
BA_ "Version" SG_ 1025 SMK_AuthSta_Copy_0 "17.12.00";
BA_ "UserSigValidity" SG_ 1025 SMK_AuthSta_Copy_0 0;
BA_ "GenSigSendType" SG_ 1025 SMK_AuthSta_Copy_0 4;
BA_ "Version" SG_ 1025 SMK_TlPwrOnOpt_Copy_0 "24.04.09";
BA_ "UserSigValidity" SG_ 1025 SMK_TlPwrOnOpt_Copy_0 0;
BA_ "GenSigSendType" SG_ 1025 SMK_TlPwrOnOpt_Copy_0 4;
BA_ "Version" SG_ 1025 SMK_Ign1InSta_Copy_0 "17.12.00";
BA_ "UserSigValidity" SG_ 1025 SMK_Ign1InSta_Copy_0 0;
BA_ "GenSigSendType" SG_ 1025 SMK_Ign1InSta_Copy_0 4;
BA_ "Description" SG_ 1025 SMK_Ign1InSta_Copy_0 "Ignition1 Input Status at SMK";
BA_ "Version" SG_ 1025 SMK_Ign1RlySta_Copy_0 "17.12.00";
BA_ "UserSigValidity" SG_ 1025 SMK_Ign1RlySta_Copy_0 0;
BA_ "GenSigSendType" SG_ 1025 SMK_Ign1RlySta_Copy_0 4;
BA_ "Description" SG_ 1025 SMK_Ign1RlySta_Copy_0 "Development for SMK";
BA_ "Version" SG_ 1025 SMK_Ign2InSta_Copy_0 "17.12.00";
BA_ "UserSigValidity" SG_ 1025 SMK_Ign2InSta_Copy_0 0;
BA_ "GenSigSendType" SG_ 1025 SMK_Ign2InSta_Copy_0 4;
BA_ "Description" SG_ 1025 SMK_Ign2InSta_Copy_0 "Ignition2 Input Status at SMK";
BA_ "Version" SG_ 1025 SMK_Ign2RlySta_Copy_0 "17.12.00";
BA_ "UserSigValidity" SG_ 1025 SMK_Ign2RlySta_Copy_0 0;
BA_ "GenSigSendType" SG_ 1025 SMK_Ign2RlySta_Copy_0 4;
BA_ "Description" SG_ 1025 SMK_Ign2RlySta_Copy_0 "Development for SMK";
BA_ "Version" SG_ 1025 SMK_StrtFdbckSta_Copy_0 "17.12.00";
BA_ "UserSigValidity" SG_ 1025 SMK_StrtFdbckSta_Copy_0 0;
BA_ "GenSigSendType" SG_ 1025 SMK_StrtFdbckSta_Copy_0 4;
BA_ "Description" SG_ 1025 SMK_StrtFdbckSta_Copy_0 "Mirror value of L_StartFeedback";
BA_ "Version" SG_ 1025 SMK_StrtrRlyOutSta_Copy_0 "17.12.00";
BA_ "UserSigValidity" SG_ 1025 SMK_StrtrRlyOutSta_Copy_0 0;
BA_ "GenSigSendType" SG_ 1025 SMK_StrtrRlyOutSta_Copy_0 4;
BA_ "Description" SG_ 1025 SMK_StrtrRlyOutSta_Copy_0 "-(Old)C_StarterRelayStatus";
BA_ "Version" SG_ 1025 SMK_AccInSta_Copy_0 "17.12.00";
BA_ "UserSigValidity" SG_ 1025 SMK_AccInSta_Copy_0 0;
BA_ "GenSigSendType" SG_ 1025 SMK_AccInSta_Copy_0 4;
BA_ "Description" SG_ 1025 SMK_AccInSta_Copy_0 "ACC Input Status at SMK";
BA_ "Version" SG_ 1025 SMK_AccRlySta_Copy_0 "17.12.00";
BA_ "UserSigValidity" SG_ 1025 SMK_AccRlySta_Copy_0 0;
BA_ "GenSigSendType" SG_ 1025 SMK_AccRlySta_Copy_0 4;
BA_ "Description" SG_ 1025 SMK_AccRlySta_Copy_0 "Development for SMK";
BA_ "Version" SG_ 1025 SMK_CLUAccIndOnReq_Copy_0 "17.12.00";
BA_ "UserSigValidity" SG_ 1025 SMK_CLUAccIndOnReq_Copy_0 0;
BA_ "GenSigSendType" SG_ 1025 SMK_CLUAccIndOnReq_Copy_0 4;
BA_ "Description" SG_ 1025 SMK_CLUAccIndOnReq_Copy_0 "Request to Cluster ACC Indicator On

(This is only used for CLU)";
BA_ "Version" SG_ 1025 SMK_VDModeActSta_Copy_0 "20.07.05";
BA_ "UserSigValidity" SG_ 1025 SMK_VDModeActSta_Copy_0 0;
BA_ "GenSigSendType" SG_ 1025 SMK_VDModeActSta_Copy_0 4;
BA_ "Version" SG_ 1025 SMK_SCULckUnlckSta_Copy_0 "22.01.06";
BA_ "UserSigValidity" SG_ 1025 SMK_SCULckUnlckSta_Copy_0 0;
BA_ "GenSigSendType" SG_ 1025 SMK_SCULckUnlckSta_Copy_0 4;
BA_ "Description" SG_ 1025 SMK_SCULckUnlckSta_Copy_0 "SCU Lock/Unlock State";
BA_ "Version" SG_ 1025 SMK_TlEngRunSta_Copy_0 "17.12.00";
BA_ "UserSigValidity" SG_ 1025 SMK_TlEngRunSta_Copy_0 0;
BA_ "GenSigSendType" SG_ 1025 SMK_TlEngRunSta_Copy_0 4;
BA_ "Version" SG_ 1025 SMK_TlCrnkModSta_Copy_0 "17.12.00";
BA_ "UserSigValidity" SG_ 1025 SMK_TlCrnkModSta_Copy_0 0;
BA_ "GenSigSendType" SG_ 1025 SMK_TlCrnkModSta_Copy_0 4;
BA_ "Version" SG_ 1025 SMK_RmtKeyEngRunSta_Copy_0 "17.11.00";
BA_ "UserSigValidity" SG_ 1025 SMK_RmtKeyEngRunSta_Copy_0 0;
BA_ "GenSigSendType" SG_ 1025 SMK_RmtKeyEngRunSta_Copy_0 4;
BA_ "Version" SG_ 1025 SMK_RmtKeyCrnkModSta_Copy_0 "17.11.00";
BA_ "UserSigValidity" SG_ 1025 SMK_RmtKeyCrnkModSta_Copy_0 0;
BA_ "GenSigSendType" SG_ 1025 SMK_RmtKeyCrnkModSta_Copy_0 4;
BA_ "Version" SG_ 1025 SMK_AsstTgglBtnSta_Copy_0 "17.12.00";
BA_ "UserSigValidity" SG_ 1025 SMK_AsstTgglBtnSta_Copy_0 0;
BA_ "GenSigSendType" SG_ 1025 SMK_AsstTgglBtnSta_Copy_0 4;
BA_ "Description" SG_ 1025 SMK_AsstTgglBtnSta_Copy_0 "Development for SMK";
BA_ "Version" SG_ 1025 SMK_DrvTglBtnSta_Copy_0 "17.12.00";
BA_ "UserSigValidity" SG_ 1025 SMK_DrvTglBtnSta_Copy_0 0;
BA_ "GenSigSendType" SG_ 1025 SMK_DrvTglBtnSta_Copy_0 4;
BA_ "Description" SG_ 1025 SMK_DrvTglBtnSta_Copy_0 "Development for SMK";
BA_ "Version" SG_ 1025 SMK_RrLftTglBtnSta_Copy_0 "17.12.00";
BA_ "UserSigValidity" SG_ 1025 SMK_RrLftTglBtnSta_Copy_0 0;
BA_ "GenSigSendType" SG_ 1025 SMK_RrLftTglBtnSta_Copy_0 4;
BA_ "Description" SG_ 1025 SMK_RrLftTglBtnSta_Copy_0 "Development for SMK";
BA_ "Version" SG_ 1025 SMK_RrRtTglBtnSta_Copy_0 "17.12.00";
BA_ "UserSigValidity" SG_ 1025 SMK_RrRtTglBtnSta_Copy_0 0;
BA_ "GenSigSendType" SG_ 1025 SMK_RrRtTglBtnSta_Copy_0 4;
BA_ "Description" SG_ 1025 SMK_RrRtTglBtnSta_Copy_0 "Development for SMK";
BA_ "Version" SG_ 1025 SMK_TgglBtnStuckSta_Copy_0 "17.12.00";
BA_ "UserSigValidity" SG_ 1025 SMK_TgglBtnStuckSta_Copy_0 0;
BA_ "GenSigSendType" SG_ 1025 SMK_TgglBtnStuckSta_Copy_0 4;
BA_ "Description" SG_ 1025 SMK_TgglBtnStuckSta_Copy_0 "This signal represents Toggle Button's Error condition.

If Toggle Button has Fault(ex, Stuck etc..). signal has fault value.";
BA_ "Version" SG_ 1025 SMK_AsstDrHndUnLkSnsrSta_Copy_0 "18.08.08";
BA_ "UserSigValidity" SG_ 1025 SMK_AsstDrHndUnLkSnsrSta_Copy_0 0;
BA_ "GenSigSendType" SG_ 1025 SMK_AsstDrHndUnLkSnsrSta_Copy_0 4;
BA_ "Description" SG_ 1025 SMK_AsstDrHndUnLkSnsrSta_Copy_0 "Development for SMK";
BA_ "Version" SG_ 1025 SMK_BrkSwSta_Copy_0 "17.12.00";
BA_ "UserSigValidity" SG_ 1025 SMK_BrkSwSta_Copy_0 0;
BA_ "GenSigSendType" SG_ 1025 SMK_BrkSwSta_Copy_0 4;
BA_ "Description" SG_ 1025 SMK_BrkSwSta_Copy_0 "SMK+ Brake SW input state";
BA_ "Version" SG_ 1025 SMK_GearPosPSwSta_Copy_0 "21.09.05";
BA_ "UserSigValidity" SG_ 1025 SMK_GearPosPSwSta_Copy_0 0;
BA_ "GenSigSendType" SG_ 1025 SMK_GearPosPSwSta_Copy_0 4;
BA_ "Description" SG_ 1025 SMK_GearPosPSwSta_Copy_0 "Clutch SW (M/T Only)

Shift lever P Postion";
BA_ "Version" SG_ 1025 SMK_CltchIgnLkSwSta_Copy_0 "20.12.04";
BA_ "UserSigValidity" SG_ 1025 SMK_CltchIgnLkSwSta_Copy_0 0;
BA_ "GenSigSendType" SG_ 1025 SMK_CltchIgnLkSwSta_Copy_0 4;
BA_ "Description" SG_ 1025 SMK_CltchIgnLkSwSta_Copy_0 "This signal indicates that SMK has detected an operation of a Ignition Lock switch. EMS uses this signal for improving drivability of manual trasmission vehicle.







If the SMK does not support this signal the value is 00H



0x0 : SMK determines that";
BA_ "Version" SG_ 1025 SMK_DrvDrHndLkSnsrSta_Copy_0 "18.08.07";
BA_ "UserSigValidity" SG_ 1025 SMK_DrvDrHndLkSnsrSta_Copy_0 0;
BA_ "GenSigSendType" SG_ 1025 SMK_DrvDrHndLkSnsrSta_Copy_0 4;
BA_ "Description" SG_ 1025 SMK_DrvDrHndLkSnsrSta_Copy_0 "Development for SMK";
BA_ "Version" SG_ 1025 SMK_DrvDrHndUnLkSnsrSta_Copy_0 "18.08.07";
BA_ "UserSigValidity" SG_ 1025 SMK_DrvDrHndUnLkSnsrSta_Copy_0 0;
BA_ "GenSigSendType" SG_ 1025 SMK_DrvDrHndUnLkSnsrSta_Copy_0 4;
BA_ "Description" SG_ 1025 SMK_DrvDrHndUnLkSnsrSta_Copy_0 "Development for SMK";
BA_ "Version" SG_ 1025 SMK_AsstDrHndLkSnsrSta_Copy_0 "18.08.07";
BA_ "UserSigValidity" SG_ 1025 SMK_AsstDrHndLkSnsrSta_Copy_0 0;
BA_ "GenSigSendType" SG_ 1025 SMK_AsstDrHndLkSnsrSta_Copy_0 4;
BA_ "Description" SG_ 1025 SMK_AsstDrHndLkSnsrSta_Copy_0 "Development for SMK";
BA_ "Version" SG_ 1025 LFAnt_FltSta_Copy_0 "17.12.00";
BA_ "UserSigValidity" SG_ 1025 LFAnt_FltSta_Copy_0 0;
BA_ "GenSigSendType" SG_ 1025 LFAnt_FltSta_Copy_0 4;
BA_ "Description" SG_ 1025 LFAnt_FltSta_Copy_0 "This signal represents LF ANT's Error condition. 

If one of LF ANT has Fault(ex, timeout), signal has fault value.";
BA_ "Version" SG_ 1025 LFAnt_SrchSta_Copy_0 "17.12.00";
BA_ "UserSigValidity" SG_ 1025 LFAnt_SrchSta_Copy_0 0;
BA_ "GenSigSendType" SG_ 1025 LFAnt_SrchSta_Copy_0 4;
BA_ "Description" SG_ 1025 LFAnt_SrchSta_Copy_0 "SMK LF Searching Status



This signal indicates that SMK operates LF searching for finding FOB.

WPC uses this signal for suspending wirless charging.";
BA_ "Version" SG_ 1025 Lamp_HzrdBlnkngSta_Copy_0 "17.12.00";
BA_ "UserSigValidity" SG_ 1025 Lamp_HzrdBlnkngSta_Copy_0 0;
BA_ "GenSigSendType" SG_ 1025 Lamp_HzrdBlnkngSta_Copy_0 4;
BA_ "Description" SG_ 1025 Lamp_HzrdBlnkngSta_Copy_0 "Hazard Signal for Hands Free Trunk/Tailgate";
BA_ "Version" SG_ 1025 Lamp_SmrtWlcmLtOnReq_Copy_0 "17.12.00";
BA_ "NetworkRequestHoldingTime" SG_ 1025 Lamp_SmrtWlcmLtOnReq_Copy_0 5000;
BA_ "NetworkRequest" SG_ 1025 Lamp_SmrtWlcmLtOnReq_Copy_0 0;
BA_ "UserSigValidity" SG_ 1025 Lamp_SmrtWlcmLtOnReq_Copy_0 0;
BA_ "GenSigSendType" SG_ 1025 Lamp_SmrtWlcmLtOnReq_Copy_0 4;
BA_ "Description" SG_ 1025 Lamp_SmrtWlcmLtOnReq_Copy_0 "Smart Key welcome light on request.";
BA_ "Version" SG_ 1025 SMK_RpmHiByteVal_Copy_0 "21.07.05";
BA_ "UserSigValidity" SG_ 1025 SMK_RpmHiByteVal_Copy_0 0;
BA_ "GenSigSendType" SG_ 1025 SMK_RpmHiByteVal_Copy_0 4;
BA_ "Version" SG_ 2529540353 L_UWB_RR_FD_Crc5Val "24.07.05";
BA_ "RoutingFactor" SG_ 2529540353 L_UWB_RR_FD_Crc5Val 0;
BA_ "UserSigValidity" SG_ 2529540353 L_UWB_RR_FD_Crc5Val 3;
BA_ "GenSigStartValue" SG_ 2529540353 L_UWB_RR_FD_Crc5Val 65535;
BA_ "GenSigSendType" SG_ 2529540353 L_UWB_RR_FD_Crc5Val 2;
BA_ "Description" SG_ 2529540353 L_UWB_RR_FD_Crc5Val "The data area for CRC calculation is based on the data length (DLC) of the message DB.

The CRC shall be calculated over the entire data block (excluding the CRC bytes) including the user data, alive counter and Data ID



- CRC Polynomial (0x1021) , Ini";
BA_ "Version" SG_ 2529540353 L_UWB_RR_FD_AlvCnt5Val "24.07.05";
BA_ "RoutingFactor" SG_ 2529540353 L_UWB_RR_FD_AlvCnt5Val 0;
BA_ "UserSigValidity" SG_ 2529540353 L_UWB_RR_FD_AlvCnt5Val 3;
BA_ "GenSigSendType" SG_ 2529540353 L_UWB_RR_FD_AlvCnt5Val 2;
BA_ "Description" SG_ 2529540353 L_UWB_RR_FD_AlvCnt5Val "For the first transmission request for a data element the counter shall be initialized with 0 and shall be incremented by 1 for every subsequent send request. 

When the counter reaches the maximum value(0xFF), then it shall restart with 0 for the next s";
BA_ "Version" SG_ 2529540353 RR_SWID_3_IVD_2 "24.07.05";
BA_ "RoutingFactor" SG_ 2529540353 RR_SWID_3_IVD_2 0;
BA_ "UserSigValidity" SG_ 2529540353 RR_SWID_3_IVD_2 0;
BA_ "GenSigSendType" SG_ 2529540353 RR_SWID_3_IVD_2 2;
BA_ "Version" SG_ 2521142529 L_UWB_BLE_SLV_FD_Crc9Val "24.07.05";
BA_ "RoutingFactor" SG_ 2521142529 L_UWB_BLE_SLV_FD_Crc9Val 0;
BA_ "UserSigValidity" SG_ 2521142529 L_UWB_BLE_SLV_FD_Crc9Val 3;
BA_ "GenSigStartValue" SG_ 2521142529 L_UWB_BLE_SLV_FD_Crc9Val 65535;
BA_ "GenSigSendType" SG_ 2521142529 L_UWB_BLE_SLV_FD_Crc9Val 2;
BA_ "Description" SG_ 2521142529 L_UWB_BLE_SLV_FD_Crc9Val "The data area for CRC calculation is based on the data length (DLC) of the message DB.

The CRC shall be calculated over the entire data block (excluding the CRC bytes) including the user data, alive counter and Data ID



- CRC Polynomial (0x1021) , Ini";
BA_ "Version" SG_ 2521142529 L_UWB_BLE_SLV_FD_AlvCnt9Val "24.07.05";
BA_ "RoutingFactor" SG_ 2521142529 L_UWB_BLE_SLV_FD_AlvCnt9Val 0;
BA_ "UserSigValidity" SG_ 2521142529 L_UWB_BLE_SLV_FD_AlvCnt9Val 3;
BA_ "GenSigSendType" SG_ 2521142529 L_UWB_BLE_SLV_FD_AlvCnt9Val 2;
BA_ "Description" SG_ 2521142529 L_UWB_BLE_SLV_FD_AlvCnt9Val "For the first transmission request for a data element the counter shall be initialized with 0 and shall be incremented by 1 for every subsequent send request. 

When the counter reaches the maximum value(0xFF), then it shall restart with 0 for the next s";
BA_ "Version" SG_ 2521142529 SLV_SWID_2_IVD_1 "24.07.05";
BA_ "RoutingFactor" SG_ 2521142529 SLV_SWID_2_IVD_1 0;
BA_ "UserSigValidity" SG_ 2521142529 SLV_SWID_2_IVD_1 0;
BA_ "GenSigSendType" SG_ 2521142529 SLV_SWID_2_IVD_1 2;
BA_ "Version" SG_ 2533738753 L_UWB_FRNK_FD_Crc5Val "24.07.05";
BA_ "RoutingFactor" SG_ 2533738753 L_UWB_FRNK_FD_Crc5Val 0;
BA_ "UserSigValidity" SG_ 2533738753 L_UWB_FRNK_FD_Crc5Val 3;
BA_ "GenSigStartValue" SG_ 2533738753 L_UWB_FRNK_FD_Crc5Val 65535;
BA_ "GenSigSendType" SG_ 2533738753 L_UWB_FRNK_FD_Crc5Val 2;
BA_ "Description" SG_ 2533738753 L_UWB_FRNK_FD_Crc5Val "The data area for CRC calculation is based on the data length (DLC) of the message DB.

The CRC shall be calculated over the entire data block (excluding the CRC bytes) including the user data, alive counter and Data ID



- CRC Polynomial (0x1021) , Ini";
BA_ "Version" SG_ 2533738753 L_UWB_FRNK_FD_AlvCnt5Val "24.07.05";
BA_ "RoutingFactor" SG_ 2533738753 L_UWB_FRNK_FD_AlvCnt5Val 0;
BA_ "UserSigValidity" SG_ 2533738753 L_UWB_FRNK_FD_AlvCnt5Val 3;
BA_ "GenSigSendType" SG_ 2533738753 L_UWB_FRNK_FD_AlvCnt5Val 2;
BA_ "Description" SG_ 2533738753 L_UWB_FRNK_FD_AlvCnt5Val "For the first transmission request for a data element the counter shall be initialized with 0 and shall be incremented by 1 for every subsequent send request. 

When the counter reaches the maximum value(0xFF), then it shall restart with 0 for the next s";
BA_ "Version" SG_ 2533738753 FRNK_SWID_3_IVD_2 "24.07.05";
BA_ "RoutingFactor" SG_ 2533738753 FRNK_SWID_3_IVD_2 0;
BA_ "UserSigValidity" SG_ 2533738753 FRNK_SWID_3_IVD_2 0;
BA_ "GenSigSendType" SG_ 2533738753 FRNK_SWID_3_IVD_2 2;
BA_ "Version" SG_ 2529540865 L_UWB_RR_FD_Crc7Val "24.07.05";
BA_ "RoutingFactor" SG_ 2529540865 L_UWB_RR_FD_Crc7Val 0;
BA_ "UserSigValidity" SG_ 2529540865 L_UWB_RR_FD_Crc7Val 3;
BA_ "GenSigStartValue" SG_ 2529540865 L_UWB_RR_FD_Crc7Val 65535;
BA_ "GenSigSendType" SG_ 2529540865 L_UWB_RR_FD_Crc7Val 2;
BA_ "Description" SG_ 2529540865 L_UWB_RR_FD_Crc7Val "The data area for CRC calculation is based on the data length (DLC) of the message DB.

The CRC shall be calculated over the entire data block (excluding the CRC bytes) including the user data, alive counter and Data ID



- CRC Polynomial (0x1021) , Ini";
BA_ "Version" SG_ 2529540865 L_UWB_RR_FD_AlvCnt7Val "24.07.05";
BA_ "RoutingFactor" SG_ 2529540865 L_UWB_RR_FD_AlvCnt7Val 0;
BA_ "UserSigValidity" SG_ 2529540865 L_UWB_RR_FD_AlvCnt7Val 3;
BA_ "GenSigSendType" SG_ 2529540865 L_UWB_RR_FD_AlvCnt7Val 2;
BA_ "Description" SG_ 2529540865 L_UWB_RR_FD_AlvCnt7Val "For the first transmission request for a data element the counter shall be initialized with 0 and shall be incremented by 1 for every subsequent send request. 

When the counter reaches the maximum value(0xFF), then it shall restart with 0 for the next s";
BA_ "Version" SG_ 2529540865 RR_SWID_4_IVD_2 "24.07.05";
BA_ "RoutingFactor" SG_ 2529540865 RR_SWID_4_IVD_2 0;
BA_ "UserSigValidity" SG_ 2529540865 RR_SWID_4_IVD_2 0;
BA_ "GenSigSendType" SG_ 2529540865 RR_SWID_4_IVD_2 2;
BA_ "Version" SG_ 2521143041 L_UWB_BLE_SLV_FD_Crc11Val "24.07.05";
BA_ "RoutingFactor" SG_ 2521143041 L_UWB_BLE_SLV_FD_Crc11Val 0;
BA_ "UserSigValidity" SG_ 2521143041 L_UWB_BLE_SLV_FD_Crc11Val 3;
BA_ "GenSigStartValue" SG_ 2521143041 L_UWB_BLE_SLV_FD_Crc11Val 65535;
BA_ "GenSigSendType" SG_ 2521143041 L_UWB_BLE_SLV_FD_Crc11Val 2;
BA_ "Description" SG_ 2521143041 L_UWB_BLE_SLV_FD_Crc11Val "The data area for CRC calculation is based on the data length (DLC) of the message DB.

The CRC shall be calculated over the entire data block (excluding the CRC bytes) including the user data, alive counter and Data ID



- CRC Polynomial (0x1021) , Ini";
BA_ "Version" SG_ 2521143041 L_UWB_BLE_SLV_FD_AlvCnt11Val "24.07.05";
BA_ "RoutingFactor" SG_ 2521143041 L_UWB_BLE_SLV_FD_AlvCnt11Val 0;
BA_ "UserSigValidity" SG_ 2521143041 L_UWB_BLE_SLV_FD_AlvCnt11Val 3;
BA_ "GenSigSendType" SG_ 2521143041 L_UWB_BLE_SLV_FD_AlvCnt11Val 2;
BA_ "Description" SG_ 2521143041 L_UWB_BLE_SLV_FD_AlvCnt11Val "For the first transmission request for a data element the counter shall be initialized with 0 and shall be incremented by 1 for every subsequent send request. 

When the counter reaches the maximum value(0xFF), then it shall restart with 0 for the next s";
BA_ "Version" SG_ 2521143041 SLV_SWID_3_IVD_1 "24.07.05";
BA_ "RoutingFactor" SG_ 2521143041 SLV_SWID_3_IVD_1 0;
BA_ "UserSigValidity" SG_ 2521143041 SLV_SWID_3_IVD_1 0;
BA_ "GenSigSendType" SG_ 2521143041 SLV_SWID_3_IVD_1 2;
BA_ "Version" SG_ 2533739265 L_UWB_FRNK_FD_Crc7Val "24.07.05";
BA_ "RoutingFactor" SG_ 2533739265 L_UWB_FRNK_FD_Crc7Val 0;
BA_ "UserSigValidity" SG_ 2533739265 L_UWB_FRNK_FD_Crc7Val 3;
BA_ "GenSigStartValue" SG_ 2533739265 L_UWB_FRNK_FD_Crc7Val 65535;
BA_ "GenSigSendType" SG_ 2533739265 L_UWB_FRNK_FD_Crc7Val 2;
BA_ "Description" SG_ 2533739265 L_UWB_FRNK_FD_Crc7Val "The data area for CRC calculation is based on the data length (DLC) of the message DB.

The CRC shall be calculated over the entire data block (excluding the CRC bytes) including the user data, alive counter and Data ID



- CRC Polynomial (0x1021) , Ini";
BA_ "Version" SG_ 2533739265 L_UWB_FRNK_FD_AlvCnt7Val "24.07.05";
BA_ "RoutingFactor" SG_ 2533739265 L_UWB_FRNK_FD_AlvCnt7Val 0;
BA_ "UserSigValidity" SG_ 2533739265 L_UWB_FRNK_FD_AlvCnt7Val 3;
BA_ "GenSigSendType" SG_ 2533739265 L_UWB_FRNK_FD_AlvCnt7Val 2;
BA_ "Description" SG_ 2533739265 L_UWB_FRNK_FD_AlvCnt7Val "For the first transmission request for a data element the counter shall be initialized with 0 and shall be incremented by 1 for every subsequent send request. 

When the counter reaches the maximum value(0xFF), then it shall restart with 0 for the next s";
BA_ "Version" SG_ 2533739265 FRNK_SWID_4_IVD_2 "24.07.05";
BA_ "RoutingFactor" SG_ 2533739265 FRNK_SWID_4_IVD_2 0;
BA_ "UserSigValidity" SG_ 2533739265 FRNK_SWID_4_IVD_2 0;
BA_ "GenSigSendType" SG_ 2533739265 FRNK_SWID_4_IVD_2 2;
BA_ "Version" SG_ 2214593024 EDT_BLE_Dvp_Data "23.10.02";
BA_ "UserSigValidity" SG_ 2214593024 EDT_BLE_Dvp_Data 0;
BA_ "GenSigSendType" SG_ 2214593024 EDT_BLE_Dvp_Data 2;
BA_ "Version" SG_ 2214593025 EDT_DH_Dvp_Data "23.01.02";
BA_ "UserSigValidity" SG_ 2214593025 EDT_DH_Dvp_Data 0;
BA_ "GenSigSendType" SG_ 2214593025 EDT_DH_Dvp_Data 2;
BA_ "Version" SG_ 2214593026 EDT_UWB_Dvp_Data "23.10.02";
BA_ "UserSigValidity" SG_ 2214593026 EDT_UWB_Dvp_Data 0;
BA_ "GenSigSendType" SG_ 2214593026 EDT_UWB_Dvp_Data 2;
BA_ "Version" SG_ 1087 CCU_01_Crc1Val "21.09.03";
BA_ "NetworkRequestHoldingTime" SG_ 1087 CCU_01_Crc1Val 5000;
BA_ "NetworkRequest" SG_ 1087 CCU_01_Crc1Val 0;
BA_ "UserSigValidity" SG_ 1087 CCU_01_Crc1Val 0;
BA_ "GenSigSendType" SG_ 1087 CCU_01_Crc1Val 4;
BA_ "Description" SG_ 1087 CCU_01_Crc1Val "The data area for CRC calculation is based on the data length (DLC) of the message DB.

The CRC shall be calculated over the entire data block (excluding the CRC bytes) including the user data, alive counter and Data ID 

 

- CRC Polynomial (0x1D) , Ini";
BA_ "Version" SG_ 1087 CCU_01_AlvCnt1Val "21.09.03";
BA_ "NetworkRequestHoldingTime" SG_ 1087 CCU_01_AlvCnt1Val 5000;
BA_ "NetworkRequest" SG_ 1087 CCU_01_AlvCnt1Val 0;
BA_ "UserSigValidity" SG_ 1087 CCU_01_AlvCnt1Val 0;
BA_ "GenSigSendType" SG_ 1087 CCU_01_AlvCnt1Val 4;
BA_ "Description" SG_ 1087 CCU_01_AlvCnt1Val "For the first transmission request for a data element the counter shall be initialized with 0 and shall be incremented by 1

for every subsequent send request. When the counter reaches the maximum value(0xE), then it shall restart with 0 for the next sen";
BA_ "Version" SG_ 1087 CCU_ForcedPowerOffReq "20.03.01";
BA_ "NetworkRequestHoldingTime" SG_ 1087 CCU_ForcedPowerOffReq 5000;
BA_ "NetworkRequest" SG_ 1087 CCU_ForcedPowerOffReq 0;
BA_ "UserSigValidity" SG_ 1087 CCU_ForcedPowerOffReq 0;
BA_ "GenSigSendType" SG_ 1087 CCU_ForcedPowerOffReq 4;
BA_ "Version" SG_ 2214592730 L_UWB_BLE_SLV_FD_Crc22Val "23.11.05";
BA_ "UserSigValidity" SG_ 2214592730 L_UWB_BLE_SLV_FD_Crc22Val 3;
BA_ "GenSigStartValue" SG_ 2214592730 L_UWB_BLE_SLV_FD_Crc22Val 65535;
BA_ "GenSigSendType" SG_ 2214592730 L_UWB_BLE_SLV_FD_Crc22Val 4;
BA_ "Description" SG_ 2214592730 L_UWB_BLE_SLV_FD_Crc22Val "The data area for CRC calculation is based on the data length (DLC) of the message DB.

The CRC shall be calculated over the entire data block (excluding the CRC bytes) including the user data, alive counter and Data ID



- CRC Polynomial (0x1021) , Ini";
BA_ "Version" SG_ 2214592730 L_UWB_BLE_SLV_FD_AlvCnt22Val "23.11.05";
BA_ "UserSigValidity" SG_ 2214592730 L_UWB_BLE_SLV_FD_AlvCnt22Val 3;
BA_ "GenSigSendType" SG_ 2214592730 L_UWB_BLE_SLV_FD_AlvCnt22Val 4;
BA_ "Description" SG_ 2214592730 L_UWB_BLE_SLV_FD_AlvCnt22Val "For the first transmission request for a data element the counter shall be initialized with 0 and shall be incremented by 1 for every subsequent send request. 

When the counter reaches the maximum value(0xFF), then it shall restart with 0 for the next s";
BA_ "Version" SG_ 2214592730 SLV_DisconnectDKID "23.11.05";
BA_ "UserSigValidity" SG_ 2214592730 SLV_DisconnectDKID 0;
BA_ "GenSigSendType" SG_ 2214592730 SLV_DisconnectDKID 4;
BA_ "Description" SG_ 2214592730 SLV_DisconnectDKID "For checking disconnected DK ID";
BA_ "Version" SG_ 2214592730 SLV_DisconnectReason "23.11.05";
BA_ "UserSigValidity" SG_ 2214592730 SLV_DisconnectReason 0;
BA_ "GenSigSendType" SG_ 2214592730 SLV_DisconnectReason 4;
BA_ "Description" SG_ 2214592730 SLV_DisconnectReason "For analyzing disconnected reason";
BA_ "Version" SG_ 2214592730 SLV_BLE_ErrorReturn "24.01.04";
BA_ "UserSigValidity" SG_ 2214592730 SLV_BLE_ErrorReturn 0;
BA_ "GenSigSendType" SG_ 2214592730 SLV_BLE_ErrorReturn 4;
BA_ "Description" SG_ 2214592730 SLV_BLE_ErrorReturn "Valid Range : 0x00 ~ 0xFF";
BA_ "Version" SG_ 2525340161 L_UWB_FL_FD_Crc6Val "24.07.05";
BA_ "RoutingFactor" SG_ 2525340161 L_UWB_FL_FD_Crc6Val 0;
BA_ "UserSigValidity" SG_ 2525340161 L_UWB_FL_FD_Crc6Val 3;
BA_ "GenSigStartValue" SG_ 2525340161 L_UWB_FL_FD_Crc6Val 65535;
BA_ "GenSigSendType" SG_ 2525340161 L_UWB_FL_FD_Crc6Val 2;
BA_ "Description" SG_ 2525340161 L_UWB_FL_FD_Crc6Val "The data area for CRC calculation is based on the data length (DLC) of the message DB.

The CRC shall be calculated over the entire data block (excluding the CRC bytes) including the user data, alive counter and Data ID



- CRC Polynomial (0x1021) , Ini";
BA_ "Version" SG_ 2525340161 L_UWB_FL_FD_AlvCnt6Val "24.07.05";
BA_ "RoutingFactor" SG_ 2525340161 L_UWB_FL_FD_AlvCnt6Val 0;
BA_ "UserSigValidity" SG_ 2525340161 L_UWB_FL_FD_AlvCnt6Val 3;
BA_ "GenSigSendType" SG_ 2525340161 L_UWB_FL_FD_AlvCnt6Val 2;
BA_ "Description" SG_ 2525340161 L_UWB_FL_FD_AlvCnt6Val "For the first transmission request for a data element the counter shall be initialized with 0 and shall be incremented by 1 for every subsequent send request. 

When the counter reaches the maximum value(0xFF), then it shall restart with 0 for the next s";
BA_ "Version" SG_ 2525340161 FL_SWID_4_IVD_1 "24.07.05";
BA_ "RoutingFactor" SG_ 2525340161 FL_SWID_4_IVD_1 0;
BA_ "UserSigValidity" SG_ 2525340161 FL_SWID_4_IVD_1 0;
BA_ "GenSigSendType" SG_ 2525340161 FL_SWID_4_IVD_1 2;
BA_ "Version" SG_ 2214592735 UWB_FR_Dvp_Data "23.01.02";
BA_ "UserSigValidity" SG_ 2214592735 UWB_FR_Dvp_Data 0;
BA_ "GenSigSendType" SG_ 2214592735 UWB_FR_Dvp_Data 2;
BA_ "Version" SG_ 2214592720 L_UWB_FR_FD_Crc1Val "23.01.02";
BA_ "UserSigValidity" SG_ 2214592720 L_UWB_FR_FD_Crc1Val 3;
BA_ "GenSigStartValue" SG_ 2214592720 L_UWB_FR_FD_Crc1Val 65535;
BA_ "GenSigSendType" SG_ 2214592720 L_UWB_FR_FD_Crc1Val 4;
BA_ "Description" SG_ 2214592720 L_UWB_FR_FD_Crc1Val "The data area for CRC calculation is based on the data length (DLC) of the message DB.

The CRC shall be calculated over the entire data block (excluding the CRC bytes) including the user data, alive counter and Data ID



- CRC Polynomial (0x1021) , Ini";
BA_ "Version" SG_ 2214592720 L_UWB_FR_FD_AlvCnt1Val "23.01.02";
BA_ "UserSigValidity" SG_ 2214592720 L_UWB_FR_FD_AlvCnt1Val 3;
BA_ "GenSigSendType" SG_ 2214592720 L_UWB_FR_FD_AlvCnt1Val 4;
BA_ "Description" SG_ 2214592720 L_UWB_FR_FD_AlvCnt1Val "For the first transmission request for a data element the counter shall be initialized with 0 and shall be incremented by 1 for every subsequent send request. 

When the counter reaches the maximum value(0xFF), then it shall restart with 0 for the next s";
BA_ "Version" SG_ 2214592720 UWB_FR_UWB_Decrypt_FB "23.01.02";
BA_ "UserSigValidity" SG_ 2214592720 UWB_FR_UWB_Decrypt_FB 0;
BA_ "GenSigSendType" SG_ 2214592720 UWB_FR_UWB_Decrypt_FB 4;
BA_ "Version" SG_ 2214592720 UWB_FR_MST_Decrypt_FB "23.01.02";
BA_ "UserSigValidity" SG_ 2214592720 UWB_FR_MST_Decrypt_FB 0;
BA_ "GenSigSendType" SG_ 2214592720 UWB_FR_MST_Decrypt_FB 4;
BA_ "Version" SG_ 2214592720 UWB_FR_OTA_Rsp "24.07.05";
BA_ "UserSigValidity" SG_ 2214592720 UWB_FR_OTA_Rsp 0;
BA_ "GenSigSendType" SG_ 2214592720 UWB_FR_OTA_Rsp 4;
BA_ "Description" SG_ 2214592720 UWB_FR_OTA_Rsp "UWB FR OTA response";
BA_ "Version" SG_ 2214592720 UWB_FR_UWB_IC_Status "24.04.03";
BA_ "UserSigValidity" SG_ 2214592720 UWB_FR_UWB_IC_Status 0;
BA_ "GenSigSendType" SG_ 2214592720 UWB_FR_UWB_IC_Status 4;
BA_ "Description" SG_ 2214592720 UWB_FR_UWB_IC_Status "UWB IC Status Message";
BA_ "Version" SG_ 2214592721 L_UWB_FR_FD_Crc2Val "23.01.02";
BA_ "UserSigValidity" SG_ 2214592721 L_UWB_FR_FD_Crc2Val 3;
BA_ "GenSigStartValue" SG_ 2214592721 L_UWB_FR_FD_Crc2Val 65535;
BA_ "GenSigSendType" SG_ 2214592721 L_UWB_FR_FD_Crc2Val 4;
BA_ "Description" SG_ 2214592721 L_UWB_FR_FD_Crc2Val "The data area for CRC calculation is based on the data length (DLC) of the message DB.

The CRC shall be calculated over the entire data block (excluding the CRC bytes) including the user data, alive counter and Data ID



- CRC Polynomial (0x1021) , Ini";
BA_ "Version" SG_ 2214592721 L_UWB_FR_FD_AlvCnt2Val "23.01.02";
BA_ "UserSigValidity" SG_ 2214592721 L_UWB_FR_FD_AlvCnt2Val 3;
BA_ "GenSigSendType" SG_ 2214592721 L_UWB_FR_FD_AlvCnt2Val 4;
BA_ "Description" SG_ 2214592721 L_UWB_FR_FD_AlvCnt2Val "For the first transmission request for a data element the counter shall be initialized with 0 and shall be incremented by 1 for every subsequent send request. 

When the counter reaches the maximum value(0xFF), then it shall restart with 0 for the next s";
BA_ "Version" SG_ 2214592721 UWB_FR_FOB_RSD_Enc_Result "23.01.02";
BA_ "UserSigValidity" SG_ 2214592721 UWB_FR_FOB_RSD_Enc_Result 0;
BA_ "GenSigSendType" SG_ 2214592721 UWB_FR_FOB_RSD_Enc_Result 4;
BA_REL_ "GenSigTimeoutTime" BU_SG_REL_ L_UWB_BLE_MST_FD SG_ 2214592593 DKID_Del 0;
BA_REL_ "GenSigTimeoutTime" BU_SG_REL_ L_UWB_BLE_SLV_FD SG_ 2214592593 DKID_Del 0;
BA_REL_ "GenSigTimeoutTime" BU_SG_REL_ L_UWB_BLE_MST_FD SG_ 2214592593 UWB_Ranging_Cmd_DKID 0;
BA_REL_ "GenSigTimeoutTime" BU_SG_REL_ L_UWB_BLE_SLV_FD SG_ 2214592593 UWB_Ranging_Cmd_DKID 0;
BA_REL_ "GenSigTimeoutTime" BU_SG_REL_ L_UWB_FL_FD SG_ 2214592593 UWB_Ranging_Cmd_DKID 0;
BA_REL_ "GenSigTimeoutTime" BU_SG_REL_ L_UWB_FRNK_FD SG_ 2214592593 UWB_Ranging_Cmd_DKID 0;
BA_REL_ "GenSigTimeoutTime" BU_SG_REL_ L_UWB_FR_FD SG_ 2214592593 UWB_Ranging_Cmd_DKID 0;
BA_REL_ "GenSigTimeoutTime" BU_SG_REL_ L_UWB_RL_FD SG_ 2214592593 UWB_Ranging_Cmd_DKID 0;
BA_REL_ "GenSigTimeoutTime" BU_SG_REL_ L_UWB_RR_FD SG_ 2214592593 UWB_Ranging_Cmd_DKID 0;
BA_REL_ "GenSigTimeoutTime" BU_SG_REL_ L_UWB_TRNK_FD SG_ 2214592593 UWB_Ranging_Cmd_DKID 0;
BA_REL_ "GenSigTimeoutTime" BU_SG_REL_ L_UWB_BLE_MST_FD SG_ 2214592593 UWB_Ranging_Cmd_Val 0;
BA_REL_ "GenSigTimeoutTime" BU_SG_REL_ L_UWB_BLE_SLV_FD SG_ 2214592593 UWB_Ranging_Cmd_Val 0;
BA_REL_ "GenSigTimeoutTime" BU_SG_REL_ L_UWB_FL_FD SG_ 2214592593 UWB_Ranging_Cmd_Val 0;
BA_REL_ "GenSigTimeoutTime" BU_SG_REL_ L_UWB_FRNK_FD SG_ 2214592593 UWB_Ranging_Cmd_Val 0;
BA_REL_ "GenSigTimeoutTime" BU_SG_REL_ L_UWB_FR_FD SG_ 2214592593 UWB_Ranging_Cmd_Val 0;
BA_REL_ "GenSigTimeoutTime" BU_SG_REL_ L_UWB_RL_FD SG_ 2214592593 UWB_Ranging_Cmd_Val 0;
BA_REL_ "GenSigTimeoutTime" BU_SG_REL_ L_UWB_RR_FD SG_ 2214592593 UWB_Ranging_Cmd_Val 0;
BA_REL_ "GenSigTimeoutTime" BU_SG_REL_ L_UWB_TRNK_FD SG_ 2214592593 UWB_Ranging_Cmd_Val 0;
BA_REL_ "GenSigTimeoutTime" BU_SG_REL_ L_UWB_BLE_MST_FD SG_ 2214592593 BDC_RndNum_Trgt 0;
BA_REL_ "GenSigTimeoutTime" BU_SG_REL_ L_UWB_BLE_SLV_FD SG_ 2214592593 BDC_RndNum_Trgt 0;
BA_REL_ "GenSigTimeoutTime" BU_SG_REL_ L_UWB_FL_FD SG_ 2214592593 BDC_RndNum_Trgt 0;
BA_REL_ "GenSigTimeoutTime" BU_SG_REL_ L_UWB_FRNK_FD SG_ 2214592593 BDC_RndNum_Trgt 0;
BA_REL_ "GenSigTimeoutTime" BU_SG_REL_ L_UWB_FR_FD SG_ 2214592593 BDC_RndNum_Trgt 0;
BA_REL_ "GenSigTimeoutTime" BU_SG_REL_ L_UWB_RL_FD SG_ 2214592593 BDC_RndNum_Trgt 0;
BA_REL_ "GenSigTimeoutTime" BU_SG_REL_ L_UWB_RR_FD SG_ 2214592593 BDC_RndNum_Trgt 0;
BA_REL_ "GenSigTimeoutTime" BU_SG_REL_ L_UWB_TRNK_FD SG_ 2214592593 BDC_RndNum_Trgt 0;
BA_REL_ "GenSigTimeoutTime" BU_SG_REL_ L_UWB_BLE_MST_FD SG_ 2214592593 BDC_RndNum_TRCod 0;
BA_REL_ "GenSigTimeoutTime" BU_SG_REL_ L_UWB_BLE_SLV_FD SG_ 2214592593 BDC_RndNum_TRCod 0;
BA_REL_ "GenSigTimeoutTime" BU_SG_REL_ L_UWB_FL_FD SG_ 2214592593 BDC_RndNum_TRCod 0;
BA_REL_ "GenSigTimeoutTime" BU_SG_REL_ L_UWB_FRNK_FD SG_ 2214592593 BDC_RndNum_TRCod 0;
BA_REL_ "GenSigTimeoutTime" BU_SG_REL_ L_UWB_FR_FD SG_ 2214592593 BDC_RndNum_TRCod 0;
BA_REL_ "GenSigTimeoutTime" BU_SG_REL_ L_UWB_RL_FD SG_ 2214592593 BDC_RndNum_TRCod 0;
BA_REL_ "GenSigTimeoutTime" BU_SG_REL_ L_UWB_RR_FD SG_ 2214592593 BDC_RndNum_TRCod 0;
BA_REL_ "GenSigTimeoutTime" BU_SG_REL_ L_UWB_TRNK_FD SG_ 2214592593 BDC_RndNum_TRCod 0;
BA_REL_ "GenSigTimeoutTime" BU_SG_REL_ L_UWB_BLE_MST_FD SG_ 2214592593 BDC_RndNum_Cmd 0;
BA_REL_ "GenSigTimeoutTime" BU_SG_REL_ L_UWB_BLE_SLV_FD SG_ 2214592593 BDC_RndNum_Cmd 0;
BA_REL_ "GenSigTimeoutTime" BU_SG_REL_ L_UWB_FL_FD SG_ 2214592593 BDC_RndNum_Cmd 0;
BA_REL_ "GenSigTimeoutTime" BU_SG_REL_ L_UWB_FRNK_FD SG_ 2214592593 BDC_RndNum_Cmd 0;
BA_REL_ "GenSigTimeoutTime" BU_SG_REL_ L_UWB_FR_FD SG_ 2214592593 BDC_RndNum_Cmd 0;
BA_REL_ "GenSigTimeoutTime" BU_SG_REL_ L_UWB_RL_FD SG_ 2214592593 BDC_RndNum_Cmd 0;
BA_REL_ "GenSigTimeoutTime" BU_SG_REL_ L_UWB_RR_FD SG_ 2214592593 BDC_RndNum_Cmd 0;
BA_REL_ "GenSigTimeoutTime" BU_SG_REL_ L_UWB_TRNK_FD SG_ 2214592593 BDC_RndNum_Cmd 0;
BA_REL_ "GenSigTimeoutTime" BU_SG_REL_ L_UWB_BLE_MST_FD SG_ 2214592593 BDC_RndNum 0;
BA_REL_ "GenSigTimeoutTime" BU_SG_REL_ L_UWB_BLE_SLV_FD SG_ 2214592593 BDC_RndNum 0;
BA_REL_ "GenSigTimeoutTime" BU_SG_REL_ L_UWB_FL_FD SG_ 2214592593 BDC_RndNum 0;
BA_REL_ "GenSigTimeoutTime" BU_SG_REL_ L_UWB_FRNK_FD SG_ 2214592593 BDC_RndNum 0;
BA_REL_ "GenSigTimeoutTime" BU_SG_REL_ L_UWB_FR_FD SG_ 2214592593 BDC_RndNum 0;
BA_REL_ "GenSigTimeoutTime" BU_SG_REL_ L_UWB_RL_FD SG_ 2214592593 BDC_RndNum 0;
BA_REL_ "GenSigTimeoutTime" BU_SG_REL_ L_UWB_RR_FD SG_ 2214592593 BDC_RndNum 0;
BA_REL_ "GenSigTimeoutTime" BU_SG_REL_ L_UWB_TRNK_FD SG_ 2214592593 BDC_RndNum 0;
BA_REL_ "GenSigTimeoutTime" BU_SG_REL_ L_UWB_BLE_MST_FD SG_ 2214592593 BDC_Decrypt_FB 0;
BA_REL_ "GenSigTimeoutTime" BU_SG_REL_ L_UWB_BLE_SLV_FD SG_ 2214592593 BDC_Decrypt_FB 0;
BA_REL_ "GenSigTimeoutTime" BU_SG_REL_ L_UWB_BLE_MST_FD SG_ 2214592593 DKID_Set 0;
BA_REL_ "GenSigTimeoutTime" BU_SG_REL_ L_UWB_BLE_SLV_FD SG_ 2214592593 DKID_Set 0;
BA_REL_ "GenSigTimeoutTime" BU_SG_REL_ L_WPC_FD SG_ 2214592592 WPC_NFC_Deselect_Cmd 0;
BA_REL_ "GenSigTimeoutTime" BU_SG_REL_ L_WPC_FD SG_ 2214592592 WPC2_NFC_Deselect_Cmd 0;
BA_REL_ "GenSigTimeoutTime" BU_SG_REL_ L_DHL_FD SG_ 2214592592 DHL_NFC_Deselect_Cmd 0;
BA_REL_ "GenSigTimeoutTime" BU_SG_REL_ L_DHR_FD SG_ 2214592592 DHR_NFC_Deselect_Cmd 0;
BA_REL_ "GenSigTimeoutTime" BU_SG_REL_ L_DHRL_FD SG_ 2214592592 DHRL_NFC_Deselect_Cmd 0;
BA_REL_ "GenSigTimeoutTime" BU_SG_REL_ L_DHRR_FD SG_ 2214592592 DHRR_NFC_Deselect_Cmd 0;
BA_REL_ "GenSigTimeoutTime" BU_SG_REL_ L_UWB_BLE_MST_FD SG_ 2214592595 BDC_To_BLE_Enc_Data2 0;
BA_REL_ "GenSigTimeoutTime" BU_SG_REL_ L_UWB_BLE_SLV_FD SG_ 2214592595 BDC_To_BLE_Enc_Data2 0;
BA_REL_ "GenSigTimeoutTime" BU_SG_REL_ L_UWB_BLE_MST_FD SG_ 2214592594 BDC_To_BLE_Enc_Data1 0;
BA_REL_ "GenSigTimeoutTime" BU_SG_REL_ L_UWB_BLE_SLV_FD SG_ 2214592594 BDC_To_BLE_Enc_Data1 0;
BA_REL_ "GenSigTimeoutTime" BU_SG_REL_ L_UWB_BLE_MST_FD SG_ 2214592597 BDC_To_UWB_Enc_Data2 0;
BA_REL_ "GenSigTimeoutTime" BU_SG_REL_ L_UWB_BLE_SLV_FD SG_ 2214592597 BDC_To_UWB_Enc_Data2 0;
BA_REL_ "GenSigTimeoutTime" BU_SG_REL_ L_UWB_FL_FD SG_ 2214592597 BDC_To_UWB_Enc_Data2 0;
BA_REL_ "GenSigTimeoutTime" BU_SG_REL_ L_UWB_FRNK_FD SG_ 2214592597 BDC_To_UWB_Enc_Data2 0;
BA_REL_ "GenSigTimeoutTime" BU_SG_REL_ L_UWB_FR_FD SG_ 2214592597 BDC_To_UWB_Enc_Data2 0;
BA_REL_ "GenSigTimeoutTime" BU_SG_REL_ L_UWB_RL_FD SG_ 2214592597 BDC_To_UWB_Enc_Data2 0;
BA_REL_ "GenSigTimeoutTime" BU_SG_REL_ L_UWB_RR_FD SG_ 2214592597 BDC_To_UWB_Enc_Data2 0;
BA_REL_ "GenSigTimeoutTime" BU_SG_REL_ L_UWB_TRNK_FD SG_ 2214592597 BDC_To_UWB_Enc_Data2 0;
BA_REL_ "GenSigTimeoutTime" BU_SG_REL_ L_UWB_BLE_MST_FD SG_ 2214592596 BDC_To_UWB_Enc_Data1 0;
BA_REL_ "GenSigTimeoutTime" BU_SG_REL_ L_UWB_BLE_SLV_FD SG_ 2214592596 BDC_To_UWB_Enc_Data1 0;
BA_REL_ "GenSigTimeoutTime" BU_SG_REL_ L_UWB_FL_FD SG_ 2214592596 BDC_To_UWB_Enc_Data1 0;
BA_REL_ "GenSigTimeoutTime" BU_SG_REL_ L_UWB_FRNK_FD SG_ 2214592596 BDC_To_UWB_Enc_Data1 0;
BA_REL_ "GenSigTimeoutTime" BU_SG_REL_ L_UWB_FR_FD SG_ 2214592596 BDC_To_UWB_Enc_Data1 0;
BA_REL_ "GenSigTimeoutTime" BU_SG_REL_ L_UWB_RL_FD SG_ 2214592596 BDC_To_UWB_Enc_Data1 0;
BA_REL_ "GenSigTimeoutTime" BU_SG_REL_ L_UWB_RR_FD SG_ 2214592596 BDC_To_UWB_Enc_Data1 0;
BA_REL_ "GenSigTimeoutTime" BU_SG_REL_ L_UWB_TRNK_FD SG_ 2214592596 BDC_To_UWB_Enc_Data1 0;
BA_REL_ "GenSigTimeoutTime" BU_SG_REL_ L_UWB_BLE_MST_FD SG_ 2214592598 BDC_To_UWB_Enc_Data3 0;
BA_REL_ "GenSigTimeoutTime" BU_SG_REL_ L_UWB_BLE_SLV_FD SG_ 2214592598 BDC_To_UWB_Enc_Data3 0;
BA_REL_ "GenSigTimeoutTime" BU_SG_REL_ L_UWB_FL_FD SG_ 2214592598 BDC_To_UWB_Enc_Data3 0;
BA_REL_ "GenSigTimeoutTime" BU_SG_REL_ L_UWB_FRNK_FD SG_ 2214592598 BDC_To_UWB_Enc_Data3 0;
BA_REL_ "GenSigTimeoutTime" BU_SG_REL_ L_UWB_FR_FD SG_ 2214592598 BDC_To_UWB_Enc_Data3 0;
BA_REL_ "GenSigTimeoutTime" BU_SG_REL_ L_UWB_RL_FD SG_ 2214592598 BDC_To_UWB_Enc_Data3 0;
BA_REL_ "GenSigTimeoutTime" BU_SG_REL_ L_UWB_RR_FD SG_ 2214592598 BDC_To_UWB_Enc_Data3 0;
BA_REL_ "GenSigTimeoutTime" BU_SG_REL_ L_UWB_TRNK_FD SG_ 2214592598 BDC_To_UWB_Enc_Data3 0;
BA_REL_ "GenSigTimeoutTime" BU_SG_REL_ L_UWB_BLE_MST_FD SG_ 2281701632 UWB_RR_SW_MCU_Ver_Major 1500;
BA_REL_ "GenSigTimeoutTime" BU_SG_REL_ L_UWB_BLE_MST_FD SG_ 2281701632 UWB_RR_SW_MCU_Ver_Minor 1500;
BA_REL_ "GenSigTimeoutTime" BU_SG_REL_ L_UWB_BLE_MST_FD SG_ 2281701632 UWB_RR_SW_IC_Ver_Major 1500;
BA_REL_ "GenSigTimeoutTime" BU_SG_REL_ L_UWB_BLE_MST_FD SG_ 2281701632 UWB_RR_SW_IC_Ver_Minor 1500;
BA_REL_ "GenSigTimeoutTime" BU_SG_REL_ L_UWB_BLE_MST_FD SG_ 2281701632 UWB_RR_DTC 1500;
BA_REL_ "GenSigTimeoutTime" BU_SG_REL_ GW_BDC_FD SG_ 2281701632 UWB_RR_Status1 1500;
BA_REL_ "GenSigTimeoutTime" BU_SG_REL_ L_UWB_BLE_MST_FD SG_ 2281701632 UWB_RR_Status1 1500;
BA_REL_ "GenSigTimeoutTime" BU_SG_REL_ GW_BDC_FD SG_ 2281701632 UWB_RR_Status2 1500;
BA_REL_ "GenSigTimeoutTime" BU_SG_REL_ L_UWB_BLE_MST_FD SG_ 2281701632 UWB_RR_Status2 1500;
BA_REL_ "GenSigTimeoutTime" BU_SG_REL_ GW_BDC_FD SG_ 2281701632 UWB_RR_Status3 1500;
BA_REL_ "GenSigTimeoutTime" BU_SG_REL_ L_UWB_BLE_MST_FD SG_ 2281701632 UWB_RR_Status3 1500;
BA_REL_ "GenSigTimeoutTime" BU_SG_REL_ GW_BDC_FD SG_ 2281701632 UWB_RR_Status4 1500;
BA_REL_ "GenSigTimeoutTime" BU_SG_REL_ L_UWB_BLE_MST_FD SG_ 2281701632 UWB_RR_Status4 1500;
BA_REL_ "GenSigTimeoutTime" BU_SG_REL_ GW_BDC_FD SG_ 2281701632 UWB_RR_Status5 1500;
BA_REL_ "GenSigTimeoutTime" BU_SG_REL_ L_UWB_BLE_MST_FD SG_ 2281701632 UWB_RR_Status5 1500;
BA_REL_ "GenSigTimeoutTime" BU_SG_REL_ GW_BDC_FD SG_ 2281701632 UWB_RR_Status6 1500;
BA_REL_ "GenSigTimeoutTime" BU_SG_REL_ L_UWB_BLE_MST_FD SG_ 2281701632 UWB_RR_Status6 1500;
BA_REL_ "GenSigTimeoutTime" BU_SG_REL_ GW_BDC_FD SG_ 2281701632 UWB_RR_Status7 1500;
BA_REL_ "GenSigTimeoutTime" BU_SG_REL_ L_UWB_BLE_MST_FD SG_ 2281701632 UWB_RR_Status7 1500;
BA_REL_ "GenSigTimeoutTime" BU_SG_REL_ GW_BDC_FD SG_ 2281701632 UWB_RR_Status8 1500;
BA_REL_ "GenSigTimeoutTime" BU_SG_REL_ L_UWB_BLE_MST_FD SG_ 2281701632 UWB_RR_Status8 1500;
BA_REL_ "GenSigTimeoutTime" BU_SG_REL_ GW_BDC_FD SG_ 2281701632 UWB_RR_Status9 1500;
BA_REL_ "GenSigTimeoutTime" BU_SG_REL_ L_UWB_BLE_MST_FD SG_ 2281701632 UWB_RR_Status9 1500;
BA_REL_ "GenSigTimeoutTime" BU_SG_REL_ GW_BDC_FD SG_ 2281701632 UWB_RR_Status10 1500;
BA_REL_ "GenSigTimeoutTime" BU_SG_REL_ L_UWB_BLE_MST_FD SG_ 2281701632 UWB_RR_Status10 1500;
BA_REL_ "GenSigTimeoutTime" BU_SG_REL_ GW_BDC_FD SG_ 2281701632 UWB_RR_Status11 1500;
BA_REL_ "GenSigTimeoutTime" BU_SG_REL_ L_UWB_BLE_MST_FD SG_ 2281701632 UWB_RR_Status11 1500;
BA_REL_ "GenSigTimeoutTime" BU_SG_REL_ GW_BDC_FD SG_ 2281701632 UWB_RR_Status12 1500;
BA_REL_ "GenSigTimeoutTime" BU_SG_REL_ L_UWB_BLE_MST_FD SG_ 2281701632 UWB_RR_Status12 1500;
BA_REL_ "GenSigTimeoutTime" BU_SG_REL_ GW_BDC_FD SG_ 2281701632 UWB_RR_Status13 1500;
BA_REL_ "GenSigTimeoutTime" BU_SG_REL_ L_UWB_BLE_MST_FD SG_ 2281701632 UWB_RR_Status13 1500;
BA_REL_ "GenSigTimeoutTime" BU_SG_REL_ GW_BDC_FD SG_ 2281701632 UWB_RR_Status14 1500;
BA_REL_ "GenSigTimeoutTime" BU_SG_REL_ L_UWB_BLE_MST_FD SG_ 2281701632 UWB_RR_Status14 1500;
BA_REL_ "GenSigTimeoutTime" BU_SG_REL_ GW_BDC_FD SG_ 2281701632 UWB_RR_Status15 1500;
BA_REL_ "GenSigTimeoutTime" BU_SG_REL_ L_UWB_BLE_MST_FD SG_ 2281701632 UWB_RR_Status15 1500;
BA_REL_ "GenSigTimeoutTime" BU_SG_REL_ GW_BDC_FD SG_ 2281701632 UWB_RR_Status16 1500;
BA_REL_ "GenSigTimeoutTime" BU_SG_REL_ L_UWB_BLE_MST_FD SG_ 2281701632 UWB_RR_Status16 1500;
BA_REL_ "GenSigTimeoutTime" BU_SG_REL_ L_UWB_BLE_MST_FD SG_ 2281701632 UWB_RR_HW_Ver_Major 1500;
BA_REL_ "GenSigTimeoutTime" BU_SG_REL_ L_UWB_BLE_MST_FD SG_ 2281701632 UWB_RR_HW_Ver_Minor 1500;
BA_REL_ "GenSigTimeoutTime" BU_SG_REL_ L_UWB_BLE_MST_FD SG_ 2525342209 FR_SWID_4_IVD_1 0;
BA_REL_ "GenSigTimeoutTime" BU_SG_REL_ L_UWB_BLE_MST_FD SG_ 2281701648 UWB_TRNK_SW_MCU_Ver_Major 1500;
BA_REL_ "GenSigTimeoutTime" BU_SG_REL_ L_UWB_BLE_MST_FD SG_ 2281701648 UWB_TRNK_SW_MCU_Ver_Minor 1500;
BA_REL_ "GenSigTimeoutTime" BU_SG_REL_ L_UWB_BLE_MST_FD SG_ 2281701648 UWB_TRNK_SW_IC_Ver_Major 1500;
BA_REL_ "GenSigTimeoutTime" BU_SG_REL_ L_UWB_BLE_MST_FD SG_ 2281701648 UWB_TRNK_SW_IC_Ver_Minor 1500;
BA_REL_ "GenSigTimeoutTime" BU_SG_REL_ L_UWB_BLE_MST_FD SG_ 2281701648 UWB_TRNK_DTC 1500;
BA_REL_ "GenSigTimeoutTime" BU_SG_REL_ GW_BDC_FD SG_ 2281701648 UWB_TRNK_Status1 1500;
BA_REL_ "GenSigTimeoutTime" BU_SG_REL_ L_UWB_BLE_MST_FD SG_ 2281701648 UWB_TRNK_Status1 1500;
BA_REL_ "GenSigTimeoutTime" BU_SG_REL_ GW_BDC_FD SG_ 2281701648 UWB_TRNK_Status2 1500;
BA_REL_ "GenSigTimeoutTime" BU_SG_REL_ L_UWB_BLE_MST_FD SG_ 2281701648 UWB_TRNK_Status2 1500;
BA_REL_ "GenSigTimeoutTime" BU_SG_REL_ GW_BDC_FD SG_ 2281701648 UWB_TRNK_Status3 1500;
BA_REL_ "GenSigTimeoutTime" BU_SG_REL_ L_UWB_BLE_MST_FD SG_ 2281701648 UWB_TRNK_Status3 1500;
BA_REL_ "GenSigTimeoutTime" BU_SG_REL_ GW_BDC_FD SG_ 2281701648 UWB_TRNK_Status4 1500;
BA_REL_ "GenSigTimeoutTime" BU_SG_REL_ L_UWB_BLE_MST_FD SG_ 2281701648 UWB_TRNK_Status4 1500;
BA_REL_ "GenSigTimeoutTime" BU_SG_REL_ GW_BDC_FD SG_ 2281701648 UWB_TRNK_Status5 1500;
BA_REL_ "GenSigTimeoutTime" BU_SG_REL_ L_UWB_BLE_MST_FD SG_ 2281701648 UWB_TRNK_Status5 1500;
BA_REL_ "GenSigTimeoutTime" BU_SG_REL_ GW_BDC_FD SG_ 2281701648 UWB_TRNK_Status6 1500;
BA_REL_ "GenSigTimeoutTime" BU_SG_REL_ L_UWB_BLE_MST_FD SG_ 2281701648 UWB_TRNK_Status6 1500;
BA_REL_ "GenSigTimeoutTime" BU_SG_REL_ GW_BDC_FD SG_ 2281701648 UWB_TRNK_Status7 1500;
BA_REL_ "GenSigTimeoutTime" BU_SG_REL_ L_UWB_BLE_MST_FD SG_ 2281701648 UWB_TRNK_Status7 1500;
BA_REL_ "GenSigTimeoutTime" BU_SG_REL_ GW_BDC_FD SG_ 2281701648 UWB_TRNK_Status8 1500;
BA_REL_ "GenSigTimeoutTime" BU_SG_REL_ L_UWB_BLE_MST_FD SG_ 2281701648 UWB_TRNK_Status8 1500;
BA_REL_ "GenSigTimeoutTime" BU_SG_REL_ GW_BDC_FD SG_ 2281701648 UWB_TRNK_Status9 1500;
BA_REL_ "GenSigTimeoutTime" BU_SG_REL_ L_UWB_BLE_MST_FD SG_ 2281701648 UWB_TRNK_Status9 1500;
BA_REL_ "GenSigTimeoutTime" BU_SG_REL_ GW_BDC_FD SG_ 2281701648 UWB_TRNK_Status10 1500;
BA_REL_ "GenSigTimeoutTime" BU_SG_REL_ L_UWB_BLE_MST_FD SG_ 2281701648 UWB_TRNK_Status10 1500;
BA_REL_ "GenSigTimeoutTime" BU_SG_REL_ GW_BDC_FD SG_ 2281701648 UWB_TRNK_Status11 1500;
BA_REL_ "GenSigTimeoutTime" BU_SG_REL_ L_UWB_BLE_MST_FD SG_ 2281701648 UWB_TRNK_Status11 1500;
BA_REL_ "GenSigTimeoutTime" BU_SG_REL_ GW_BDC_FD SG_ 2281701648 UWB_TRNK_Status12 1500;
BA_REL_ "GenSigTimeoutTime" BU_SG_REL_ L_UWB_BLE_MST_FD SG_ 2281701648 UWB_TRNK_Status12 1500;
BA_REL_ "GenSigTimeoutTime" BU_SG_REL_ GW_BDC_FD SG_ 2281701648 UWB_TRNK_Status13 1500;
BA_REL_ "GenSigTimeoutTime" BU_SG_REL_ L_UWB_BLE_MST_FD SG_ 2281701648 UWB_TRNK_Status13 1500;
BA_REL_ "GenSigTimeoutTime" BU_SG_REL_ GW_BDC_FD SG_ 2281701648 UWB_TRNK_Status14 1500;
BA_REL_ "GenSigTimeoutTime" BU_SG_REL_ L_UWB_BLE_MST_FD SG_ 2281701648 UWB_TRNK_Status14 1500;
BA_REL_ "GenSigTimeoutTime" BU_SG_REL_ GW_BDC_FD SG_ 2281701648 UWB_TRNK_Status15 1500;
BA_REL_ "GenSigTimeoutTime" BU_SG_REL_ L_UWB_BLE_MST_FD SG_ 2281701648 UWB_TRNK_Status15 1500;
BA_REL_ "GenSigTimeoutTime" BU_SG_REL_ GW_BDC_FD SG_ 2281701648 UWB_TRNK_Status16 1500;
BA_REL_ "GenSigTimeoutTime" BU_SG_REL_ L_UWB_BLE_MST_FD SG_ 2281701648 UWB_TRNK_Status16 1500;
BA_REL_ "GenSigTimeoutTime" BU_SG_REL_ L_UWB_BLE_MST_FD SG_ 2281701648 UWB_TRNK_HW_Ver_Major 1500;
BA_REL_ "GenSigTimeoutTime" BU_SG_REL_ L_UWB_BLE_MST_FD SG_ 2281701648 UWB_TRNK_HW_Ver_Minor 1500;
BA_REL_ "GenSigTimeoutTime" BU_SG_REL_ GW_BDC_FD SG_ 2214592624 WPC_NFCDetection_Sta 0;
BA_REL_ "GenSigTimeoutTime" BU_SG_REL_ GW_BDC_FD SG_ 2214592624 WPC_NFCReset_Sta 0;
BA_REL_ "GenSigTimeoutTime" BU_SG_REL_ GW_BDC_FD SG_ 2214592624 WPC2_NFCDetection_Sta 0;
BA_REL_ "GenSigTimeoutTime" BU_SG_REL_ GW_BDC_FD SG_ 2214592624 WPC2_NFCReset_Sta 0;
BA_REL_ "GenSigTimeoutTime" BU_SG_REL_ GW_BDC_FD SG_ 2281701664 ROA_SW_Ver_Major 1500;
BA_REL_ "GenSigTimeoutTime" BU_SG_REL_ GW_BDC_FD SG_ 2281701664 ROA_SW_Ver_Minor1 1500;
BA_REL_ "GenSigTimeoutTime" BU_SG_REL_ GW_BDC_FD SG_ 2281701664 ROA_SW_Ver_Minor2 1500;
BA_REL_ "GenSigTimeoutTime" BU_SG_REL_ GW_BDC_FD SG_ 2281701664 ROA_ClassStat 1500;
BA_REL_ "GenSigTimeoutTime" BU_SG_REL_ GW_BDC_FD SG_ 2281701664 ROA_SnSrStat 1500;
BA_REL_ "GenSigTimeoutTime" BU_SG_REL_ GW_BDC_FD SG_ 2281701664 ROA_DetInfo 1500;
BA_REL_ "GenSigTimeoutTime" BU_SG_REL_ GW_BDC_FD SG_ 2281701664 ROA_SnSrBlckgeErrStat 1500;
BA_REL_ "GenSigTimeoutTime" BU_SG_REL_ GW_BDC_FD SG_ 2281701664 ROA_SnSrErrStat 1500;
BA_REL_ "GenSigTimeoutTime" BU_SG_REL_ L_ROA_FD SG_ 2281701666 ROA_FR_SW_Ver_Major 1500;
BA_REL_ "GenSigTimeoutTime" BU_SG_REL_ L_ROA_FD SG_ 2281701666 ROA_FR_SW_Ver_Minor1 1500;
BA_REL_ "GenSigTimeoutTime" BU_SG_REL_ L_ROA_FD SG_ 2281701666 ROA_FR_SW_Ver_Minor2 1500;
BA_REL_ "GenSigTimeoutTime" BU_SG_REL_ L_ROA_FD SG_ 2281701666 ROA_FR_ClassStat 1500;
BA_REL_ "GenSigTimeoutTime" BU_SG_REL_ L_ROA_FD SG_ 2281701666 ROA_FR_SnSrStat 1500;
BA_REL_ "GenSigTimeoutTime" BU_SG_REL_ L_ROA_FD SG_ 2281701666 ROA_FR_DetInfo 1500;
BA_REL_ "GenSigTimeoutTime" BU_SG_REL_ L_ROA_FD SG_ 2281701666 ROA_FR_SnSrBlckgeErrStat 1500;
BA_REL_ "GenSigTimeoutTime" BU_SG_REL_ L_ROA_FD SG_ 2281701666 ROA_FR_SnSrErrStat 1500;
BA_REL_ "GenSigTimeoutTime" BU_SG_REL_ L_ROA_FD SG_ 2214592608 BDCROADataByte0 0;
BA_REL_ "GenSigTimeoutTime" BU_SG_REL_ L_ROA_FR_FD SG_ 2214592608 BDCROADataByte0 0;
BA_REL_ "GenSigTimeoutTime" BU_SG_REL_ L_ROA_FD SG_ 2214592608 BDCROADataByte1 0;
BA_REL_ "GenSigTimeoutTime" BU_SG_REL_ L_ROA_FR_FD SG_ 2214592608 BDCROADataByte1 0;
BA_REL_ "GenSigTimeoutTime" BU_SG_REL_ L_ROA_FD SG_ 2214592608 BDCROADataByte2 0;
BA_REL_ "GenSigTimeoutTime" BU_SG_REL_ L_ROA_FR_FD SG_ 2214592608 BDCROADataByte2 0;
BA_REL_ "GenSigTimeoutTime" BU_SG_REL_ L_ROA_FD SG_ 2214592608 BDCROADataByte3 0;
BA_REL_ "GenSigTimeoutTime" BU_SG_REL_ L_ROA_FR_FD SG_ 2214592608 BDCROADataByte3 0;
BA_REL_ "GenSigTimeoutTime" BU_SG_REL_ L_ROA_FD SG_ 2214592608 BDCROADataByte4 0;
BA_REL_ "GenSigTimeoutTime" BU_SG_REL_ L_ROA_FR_FD SG_ 2214592608 BDCROADataByte4 0;
BA_REL_ "GenSigTimeoutTime" BU_SG_REL_ L_ROA_FD SG_ 2214592608 BDCROADataByte5 0;
BA_REL_ "GenSigTimeoutTime" BU_SG_REL_ L_ROA_FR_FD SG_ 2214592608 BDCROADataByte5 0;
BA_REL_ "GenSigTimeoutTime" BU_SG_REL_ L_ROA_FD SG_ 2214592608 BDCROADataByte6 0;
BA_REL_ "GenSigTimeoutTime" BU_SG_REL_ L_ROA_FR_FD SG_ 2214592608 BDCROADataByte6 0;
BA_REL_ "GenSigTimeoutTime" BU_SG_REL_ L_ROA_FD SG_ 2214592608 BDCROADataByte7 0;
BA_REL_ "GenSigTimeoutTime" BU_SG_REL_ L_ROA_FR_FD SG_ 2214592608 BDCROADataByte7 0;
BA_REL_ "GenSigTimeoutTime" BU_SG_REL_ L_UWB_BLE_MST_FD SG_ 2525341697 FR_SWID_3_IVD_1 0;
BA_REL_ "GenSigTimeoutTime" BU_SG_REL_ GW_BDC_FD SG_ 2281701680 SAL_BttmBrightnessDutyRatio 1500;
BA_REL_ "GenSigTimeoutTime" BU_SG_REL_ GW_BDC_FD SG_ 2281701680 SAL_BttmFadeInTime 1500;
BA_REL_ "GenSigTimeoutTime" BU_SG_REL_ GW_BDC_FD SG_ 2281701680 SAL_BttmFadeOutTimeValue 1500;
BA_REL_ "GenSigTimeoutTime" BU_SG_REL_ GW_BDC_FD SG_ 2281701680 SAL_MLNShiftModOptionState 1500;
BA_REL_ "GenSigTimeoutTime" BU_SG_REL_ GW_BDC_FD SG_ 2281701680 SAL_MLSALApplyState 1500;
BA_REL_ "GenSigTimeoutTime" BU_SG_REL_ GW_BDC_FD SG_ 2281701680 SAL_MLAIVoiceOptionState 1500;
BA_REL_ "GenSigTimeoutTime" BU_SG_REL_ GW_BDC_FD SG_ 2281701680 SAL_MLTherapyOptionState 1500;
BA_REL_ "GenSigTimeoutTime" BU_SG_REL_ GW_BDC_FD SG_ 2281701680 SAL_MLDualColorOptionState 1500;
BA_REL_ "GenSigTimeoutTime" BU_SG_REL_ GW_BDC_FD SG_ 2281701680 SAL_MLNumRecommendColor 1500;
BA_REL_ "GenSigTimeoutTime" BU_SG_REL_ GW_BDC_FD SG_ 2281701680 SAL_UPRColorXValue 1500;
BA_REL_ "GenSigTimeoutTime" BU_SG_REL_ GW_BDC_FD SG_ 2281701680 SAL_UPRColorYValue 1500;
BA_REL_ "GenSigTimeoutTime" BU_SG_REL_ GW_BDC_FD SG_ 2281701680 SAL_BrightnessDutyRatio 1500;
BA_REL_ "GenSigTimeoutTime" BU_SG_REL_ GW_BDC_FD SG_ 2281701680 SAL_FadeInTime 1500;
BA_REL_ "GenSigTimeoutTime" BU_SG_REL_ GW_BDC_FD SG_ 2281701680 SAL_FadeOutTimeValue 1500;
BA_REL_ "GenSigTimeoutTime" BU_SG_REL_ GW_BDC_FD SG_ 2281701680 SAL_MLEarlyEveningOptionState 1500;
BA_REL_ "GenSigTimeoutTime" BU_SG_REL_ GW_BDC_FD SG_ 2281701680 SAL_MLTempChgOptionState 1500;
BA_REL_ "GenSigTimeoutTime" BU_SG_REL_ GW_BDC_FD SG_ 2281701680 SAL_MLPhoneCallModOptionState 1500;
BA_REL_ "GenSigTimeoutTime" BU_SG_REL_ GW_BDC_FD SG_ 2281701680 SAL_MLDoorWarnOptionState 1500;
BA_REL_ "GenSigTimeoutTime" BU_SG_REL_ GW_BDC_FD SG_ 2281701680 SAL_MLHazardModOptionState 1500;
BA_REL_ "GenSigTimeoutTime" BU_SG_REL_ GW_BDC_FD SG_ 2281701680 SAL_MLLowFuelModOptionState 1500;
BA_REL_ "GenSigTimeoutTime" BU_SG_REL_ GW_BDC_FD SG_ 2281701680 SAL_BttmColorXValue 1500;
BA_REL_ "GenSigTimeoutTime" BU_SG_REL_ GW_BDC_FD SG_ 2281701680 SAL_BttmColorYValue 1500;
BA_REL_ "GenSigTimeoutTime" BU_SG_REL_ L_UWB_BLE_MST_FD SG_ 1025 SSB_StrtStpBtnSw1Sta_Copy_0 1500;
BA_REL_ "GenSigTimeoutTime" BU_SG_REL_ L_UWB_BLE_MST_FD SG_ 1025 SSB_StrtStpBtnSw2Sta_Copy_0 1500;
BA_REL_ "GenSigTimeoutTime" BU_SG_REL_ L_UWB_BLE_MST_FD SG_ 2529540353 RR_SWID_3_IVD_2 0;
BA_REL_ "GenSigTimeoutTime" BU_SG_REL_ L_UWB_BLE_MST_FD SG_ 2521142529 SLV_SWID_2_IVD_1 0;
BA_REL_ "GenSigTimeoutTime" BU_SG_REL_ L_UWB_BLE_MST_FD SG_ 2533738753 FRNK_SWID_3_IVD_2 0;
BA_REL_ "GenSigTimeoutTime" BU_SG_REL_ L_UWB_BLE_MST_FD SG_ 2529540865 RR_SWID_4_IVD_2 0;
BA_REL_ "GenSigTimeoutTime" BU_SG_REL_ L_UWB_BLE_MST_FD SG_ 2521143041 SLV_SWID_3_IVD_1 0;
BA_REL_ "GenSigTimeoutTime" BU_SG_REL_ L_UWB_BLE_MST_FD SG_ 2533739265 FRNK_SWID_4_IVD_2 0;
BA_REL_ "GenSigTimeoutTime" BU_SG_REL_ L_UWB_BLE_MST_FD SG_ 2214593024 EDT_BLE_Dvp_Data 0;
BA_REL_ "GenSigTimeoutTime" BU_SG_REL_ L_UWB_BLE_SLV_FD SG_ 2214593024 EDT_BLE_Dvp_Data 0;
BA_REL_ "GenSigTimeoutTime" BU_SG_REL_ L_UWB_FL_FD SG_ 2214593024 EDT_BLE_Dvp_Data 0;
BA_REL_ "GenSigTimeoutTime" BU_SG_REL_ L_UWB_FRNK_FD SG_ 2214593024 EDT_BLE_Dvp_Data 0;
BA_REL_ "GenSigTimeoutTime" BU_SG_REL_ L_UWB_FR_FD SG_ 2214593024 EDT_BLE_Dvp_Data 0;
BA_REL_ "GenSigTimeoutTime" BU_SG_REL_ L_UWB_RL_FD SG_ 2214593024 EDT_BLE_Dvp_Data 0;
BA_REL_ "GenSigTimeoutTime" BU_SG_REL_ L_UWB_RR_FD SG_ 2214593024 EDT_BLE_Dvp_Data 0;
BA_REL_ "GenSigTimeoutTime" BU_SG_REL_ L_UWB_TRNK_FD SG_ 2214593024 EDT_BLE_Dvp_Data 0;
BA_REL_ "GenSigTimeoutTime" BU_SG_REL_ L_UWB_BLE_MST_FD SG_ 2214593025 EDT_DH_Dvp_Data 0;
BA_REL_ "GenSigTimeoutTime" BU_SG_REL_ L_UWB_BLE_SLV_FD SG_ 2214593025 EDT_DH_Dvp_Data 0;
BA_REL_ "GenSigTimeoutTime" BU_SG_REL_ L_UWB_BLE_MST_FD SG_ 2214593026 EDT_UWB_Dvp_Data 0;
BA_REL_ "GenSigTimeoutTime" BU_SG_REL_ L_UWB_BLE_SLV_FD SG_ 2214593026 EDT_UWB_Dvp_Data 0;
BA_REL_ "GenSigTimeoutTime" BU_SG_REL_ L_UWB_FL_FD SG_ 2214593026 EDT_UWB_Dvp_Data 0;
BA_REL_ "GenSigTimeoutTime" BU_SG_REL_ L_UWB_FRNK_FD SG_ 2214593026 EDT_UWB_Dvp_Data 0;
BA_REL_ "GenSigTimeoutTime" BU_SG_REL_ L_UWB_FR_FD SG_ 2214593026 EDT_UWB_Dvp_Data 0;
BA_REL_ "GenSigTimeoutTime" BU_SG_REL_ L_UWB_RL_FD SG_ 2214593026 EDT_UWB_Dvp_Data 0;
BA_REL_ "GenSigTimeoutTime" BU_SG_REL_ L_UWB_RR_FD SG_ 2214593026 EDT_UWB_Dvp_Data 0;
BA_REL_ "GenSigTimeoutTime" BU_SG_REL_ L_UWB_TRNK_FD SG_ 2214593026 EDT_UWB_Dvp_Data 0;
BA_REL_ "GenSigTimeoutTime" BU_SG_REL_ L_DHL_FD SG_ 1087 CCU_ForcedPowerOffReq 0;
BA_REL_ "GenSigTimeoutTime" BU_SG_REL_ L_DHRL_FD SG_ 1087 CCU_ForcedPowerOffReq 0;
BA_REL_ "GenSigTimeoutTime" BU_SG_REL_ L_DHRR_FD SG_ 1087 CCU_ForcedPowerOffReq 0;
BA_REL_ "GenSigTimeoutTime" BU_SG_REL_ L_DHR_FD SG_ 1087 CCU_ForcedPowerOffReq 0;
BA_REL_ "GenSigTimeoutTime" BU_SG_REL_ L_ROA_FD SG_ 1087 CCU_ForcedPowerOffReq 0;
BA_REL_ "GenSigTimeoutTime" BU_SG_REL_ L_ROA_FR_FD SG_ 1087 CCU_ForcedPowerOffReq 0;
BA_REL_ "GenSigTimeoutTime" BU_SG_REL_ L_SAL_FD SG_ 1087 CCU_ForcedPowerOffReq 0;
BA_REL_ "GenSigTimeoutTime" BU_SG_REL_ L_TPMS_FD SG_ 1087 CCU_ForcedPowerOffReq 0;
BA_REL_ "GenSigTimeoutTime" BU_SG_REL_ L_UWB_BLE_MST_FD SG_ 1087 CCU_ForcedPowerOffReq 0;
BA_REL_ "GenSigTimeoutTime" BU_SG_REL_ L_UWB_BLE_SLV_FD SG_ 1087 CCU_ForcedPowerOffReq 0;
BA_REL_ "GenSigTimeoutTime" BU_SG_REL_ L_UWB_FL_FD SG_ 1087 CCU_ForcedPowerOffReq 0;
BA_REL_ "GenSigTimeoutTime" BU_SG_REL_ L_UWB_FRNK_FD SG_ 1087 CCU_ForcedPowerOffReq 0;
BA_REL_ "GenSigTimeoutTime" BU_SG_REL_ L_UWB_FR_FD SG_ 1087 CCU_ForcedPowerOffReq 0;
BA_REL_ "GenSigTimeoutTime" BU_SG_REL_ L_UWB_RL_FD SG_ 1087 CCU_ForcedPowerOffReq 0;
BA_REL_ "GenSigTimeoutTime" BU_SG_REL_ L_UWB_RR_FD SG_ 1087 CCU_ForcedPowerOffReq 0;
BA_REL_ "GenSigTimeoutTime" BU_SG_REL_ L_UWB_TRNK_FD SG_ 1087 CCU_ForcedPowerOffReq 0;
BA_REL_ "GenSigTimeoutTime" BU_SG_REL_ L_WPC_FD SG_ 1087 CCU_ForcedPowerOffReq 0;
BA_REL_ "GenSigTimeoutTime" BU_SG_REL_ L_EDT_FD SG_ 2214592730 SLV_DisconnectDKID 0;
BA_REL_ "GenSigTimeoutTime" BU_SG_REL_ L_EDT_FD SG_ 2214592730 SLV_DisconnectReason 0;
BA_REL_ "GenSigTimeoutTime" BU_SG_REL_ L_EDT_FD SG_ 2214592730 SLV_BLE_ErrorReturn 0;
BA_REL_ "GenSigTimeoutTime" BU_SG_REL_ L_UWB_BLE_MST_FD SG_ 2214592730 SLV_BLE_ErrorReturn 0;
BA_REL_ "GenSigTimeoutTime" BU_SG_REL_ L_UWB_BLE_MST_FD SG_ 2525340161 FL_SWID_4_IVD_1 0;
BA_REL_ "GenSigTimeoutTime" BU_SG_REL_ L_EDT_FD SG_ 2214592735 UWB_FR_Dvp_Data 0;
BA_REL_ "GenSigTimeoutTime" BU_SG_REL_ GW_BDC_FD SG_ 2214592720 UWB_FR_UWB_Decrypt_FB 0;
BA_REL_ "GenSigTimeoutTime" BU_SG_REL_ L_UWB_BLE_MST_FD SG_ 2214592720 UWB_FR_MST_Decrypt_FB 0;
BA_REL_ "GenSigTimeoutTime" BU_SG_REL_ L_UWB_BLE_MST_FD SG_ 2214592720 UWB_FR_OTA_Rsp 0;
BA_REL_ "GenSigTimeoutTime" BU_SG_REL_ L_EDT_FD SG_ 2214592720 UWB_FR_UWB_IC_Status 0;
BA_REL_ "GenSigTimeoutTime" BU_SG_REL_ GW_BDC_FD SG_ 2214592721 UWB_FR_FOB_RSD_Enc_Result 0;
VAL_ 2214592593 L_BDC_FD_IAU_Crc2Val 0 "0x0x0~0xFFFF:CRCValue" 65535 "0x0x0~0xFFFF:CRCValue" ;
VAL_ 2214592593 DKID_Del 0 "Default" 1 "DK#1" 2 "DK#2" 3 "DK#3" 4 "DK#4" 5 "DK#5" 6 "DK#6" 7 "DK#7" 8 "DK#8" 9 "DK#9" 10 "DK#10" 11 "DK#11" 12 "DK#12" 13 "DK#13" 14 "DK#14" 15 "DK#15" 16 "DK#16" 17 "DK#NEW" 18 "DK#ALL" 19 "0x13~0xFE:RESERVED" 254 "0x13~0xFE:RESERVED" 255 "Invalid" ;
VAL_ 2214592593 UWB_Ranging_Cmd_DKID 0 "Default" 1 "DK#1" 2 "DK#2" 3 "DK#3" 4 "DK#4" 5 "DK#5" 6 "DK#6" 7 "DK#7" 8 "DK#8" 9 "DK#9" 10 "DK#10" 11 "DK#11" 12 "DK#12" 13 "DK#13" 14 "DK#14" 15 "DK#15" 16 "DK#16" 17 "DK#NEW" 18 "DK#ALL" 19 "0x13~0xFE:RESERVED" 254 "0x13~0xFE:RESERVED" 255 "Invalid" ;
VAL_ 2214592593 UWB_Ranging_Cmd_Val 0 "Default" 1 "Suspend" 2 "Termination(Stop)" 3 "0x03~0xFF:RESERVED" 255 "0x03~0xFF:RESERVED" ;
VAL_ 2214592593 L_BDC_FD_IAU_AlvCnt2Val 0 "0x0x0~0xFF:AlvCntValue" 255 "0x0x0~0xFF:AlvCntValue" ;
VAL_ 2214592593 BDC_RndNum_Trgt 0 "Default" 1 "BLE" 2 "UWB" 3 "ALL" 4 "RESERVED" 5 "RESERVED" 6 "RESERVED" 7 "RESERVED" 8 "RESERVED" 9 "RESERVED" 10 "RESERVED" 11 "RESERVED" 12 "RESERVED" 13 "RESERVED" 14 "RESERVED" 15 "Invalid" ;
VAL_ 2214592593 BDC_RndNum_TRCod 0 "Default" 1 "Request for encryptedData" 2 "Request for Receive" 3 "Request for ncryptedCMDResult" 4 "RESERVED" 5 "RESERVED" 6 "RESERVED" 7 "RESERVED" 8 "RESERVED" 9 "RESERVED" 10 "RESERVED" 11 "RESERVED" 12 "RESERVED" 13 "RESERVED" 14 "RESERVED" 15 "Invalid" ;
VAL_ 2214592593 BDC_RndNum_Cmd 0 "Default" 1 "BTAdd_IRK" 2 "Kble Intro_Kble OOB Master" 3 "URSK_Session ID" 4 "Ranging Session Setup" 5 "Ranging Recovery" 6 "Configurable Ranging Recovery" 7 "UFKC_RAD Ranging" 8 "Rad Disable Auth" 9 "RESERVED" 10 "RESERVED" 11 "RESERVED" 12 "RESERVED" 13 "RESERVED" 14 "RESERVED" 15 "Invalid" ;
VAL_ 2214592593 BDC_Decrypt_FB 0 "Default" 1 "Positive" 2 "Negative" 3 "Invalid" ;
VAL_ 2214592593 DKID_Set 0 "Default" 1 "DK#1" 2 "DK#2" 3 "DK#3" 4 "DK#4" 5 "DK#5" 6 "DK#6" 7 "DK#7" 8 "DK#8" 9 "DK#9" 10 "DK#10" 11 "DK#11" 12 "DK#12" 13 "DK#13" 14 "DK#14" 15 "DK#15" 16 "DK#16" 17 "DK#NEW" 18 "0x12~0xFE:RESERVED" 254 "0x12~0xFE:RESERVED" 255 "Invalid" ;
VAL_ 2214592592 L_BDC_FD_IAU_Crc1Val 0 "0x0x0~0xFFFF:CRCValue" 65535 "0x0x0~0xFFFF:CRCValue" ;
VAL_ 2214592592 L_BDC_FD_IAU_AlvCnt1Val 0 "0x0x0~0xFF:AlvCntValue" 255 "0x0x0~0xFF:AlvCntValue" ;
VAL_ 2214592592 WPC_NFC_Deselect_Cmd 0 "Default" 1 "WPC NFC Polling (Search)" 2 "WPC NFC Deselect (Stop)" 3 "Invalid" ;
VAL_ 2214592592 WPC2_NFC_Deselect_Cmd 0 "Default" 1 "WPC2 NFC Polling (Search)" 2 "WPC2 NFC Deselect (Stop)" 3 "Invalid" ;
VAL_ 2214592592 DHL_NFC_Deselect_Cmd 0 "Default" 1 "NFC Polling (Search)" 2 "NFC Deselect (Stop)" 3 "Invalid" ;
VAL_ 2214592592 DHR_NFC_Deselect_Cmd 0 "Default" 1 "NFC Polling (Search)" 2 "NFC Deselect (Stop)" 3 "Invalid" ;
VAL_ 2214592592 DHRL_NFC_Deselect_Cmd 0 "Default" 1 "NFC Polling (Search)" 2 "NFC Deselect (Stop)" 3 "Invalid" ;
VAL_ 2214592592 DHRR_NFC_Deselect_Cmd 0 "Default" 1 "NFC Polling (Search)" 2 "NFC Deselect (Stop)" 3 "Invalid" ;
VAL_ 2214592595 L_BDC_FD_IAU_Crc4Val 0 "0x0x0~0xFFFF:CRCValue" 65535 "0x0x0~0xFFFF:CRCValue" ;
VAL_ 2214592595 L_BDC_FD_IAU_AlvCnt4Val 0 "0x0x0~0xFF:AlvCntValue" 255 "0x0x0~0xFF:AlvCntValue" ;
VAL_ 2214592594 L_BDC_FD_IAU_Crc3Val 0 "0x0x0~0xFFFF:CRCValue" 65535 "0x0x0~0xFFFF:CRCValue" ;
VAL_ 2214592594 L_BDC_FD_IAU_AlvCnt3Val 0 "0x0x0~0xFF:AlvCntValue" 255 "0x0x0~0xFF:AlvCntValue" ;
VAL_ 2214592597 L_BDC_FD_IAU_Crc6Val 0 "0x0x0~0xFFFF:CRCValue" 65535 "0x0x0~0xFFFF:CRCValue" ;
VAL_ 2214592597 L_BDC_FD_IAU_AlvCnt6Val 0 "0x0x0~0xFF:AlvCntValue" 255 "0x0x0~0xFF:AlvCntValue" ;
VAL_ 2214592596 L_BDC_FD_IAU_Crc5Val 0 "0x0x0~0xFFFF:CRCValue" 65535 "0x0x0~0xFFFF:CRCValue" ;
VAL_ 2214592596 L_BDC_FD_IAU_AlvCnt5Val 0 "0x0x0~0xFF:AlvCntValue" 255 "0x0x0~0xFF:AlvCntValue" ;
VAL_ 2214592598 L_BDC_FD_IAU_Crc7Val 0 "0x0x0~0xFFFF:CRCValue" 65535 "0x0x0~0xFFFF:CRCValue" ;
VAL_ 2214592598 L_BDC_FD_IAU_AlvCnt7Val 0 "0x0x0~0xFF:AlvCntValue" 255 "0x0x0~0xFF:AlvCntValue" ;
VAL_ 2281701632 L_UWB_RR_FD_Crc10Val 0 "0x0x0~0xFFFF:CRCValue" 65535 "0x0x0~0xFFFF:CRCValue" ;
VAL_ 2281701632 L_UWB_RR_FD_AlvCnt10Val 0 "0x0x0~0xFF:AlvCntValue" 255 "0x0x0~0xFF:AlvCntValue" ;
VAL_ 2281701632 UWB_RR_Status1 0 "Default" 1 "No_Ranging" 2 "URSK_Stored" 3 "UWB_Session_Setup" 4 "Ranging_Start(Not_In_Sync)" 5 "Ranging_Start(In_Sync)" 6 "Ranging_Stop(Max_Signal_Missed)" 7 "Fob_Ranging" 8 "RESERVED" 9 "RESERVED" 10 "RESERVED" 11 "RESERVED" 12 "RESERVED" 13 "RESERVED" 14 "RESERVED" 15 "Invalid" ;
VAL_ 2281701632 UWB_RR_Status2 0 "Default" 1 "No_Ranging" 2 "URSK_Stored" 3 "UWB_Session_Setup" 4 "Ranging_Start(Not_In_Sync)" 5 "Ranging_Start(In_Sync)" 6 "Ranging_Stop(Max_Signal_Missed)" 7 "Fob_Ranging" 8 "RESERVED" 9 "RESERVED" 10 "RESERVED" 11 "RESERVED" 12 "RESERVED" 13 "RESERVED" 14 "RESERVED" 15 "Invalid" ;
VAL_ 2281701632 UWB_RR_Status3 0 "Default" 1 "No_Ranging" 2 "URSK_Stored" 3 "UWB_Session_Setup" 4 "Ranging_Start(Not_In_Sync)" 5 "Ranging_Start(In_Sync)" 6 "Ranging_Stop(Max_Signal_Missed)" 7 "Fob_Ranging" 8 "RESERVED" 9 "RESERVED" 10 "RESERVED" 11 "RESERVED" 12 "RESERVED" 13 "RESERVED" 14 "RESERVED" 15 "Invalid" ;
VAL_ 2281701632 UWB_RR_Status4 0 "Default" 1 "No_Ranging" 2 "URSK_Stored" 3 "UWB_Session_Setup" 4 "Ranging_Start(Not_In_Sync)" 5 "Ranging_Start(In_Sync)" 6 "Ranging_Stop(Max_Signal_Missed)" 7 "Fob_Ranging" 8 "RESERVED" 9 "RESERVED" 10 "RESERVED" 11 "RESERVED" 12 "RESERVED" 13 "RESERVED" 14 "RESERVED" 15 "Invalid" ;
VAL_ 2281701632 UWB_RR_Status5 0 "Default" 1 "No_Ranging" 2 "URSK_Stored" 3 "UWB_Session_Setup" 4 "Ranging_Start(Not_In_Sync)" 5 "Ranging_Start(In_Sync)" 6 "Ranging_Stop(Max_Signal_Missed)" 7 "Fob_Ranging" 8 "RESERVED" 9 "RESERVED" 10 "RESERVED" 11 "RESERVED" 12 "RESERVED" 13 "RESERVED" 14 "RESERVED" 15 "Invalid" ;
VAL_ 2281701632 UWB_RR_Status6 0 "Default" 1 "No_Ranging" 2 "URSK_Stored" 3 "UWB_Session_Setup" 4 "Ranging_Start(Not_In_Sync)" 5 "Ranging_Start(In_Sync)" 6 "Ranging_Stop(Max_Signal_Missed)" 7 "Fob_Ranging" 8 "RESERVED" 9 "RESERVED" 10 "RESERVED" 11 "RESERVED" 12 "RESERVED" 13 "RESERVED" 14 "RESERVED" 15 "Invalid" ;
VAL_ 2281701632 UWB_RR_Status7 0 "Default" 1 "No_Ranging" 2 "URSK_Stored" 3 "UWB_Session_Setup" 4 "Ranging_Start(Not_In_Sync)" 5 "Ranging_Start(In_Sync)" 6 "Ranging_Stop(Max_Signal_Missed)" 7 "Fob_Ranging" 8 "RESERVED" 9 "RESERVED" 10 "RESERVED" 11 "RESERVED" 12 "RESERVED" 13 "RESERVED" 14 "RESERVED" 15 "Invalid" ;
VAL_ 2281701632 UWB_RR_Status8 0 "Default" 1 "No_Ranging" 2 "URSK_Stored" 3 "UWB_Session_Setup" 4 "Ranging_Start(Not_In_Sync)" 5 "Ranging_Start(In_Sync)" 6 "Ranging_Stop(Max_Signal_Missed)" 7 "Fob_Ranging" 8 "RESERVED" 9 "RESERVED" 10 "RESERVED" 11 "RESERVED" 12 "RESERVED" 13 "RESERVED" 14 "RESERVED" 15 "Invalid" ;
VAL_ 2281701632 UWB_RR_Status9 0 "Default" 1 "No_Ranging" 2 "URSK_Stored" 3 "UWB_Session_Setup" 4 "Ranging_Start(Not_In_Sync)" 5 "Ranging_Start(In_Sync)" 6 "Ranging_Stop(Max_Signal_Missed)" 7 "Fob_Ranging" 8 "RESERVED" 9 "RESERVED" 10 "RESERVED" 11 "RESERVED" 12 "RESERVED" 13 "RESERVED" 14 "RESERVED" 15 "Invalid" ;
VAL_ 2281701632 UWB_RR_Status10 0 "Default" 1 "No_Ranging" 2 "URSK_Stored" 3 "UWB_Session_Setup" 4 "Ranging_Start(Not_In_Sync)" 5 "Ranging_Start(In_Sync)" 6 "Ranging_Stop(Max_Signal_Missed)" 7 "Fob_Ranging" 8 "RESERVED" 9 "RESERVED" 10 "RESERVED" 11 "RESERVED" 12 "RESERVED" 13 "RESERVED" 14 "RESERVED" 15 "Invalid" ;
VAL_ 2281701632 UWB_RR_Status11 0 "Default" 1 "No_Ranging" 2 "URSK_Stored" 3 "UWB_Session_Setup" 4 "Ranging_Start(Not_In_Sync)" 5 "Ranging_Start(In_Sync)" 6 "Ranging_Stop(Max_Signal_Missed)" 7 "Fob_Ranging" 8 "RESERVED" 9 "RESERVED" 10 "RESERVED" 11 "RESERVED" 12 "RESERVED" 13 "RESERVED" 14 "RESERVED" 15 "Invalid" ;
VAL_ 2281701632 UWB_RR_Status12 0 "Default" 1 "No_Ranging" 2 "URSK_Stored" 3 "UWB_Session_Setup" 4 "Ranging_Start(Not_In_Sync)" 5 "Ranging_Start(In_Sync)" 6 "Ranging_Stop(Max_Signal_Missed)" 7 "Fob_Ranging" 8 "RESERVED" 9 "RESERVED" 10 "RESERVED" 11 "RESERVED" 12 "RESERVED" 13 "RESERVED" 14 "RESERVED" 15 "Invalid" ;
VAL_ 2281701632 UWB_RR_Status13 0 "Default" 1 "No_Ranging" 2 "URSK_Stored" 3 "UWB_Session_Setup" 4 "Ranging_Start(Not_In_Sync)" 5 "Ranging_Start(In_Sync)" 6 "Ranging_Stop(Max_Signal_Missed)" 7 "Fob_Ranging" 8 "RESERVED" 9 "RESERVED" 10 "RESERVED" 11 "RESERVED" 12 "RESERVED" 13 "RESERVED" 14 "RESERVED" 15 "Invalid" ;
VAL_ 2281701632 UWB_RR_Status14 0 "Default" 1 "No_Ranging" 2 "URSK_Stored" 3 "UWB_Session_Setup" 4 "Ranging_Start(Not_In_Sync)" 5 "Ranging_Start(In_Sync)" 6 "Ranging_Stop(Max_Signal_Missed)" 7 "Fob_Ranging" 8 "RESERVED" 9 "RESERVED" 10 "RESERVED" 11 "RESERVED" 12 "RESERVED" 13 "RESERVED" 14 "RESERVED" 15 "Invalid" ;
VAL_ 2281701632 UWB_RR_Status15 0 "Default" 1 "No_Ranging" 2 "URSK_Stored" 3 "UWB_Session_Setup" 4 "Ranging_Start(Not_In_Sync)" 5 "Ranging_Start(In_Sync)" 6 "Ranging_Stop(Max_Signal_Missed)" 7 "Fob_Ranging" 8 "RESERVED" 9 "RESERVED" 10 "RESERVED" 11 "RESERVED" 12 "RESERVED" 13 "RESERVED" 14 "RESERVED" 15 "Invalid" ;
VAL_ 2281701632 UWB_RR_Status16 0 "Default" 1 "No_Ranging" 2 "URSK_Stored" 3 "UWB_Session_Setup" 4 "Ranging_Start(Not_In_Sync)" 5 "Ranging_Start(In_Sync)" 6 "Ranging_Stop(Max_Signal_Missed)" 7 "Fob_Ranging" 8 "RESERVED" 9 "RESERVED" 10 "RESERVED" 11 "RESERVED" 12 "RESERVED" 13 "RESERVED" 14 "RESERVED" 15 "Invalid" ;
VAL_ 2525342209 L_UWB_FR_FD_Crc6Val 0 "0x0x0~0xFFFF:CRCValue" 65535 "0x0x0~0xFFFF:CRCValue" ;
VAL_ 2525342209 L_UWB_FR_FD_AlvCnt6Val 0 "0x0x0~0xFF:AlvCntValue" 255 "0x0x0~0xFF:AlvCntValue" ;
VAL_ 2281701648 L_UWB_TRNK_FD_Crc10Val 0 "0x0x0~0xFFFF:CRCValue" 65535 "0x0x0~0xFFFF:CRCValue" ;
VAL_ 2281701648 L_UWB_TRNK_FD_AlvCnt10Val 0 "0x0x0~0xFF:AlvCntValue" 255 "0x0x0~0xFF:AlvCntValue" ;
VAL_ 2281701648 UWB_TRNK_Status1 0 "Default" 1 "No_Ranging" 2 "URSK_Stored" 3 "UWB_Session_Setup" 4 "Ranging_Start(Not_In_Sync)" 5 "Ranging_Start(In_Sync)" 6 "Ranging_Stop(Max_Signal_Missed)" 7 "Fob_Ranging" 8 "RESERVED" 9 "RESERVED" 10 "RESERVED" 11 "RESERVED" 12 "RESERVED" 13 "RESERVED" 14 "RESERVED" 15 "Invalid" ;
VAL_ 2281701648 UWB_TRNK_Status2 0 "Default" 1 "No_Ranging" 2 "URSK_Stored" 3 "UWB_Session_Setup" 4 "Ranging_Start(Not_In_Sync)" 5 "Ranging_Start(In_Sync)" 6 "Ranging_Stop(Max_Signal_Missed)" 7 "Fob_Ranging" 8 "RESERVED" 9 "RESERVED" 10 "RESERVED" 11 "RESERVED" 12 "RESERVED" 13 "RESERVED" 14 "RESERVED" 15 "Invalid" ;
VAL_ 2281701648 UWB_TRNK_Status3 0 "Default" 1 "No_Ranging" 2 "URSK_Stored" 3 "UWB_Session_Setup" 4 "Ranging_Start(Not_In_Sync)" 5 "Ranging_Start(In_Sync)" 6 "Ranging_Stop(Max_Signal_Missed)" 7 "Fob_Ranging" 8 "RESERVED" 9 "RESERVED" 10 "RESERVED" 11 "RESERVED" 12 "RESERVED" 13 "RESERVED" 14 "RESERVED" 15 "Invalid" ;
VAL_ 2281701648 UWB_TRNK_Status4 0 "Default" 1 "No_Ranging" 2 "URSK_Stored" 3 "UWB_Session_Setup" 4 "Ranging_Start(Not_In_Sync)" 5 "Ranging_Start(In_Sync)" 6 "Ranging_Stop(Max_Signal_Missed)" 7 "Fob_Ranging" 8 "RESERVED" 9 "RESERVED" 10 "RESERVED" 11 "RESERVED" 12 "RESERVED" 13 "RESERVED" 14 "RESERVED" 15 "Invalid" ;
VAL_ 2281701648 UWB_TRNK_Status5 0 "Default" 1 "No_Ranging" 2 "URSK_Stored" 3 "UWB_Session_Setup" 4 "Ranging_Start(Not_In_Sync)" 5 "Ranging_Start(In_Sync)" 6 "Ranging_Stop(Max_Signal_Missed)" 7 "Fob_Ranging" 8 "RESERVED" 9 "RESERVED" 10 "RESERVED" 11 "RESERVED" 12 "RESERVED" 13 "RESERVED" 14 "RESERVED" 15 "Invalid" ;
VAL_ 2281701648 UWB_TRNK_Status6 0 "Default" 1 "No_Ranging" 2 "URSK_Stored" 3 "UWB_Session_Setup" 4 "Ranging_Start(Not_In_Sync)" 5 "Ranging_Start(In_Sync)" 6 "Ranging_Stop(Max_Signal_Missed)" 7 "Fob_Ranging" 8 "RESERVED" 9 "RESERVED" 10 "RESERVED" 11 "RESERVED" 12 "RESERVED" 13 "RESERVED" 14 "RESERVED" 15 "Invalid" ;
VAL_ 2281701648 UWB_TRNK_Status7 0 "Default" 1 "No_Ranging" 2 "URSK_Stored" 3 "UWB_Session_Setup" 4 "Ranging_Start(Not_In_Sync)" 5 "Ranging_Start(In_Sync)" 6 "Ranging_Stop(Max_Signal_Missed)" 7 "Fob_Ranging" 8 "RESERVED" 9 "RESERVED" 10 "RESERVED" 11 "RESERVED" 12 "RESERVED" 13 "RESERVED" 14 "RESERVED" 15 "Invalid" ;
VAL_ 2281701648 UWB_TRNK_Status8 0 "Default" 1 "No_Ranging" 2 "URSK_Stored" 3 "UWB_Session_Setup" 4 "Ranging_Start(Not_In_Sync)" 5 "Ranging_Start(In_Sync)" 6 "Ranging_Stop(Max_Signal_Missed)" 7 "Fob_Ranging" 8 "RESERVED" 9 "RESERVED" 10 "RESERVED" 11 "RESERVED" 12 "RESERVED" 13 "RESERVED" 14 "RESERVED" 15 "Invalid" ;
VAL_ 2281701648 UWB_TRNK_Status9 0 "Default" 1 "No_Ranging" 2 "URSK_Stored" 3 "UWB_Session_Setup" 4 "Ranging_Start(Not_In_Sync)" 5 "Ranging_Start(In_Sync)" 6 "Ranging_Stop(Max_Signal_Missed)" 7 "Fob_Ranging" 8 "RESERVED" 9 "RESERVED" 10 "RESERVED" 11 "RESERVED" 12 "RESERVED" 13 "RESERVED" 14 "RESERVED" 15 "Invalid" ;
VAL_ 2281701648 UWB_TRNK_Status10 0 "Default" 1 "No_Ranging" 2 "URSK_Stored" 3 "UWB_Session_Setup" 4 "Ranging_Start(Not_In_Sync)" 5 "Ranging_Start(In_Sync)" 6 "Ranging_Stop(Max_Signal_Missed)" 7 "Fob_Ranging" 8 "RESERVED" 9 "RESERVED" 10 "RESERVED" 11 "RESERVED" 12 "RESERVED" 13 "RESERVED" 14 "RESERVED" 15 "Invalid" ;
VAL_ 2281701648 UWB_TRNK_Status11 0 "Default" 1 "No_Ranging" 2 "URSK_Stored" 3 "UWB_Session_Setup" 4 "Ranging_Start(Not_In_Sync)" 5 "Ranging_Start(In_Sync)" 6 "Ranging_Stop(Max_Signal_Missed)" 7 "Fob_Ranging" 8 "RESERVED" 9 "RESERVED" 10 "RESERVED" 11 "RESERVED" 12 "RESERVED" 13 "RESERVED" 14 "RESERVED" 15 "Invalid" ;
VAL_ 2281701648 UWB_TRNK_Status12 0 "Default" 1 "No_Ranging" 2 "URSK_Stored" 3 "UWB_Session_Setup" 4 "Ranging_Start(Not_In_Sync)" 5 "Ranging_Start(In_Sync)" 6 "Ranging_Stop(Max_Signal_Missed)" 7 "Fob_Ranging" 8 "RESERVED" 9 "RESERVED" 10 "RESERVED" 11 "RESERVED" 12 "RESERVED" 13 "RESERVED" 14 "RESERVED" 15 "Invalid" ;
VAL_ 2281701648 UWB_TRNK_Status13 0 "Default" 1 "No_Ranging" 2 "URSK_Stored" 3 "UWB_Session_Setup" 4 "Ranging_Start(Not_In_Sync)" 5 "Ranging_Start(In_Sync)" 6 "Ranging_Stop(Max_Signal_Missed)" 7 "Fob_Ranging" 8 "RESERVED" 9 "RESERVED" 10 "RESERVED" 11 "RESERVED" 12 "RESERVED" 13 "RESERVED" 14 "RESERVED" 15 "Invalid" ;
VAL_ 2281701648 UWB_TRNK_Status14 0 "Default" 1 "No_Ranging" 2 "URSK_Stored" 3 "UWB_Session_Setup" 4 "Ranging_Start(Not_In_Sync)" 5 "Ranging_Start(In_Sync)" 6 "Ranging_Stop(Max_Signal_Missed)" 7 "Fob_Ranging" 8 "RESERVED" 9 "RESERVED" 10 "RESERVED" 11 "RESERVED" 12 "RESERVED" 13 "RESERVED" 14 "RESERVED" 15 "Invalid" ;
VAL_ 2281701648 UWB_TRNK_Status15 0 "Default" 1 "No_Ranging" 2 "URSK_Stored" 3 "UWB_Session_Setup" 4 "Ranging_Start(Not_In_Sync)" 5 "Ranging_Start(In_Sync)" 6 "Ranging_Stop(Max_Signal_Missed)" 7 "Fob_Ranging" 8 "RESERVED" 9 "RESERVED" 10 "RESERVED" 11 "RESERVED" 12 "RESERVED" 13 "RESERVED" 14 "RESERVED" 15 "Invalid" ;
VAL_ 2281701648 UWB_TRNK_Status16 0 "Default" 1 "No_Ranging" 2 "URSK_Stored" 3 "UWB_Session_Setup" 4 "Ranging_Start(Not_In_Sync)" 5 "Ranging_Start(In_Sync)" 6 "Ranging_Stop(Max_Signal_Missed)" 7 "Fob_Ranging" 8 "RESERVED" 9 "RESERVED" 10 "RESERVED" 11 "RESERVED" 12 "RESERVED" 13 "RESERVED" 14 "RESERVED" 15 "Invalid" ;
VAL_ 2214592624 L_WPC_FD_Crc1Val 0 "0x0x0~0xFFFF:CRCValue" 65535 "0x0x0~0xFFFF:CRCValue" ;
VAL_ 2214592624 L_WPC_FD_AlvCnt1Val 0 "0x0x0~0xFF:AlvCntValue" 255 "0x0x0~0xFF:AlvCntValue" ;
VAL_ 2214592624 WPC_NFCDetection_Sta 0 "Off" 1 "Detected" 2 "Not Detected" ;
VAL_ 2214592624 WPC_NFCReset_Sta 0 "Default" 1 "Reset Complete" ;
VAL_ 2214592624 WPC2_NFCDetection_Sta 0 "Off" 1 "Detected" 2 "Not Detected" ;
VAL_ 2214592624 WPC2_NFCReset_Sta 0 "Default" 1 "Reset Complete" ;
VAL_ 2281701664 L_ROA_FD_Crc1Val 0 "0x0x0~0xFFFF:CRCValue" 65535 "0x0x0~0xFFFF:CRCValue" ;
VAL_ 2281701664 L_ROA_FD_AlvCnt1Val 0 "0x0x0~0xFF:AlvCntValue" 255 "0x0x0~0xFF:AlvCntValue" ;
VAL_ 2281701664 ROA_ClassStat 0 "Default" 1 "Detect" 2 "Unknown" 3 "Empty" 4 "RESERVED" 5 "RESERVED" 6 "RESERVED" 7 "Error indicator" ;
VAL_ 2281701664 ROA_SnSrStat 0 "Default" 1 "Ready" 2 "Run" 3 "Done" 4 "Delaying" 5 "Stop" 6 "RESERVED" 7 "Error indicator" ;
VAL_ 2281701664 ROA_DetInfo 0 "Default" 1 "Detect" 2 "Unknown" 3 "Empty" 4 "RESERVED" 5 "RESERVED" 6 "RESERVED" 7 "Error indicator" ;
VAL_ 2281701664 ROA_SnSrBlckgeErrStat 0 "Default" 1 "Blckge_error" 2 "RESERVED" 3 "RESERVED" ;
VAL_ 2281701664 ROA_SnSrErrStat 0 "Default" 1 "Snsr_error" 2 "RESERVED" 3 "RESERVED" ;
VAL_ 2281701666 L_ROA_FR_FD_Crc1Val 0 "0x0x0~0xFFFF:CRCValue" 65535 "0x0x0~0xFFFF:CRCValue" ;
VAL_ 2281701666 L_ROA_FR_FD_AlvCnt1Val 0 "0x0x0~0xFF:AlvCntValue" 255 "0x0x0~0xFF:AlvCntValue" ;
VAL_ 2281701666 ROA_FR_ClassStat 0 "Default" 1 "Detect" 2 "Unknown" 3 "Empty" 4 "RESERVED" 5 "RESERVED" 6 "RESERVED" 7 "Error indicator" ;
VAL_ 2281701666 ROA_FR_SnSrStat 0 "Default" 1 "Ready" 2 "Run" 3 "Done" 4 "Delaying" 5 "Stop" 6 "RESERVED" 7 "Error indicator" ;
VAL_ 2281701666 ROA_FR_DetInfo 0 "Default" 1 "Detect" 2 "Unknown" 3 "Empty" 4 "RESERVED" 5 "RESERVED" 6 "RESERVED" 7 "Error indicator" ;
VAL_ 2281701666 ROA_FR_SnSrBlckgeErrStat 0 "Default" 1 "Blckge_error" 2 "RESERVED" 3 "RESERVED" ;
VAL_ 2281701666 ROA_FR_SnSrErrStat 0 "Default" 1 "Snsr_error" 2 "RESERVED" 3 "RESERVED" ;
VAL_ 2214592608 L_BDC_FD_ROA_Crc2Val 0 "0x0x0~0xFFFF:CRCValue" 65535 "0x0x0~0xFFFF:CRCValue" ;
VAL_ 2214592608 L_BDC_FD_ROA_AlvCnt2Val 0 "0x0x0~0xFF:AlvCntValue" 255 "0x0x0~0xFF:AlvCntValue" ;
VAL_ 2525341697 L_UWB_FR_FD_Crc4Val 0 "0x0x0~0xFFFF:CRCValue" 65535 "0x0x0~0xFFFF:CRCValue" ;
VAL_ 2525341697 L_UWB_FR_FD_AlvCnt4Val 0 "0x0x0~0xFF:AlvCntValue" 255 "0x0x0~0xFF:AlvCntValue" ;
VAL_ 2281701680 L_SAL_FD_Crc1Val 0 "0x0x0~0xFFFF:CRCValue" 65535 "0x0x0~0xFFFF:CRCValue" ;
VAL_ 2281701680 SAL_BttmBrightnessDutyRatio 0 "0x0x00~0xFA:Brightness duty ratio 0~100%" 250 "0x0x00~0xFA:Brightness duty ratio 0~100%" 251 "RESERVED" 252 "RESERVED" 253 "RESERVED" 254 "RESERVED" 255 "Invalid" ;
VAL_ 2281701680 SAL_BttmFadeInTime 0 "0x0x00~0xFE:0ms(0*10)~2540ms(254*10)" 254 "0x0x00~0xFE:0ms(0*10)~2540ms(254*10)" 255 "Invalid" ;
VAL_ 2281701680 SAL_BttmFadeOutTimeValue 0 "0x0x00~0xFE:Fade Out time 0ms(0*10)~2540ms(254*10)" 254 "0x0x00~0xFE:Fade Out time 0ms(0*10)~2540ms(254*10)" 255 "Invalid" ;
VAL_ 2281701680 SAL_MLNShiftModOptionState 0 "Default" 1 "Not apply" 2 "Apply" 3 "Invalid" ;
VAL_ 2281701680 L_SAL_FD_AlvCnt1Val 0 "0x0x0~0xFF:AlvCntValue" 255 "0x0x0~0xFF:AlvCntValue" ;
VAL_ 2281701680 SAL_MLSALApplyState 0 "Default" 1 "Not apply" 2 "Apply" 3 "Invalid" ;
VAL_ 2281701680 SAL_MLAIVoiceOptionState 0 "Default" 1 "Not apply" 2 "Apply" 3 "Invalid" ;
VAL_ 2281701680 SAL_MLTherapyOptionState 0 "Default" 1 "Not apply" 2 "Apply" 3 "Invalid" ;
VAL_ 2281701680 SAL_MLDualColorOptionState 0 "Default" 1 "Not apply" 2 "Apply" 3 "Invalid" ;
VAL_ 2281701680 SAL_MLNumRecommendColor 0 "Default" 1 "Number of recommended color" 2 "Number of recommended color" 3 "Number of recommended color" 4 "Number of recommended color" 5 "Number of recommended color" 6 "Number of recommended color" 7 "Number of recommended color" 8 "Number of recommended color" 9 "Number of recommended color" 10 "Number of recommended color" 11 "Number of recommended color" 12 "Number of recommended color" 13 "Number of recommended color" 14 "Number of recommended color" 15 "Invalid" ;
VAL_ 2281701680 SAL_UPRColorXValue 0 "0x0x00~0xFA:Color X 0~250" 250 "0x0x00~0xFA:Color X 0~250" 251 "RESERVED" 252 "RESERVED" 253 "RESERVED" 254 "RESERVED" 255 "Invalid" ;
VAL_ 2281701680 SAL_UPRColorYValue 0 "0x0x00~0xFA:Color Y 0~250" 250 "0x0x00~0xFA:Color Y 0~250" 251 "RESERVED" 252 "RESERVED" 253 "RESERVED" 254 "RESERVED" 255 "Invalid" ;
VAL_ 2281701680 SAL_BrightnessDutyRatio 0 "0x0x00~0xFA:Brightness duty ratio 0~100%" 250 "0x0x00~0xFA:Brightness duty ratio 0~100%" 251 "RESERVED" 252 "RESERVED" 253 "RESERVED" 254 "RESERVED" 255 "Invalid" ;
VAL_ 2281701680 SAL_FadeInTime 0 "0x0x00~0xFE:0ms(0*10)~2540ms(254*10)" 254 "0x0x00~0xFE:0ms(0*10)~2540ms(254*10)" 255 "Invalid" ;
VAL_ 2281701680 SAL_FadeOutTimeValue 0 "0x0x00~0xFE:Fade out time 0ms(0*10)~2540ms(254*10)" 254 "0x0x00~0xFE:Fade out time 0ms(0*10)~2540ms(254*10)" 255 "Invalid" ;
VAL_ 2281701680 SAL_MLEarlyEveningOptionState 0 "Default" 1 "Not apply" 2 "Apply" 3 "Invalid" ;
VAL_ 2281701680 SAL_MLTempChgOptionState 0 "Default" 1 "Not apply" 2 "Apply" 3 "Invalid" ;
VAL_ 2281701680 SAL_MLPhoneCallModOptionState 0 "Default" 1 "Not apply" 2 "Apply" 3 "Invalid" ;
VAL_ 2281701680 SAL_MLDoorWarnOptionState 0 "Default" 1 "Not apply" 2 "Front Only" 3 "Front & Rear" 4 "RESERVED" 5 "RESERVED" 6 "RESERVED" 7 "Invalid" ;
VAL_ 2281701680 SAL_MLHazardModOptionState 0 "Default" 1 "Not apply" 2 "Apply" 3 "Invalid" ;
VAL_ 2281701680 SAL_MLLowFuelModOptionState 0 "Default" 1 "Not apply" 2 "Apply" 3 "Invalid" ;
VAL_ 2281701680 SAL_BttmColorXValue 0 "0x0x00~0xFA:Color X 0~250" 250 "0x0x00~0xFA:Color X 0~250" 251 "RESERVED" 252 "RESERVED" 253 "RESERVED" 254 "RESERVED" 255 "Invalid" ;
VAL_ 2281701680 SAL_BttmColorYValue 0 "0x0x00~0xFA:Color Y 0~250" 250 "0x0x00~0xFA:Color Y 0~250" 251 "RESERVED" 252 "RESERVED" 253 "RESERVED" 254 "RESERVED" 255 "Invalid" ;
VAL_ 1025 BDC_FD_SMK_Crc2Val 0 "0x0x0~0xFFFF:CRCValue" 65535 "0x0x0~0xFFFF:CRCValue" ;
VAL_ 1025 SMK_RpmLoByteVal_Copy_0 0 "0x0x0~0xFF:RPM Low Byte Value" 255 "0x0x0~0xFF:RPM Low Byte Value" ;
VAL_ 1025 SMK_VehSpdDrctVal_Copy_0 0 "0x0x0~0xFF:Vehicle Speed Direct Value" 255 "0x0x0~0xFF:Vehicle Speed Direct Value" ;
VAL_ 1025 Fob_BattStaInfo_Copy_0 0 "Normal or No Information" 1 "Recent used FOB is in discharge warning voltage level" 2 "Not Used" 3 "Error Indicator" ;
VAL_ 1025 Fob_FoundDrvWlcmArea_Copy_0 0 "Default" 1 "Fob Found(Drv)" 2 "Not Used" 3 "Error Indicator" ;
VAL_ 1025 Fob_FoundAsstWlcmArea_Copy_0 0 "Default" 1 "Fob Found(Ast)" 2 "Not Used" 3 "Error Indicator" ;
VAL_ 1025 Fob_FoundExtrnlArea_Copy_0 0 "Default" 1 "Can't recognize" 2 "Fob recognized" 3 "Search in progress" ;
VAL_ 1025 Fob_FoundIntArea_Copy_0 0 "Default" 1 "Can't recognize" 2 "Fob recognized" 3 "Search in progress" ;
VAL_ 1025 Fob_LearntSta_Copy_0 0 "Learnt" 1 "Virgin" 2 "Not Used" 3 "Error Indicator" ;
VAL_ 1025 RSPA_LearntSta_Copy_0 0 "Non-RSPA Learnt" 1 "RSPA Learnt" 2 "Reserved" 3 "Error Indicator" ;
VAL_ 1025 RSPA_RFSigErrSta_Copy_0 0 "Default" 1 "Signal Invalid" 2 "In Progress" 3 "Error Indicator" ;
VAL_ 1025 RSPA_CanErrSta_Copy_0 0 "Default" 1 "RSPA CAN Error" 2 "Not Used" 3 "Error Indicator" ;
VAL_ 1025 RSPA_ModSta_SMK_Copy_0 0 "RSPA Off" 1 "RSPA On" 2 "Reserved" 3 "Reserved" 4 "Reserved" 5 "Reseved" 6 "Not Used" 7 "Error Indicator" ;
VAL_ 1025 RSPA_FobBattSta_Copy_0 0 "Normal" 1 "Low Battery" 2 "Reserved" 3 "Reserved" 4 "Reserved" 5 "Reseved" 6 "Not Used" 7 "Error Indicator" ;
VAL_ 1025 Fob_BtnReleasedSta_Copy_0 0 "Default" 1 "Butten Released" 2 "Not used" 3 "Error Indicator" ;
VAL_ 1025 Fob_FoundWlcmArea_Copy_0 0 "Default (Off)" 1 "Fob Found" 2 "Not Used" 3 "Error Indicator" ;
VAL_ 1025 USM_WALModSta_Copy_0 0 "Default" 1 "WAL Off" 2 "WAL On" 3 "Invalid" 4 "Reserved" 5 "Reseved" 6 "Not Used" 7 "Error Indicator" ;
VAL_ 1025 USM_SmrtTrnkTlgtModSta_Copy_0 0 "Default Value" 1 "HandsFree Off" 2 "HandsFree On" 3 "Reserved" 4 "Invalid" 5 "Reserved" 6 "Not Used" 7 "Error Indicator" ;
VAL_ 1025 USM_SAUModSta 0 "Default" 1 "Approach Unlock Off" 2 "Approach Unlock On" 3 "Invalid" 4 "RESERVED" 5 "RESERVED" 6 "RESERVED" 7 "Error Indicator" ;
VAL_ 1025 SMK_RLHndLkSnsrSta_Copy_0 0 "Off" 1 "On" 2 "Not Used" 3 "Error Indicator" ;
VAL_ 1025 BDC_FD_SMK_AlvCnt2Val 0 "0x0x0~0xFF:AlvCntValue" 255 "0x0x0~0xFF:AlvCntValue" ;
VAL_ 1025 SMK_RLDrHndUnLkSnsrSta_Copy_0 0 "Off" 1 "On" 2 "Not Used" 3 "Error Indicator" ;
VAL_ 1025 SMK_RRDrHndLkSnsrSta_Copy_0 0 "Off" 1 "On" 2 "Not Used" 3 "Error Indicator" ;
VAL_ 1025 SMK_RRDrHndUnLkSnsrSta_Copy_0 0 "Off" 1 "On" 2 "Not Used" 3 "Error Indicator" ;
VAL_ 1025 Fob_FoundCabinArea_Copy_0 0 "Default" 1 "Fob Found" 2 "No Fob Found" 3 "Error Indicator" ;
VAL_ 1025 SMK_ResultRmtStrt 0 "Off" 1 "Decryption Fail" 2 "Tele Engine Running Success" 3 "Tele Engine Running Fail" 4 "Tele Off Success" 5 "Tele Off Fail" 6 "Not Used" 7 "Error Indicator" ;
VAL_ 1025 SMK_EncryptTeleOptSta 0 "Off" 1 "Remote Start Encryption Applied" 2 "Remote Start Encryption Notapplied" 3 "Error Indicator" ;
VAL_ 1025 Auth_ISKLearnSta2_Copy_0 0 "Default(Normal)" 1 "Virgin" 2 "Learning" 3 "Learnt" 4 "Neutralizing" 5 "Neutralized" 6 "RESERVED" 7 "Invalid" ;
VAL_ 1025 Auth_ISKLearnSta_Copy_0 0 "Default(Normal)" 1 "Learning" 2 "Invalid" 3 "Neutral" 4 "Reserved" 5 "Reserved" 6 "Not used" 7 "Error Indicator" ;
VAL_ 1025 SMK_TlPwrOnSta_Copy_0 0 "Default" 1 "Power On" 2 "Not Used" 3 "Error Indicator" ;
VAL_ 1025 Fob_FoundForChargingDoor_Copy_0 0 "Default" 1 "Fob Found" 2 "No Fob Found" 3 "Error Indicator" ;
VAL_ 1025 SSB_StrtStpBtnSw1Sta_Copy_0 0 "Released" 1 "Pressed" 2 "Not Used" 3 "Error Indicator" ;
VAL_ 1025 SSB_StrtStpBtnSw2Sta_Copy_0 0 "Released" 1 "Pressed" 2 "Not Used" 3 "Error Indicator" ;
VAL_ 1025 SMK_AuthSta_Copy_0 0 "No Auth" 1 "Preauthentication" 2 "Authentication" 3 "Fast Restart" 4 "Reserved" 5 "Reseved" 6 "Not Used" 7 "Error Indicator" ;
VAL_ 1025 SMK_TlPwrOnOpt_Copy_0 0 "Not Applied" 1 "Applied" ;
VAL_ 1025 SMK_Ign1InSta_Copy_0 0 "IGN1 Off" 1 "IGN1 On" 2 "Not Used" 3 "Error Indicator" ;
VAL_ 1025 SMK_Ign1RlySta_Copy_0 0 "Off" 1 "On" 2 "Not Used" 3 "Error Indicator" ;
VAL_ 1025 SMK_Ign2InSta_Copy_0 0 "IGN2 Off" 1 "IGN2 On" 2 "Not Used" 3 "Error Indicator" ;
VAL_ 1025 SMK_Ign2RlySta_Copy_0 0 "Off" 1 "On" 2 "Not Used" 3 "Error Indicator" ;
VAL_ 1025 SMK_StrtFdbckSta_Copy_0 0 "Off" 1 "On" 2 "Not Used" 3 "Error Indicator" ;
VAL_ 1025 SMK_StrtrRlyOutSta_Copy_0 0 "Starter Relay Output Off" 1 "Starter Relay Output On" 2 "Not Used" 3 "Error Indicator" ;
VAL_ 1025 SMK_AccInSta_Copy_0 0 "ACC OFF" 1 "ACC ON" 2 "Not Used" 3 "Error Indicator" ;
VAL_ 1025 SMK_AccRlySta_Copy_0 0 "Off" 1 "On" 2 "Not Used" 3 "Error Indicator" ;
VAL_ 1025 SMK_CLUAccIndOnReq_Copy_0 0 "Cluster ACC Indicator Off" 1 "Cluster ACC Indicator On" 2 "Not Used" 3 "Error Indicator" ;
VAL_ 1025 SMK_VDModeActSta_Copy_0 0 "Off" 1 "On" 2 "Not Used" 3 "Error Indicator" ;
VAL_ 1025 SMK_SCULckUnlckSta_Copy_0 0 "Default" 1 "Lock" 2 "Unlock" 3 "Error Indicator" ;
VAL_ 1025 SMK_TlEngRunSta_Copy_0 0 "Off" 1 "Tele Engine Running" 2 "Not Used" 3 "Error Indicator" ;
VAL_ 1025 SMK_TlCrnkModSta_Copy_0 0 "Normal Mode" 1 "Tele Cranking Mode" 2 "Not Used" 3 "Error Indicator" ;
VAL_ 1025 SMK_RmtKeyEngRunSta_Copy_0 0 "Off" 1 "Remote Key Engine Running" 2 "Not Used" 3 "Error Indicator" ;
VAL_ 1025 SMK_RmtKeyCrnkModSta_Copy_0 0 "Normal Mode" 1 "Remote Key Cranking Mode" 2 "Not Used" 3 "Error Indicator" ;
VAL_ 1025 SMK_AsstTgglBtnSta_Copy_0 0 "Off" 1 "On" 2 "Not Used" 3 "Error Indicator" ;
VAL_ 1025 SMK_DrvTglBtnSta_Copy_0 0 "Off" 1 "On" 2 "Not Used" 3 "Error Indicator" ;
VAL_ 1025 SMK_RrLftTglBtnSta_Copy_0 0 "Off" 1 "On" 2 "Not Used" 3 "Error Indicator" ;
VAL_ 1025 SMK_RrRtTglBtnSta_Copy_0 0 "Off" 1 "On" 2 "Not Used" 3 "Error Indicator" ;
VAL_ 1025 SMK_TgglBtnStuckSta_Copy_0 0 "Normal" 1 "Toggle Stuck" 2 "Not Used" 3 "Error Indicator" ;
VAL_ 1025 SMK_AsstDrHndUnLkSnsrSta_Copy_0 0 "Off" 1 "On" 2 "Not Used" 3 "Error Indicator" ;
VAL_ 1025 SMK_BrkSwSta_Copy_0 0 "Off" 1 "On" 2 "Not Used" 3 "Error Indicator" ;
VAL_ 1025 SMK_GearPosPSwSta_Copy_0 0 "Off" 1 "On" 2 "Not Used" 3 "Error Indicator" ;
VAL_ 1025 SMK_CltchIgnLkSwSta_Copy_0 0 "Clutch Ign SW Off" 1 "Clutch Ign SW On(Step on the clutch)" 2 "Not Used" 3 "Error Indicator" ;
VAL_ 1025 SMK_DrvDrHndLkSnsrSta_Copy_0 0 "Off" 1 "On" 2 "Not Used" 3 "Error Indicator" ;
VAL_ 1025 SMK_DrvDrHndUnLkSnsrSta_Copy_0 0 "Off" 1 "On" 2 "Not Used" 3 "Error Indicator" ;
VAL_ 1025 SMK_AsstDrHndLkSnsrSta_Copy_0 0 "Off" 1 "On" 2 "Not Used" 3 "Error Indicator" ;
VAL_ 1025 LFAnt_FltSta_Copy_0 0 "Normal" 1 "Fault" 2 "Not Used" 3 "Error Indicator" ;
VAL_ 1025 LFAnt_SrchSta_Copy_0 0 "Off" 1 "On (LF Searching)" 2 "Not Used" 3 "Error Indicator" ;
VAL_ 1025 Lamp_HzrdBlnkngSta_Copy_0 0 "Off" 1 "Single Blinking" 2 "Double Blinking" 3 "Reserved" 4 "Reserved" 5 "Reseved" 6 "Not Used" 7 "Error Indicator" ;
VAL_ 1025 Lamp_SmrtWlcmLtOnReq_Copy_0 0 "Off" 1 "On" 2 "Not Used" 3 "Error Indicator" ;
VAL_ 1025 SMK_RpmHiByteVal_Copy_0 0 "0x0x0~0xFF:RPM High Byte Value" 255 "0x0x0~0xFF:RPM High Byte Value" ;
VAL_ 2529540353 L_UWB_RR_FD_Crc5Val 0 "0x0x0~0xFFFF:CRCValue" 65535 "0x0x0~0xFFFF:CRCValue" ;
VAL_ 2529540353 L_UWB_RR_FD_AlvCnt5Val 0 "0x0x0~0xFF:AlvCntValue" 255 "0x0x0~0xFF:AlvCntValue" ;
VAL_ 2521142529 L_UWB_BLE_SLV_FD_Crc9Val 0 "0x0x0~0xFFFF:CRCValue" 65535 "0x0x0~0xFFFF:CRCValue" ;
VAL_ 2521142529 L_UWB_BLE_SLV_FD_AlvCnt9Val 0 "0x0x0~0xFF:AlvCntValue" 255 "0x0x0~0xFF:AlvCntValue" ;
VAL_ 2533738753 L_UWB_FRNK_FD_Crc5Val 0 "0x0x0~0xFFFF:CRCValue" 65535 "0x0x0~0xFFFF:CRCValue" ;
VAL_ 2533738753 L_UWB_FRNK_FD_AlvCnt5Val 0 "0x0x0~0xFF:AlvCntValue" 255 "0x0x0~0xFF:AlvCntValue" ;
VAL_ 2529540865 L_UWB_RR_FD_Crc7Val 0 "0x0x0~0xFFFF:CRCValue" 65535 "0x0x0~0xFFFF:CRCValue" ;
VAL_ 2529540865 L_UWB_RR_FD_AlvCnt7Val 0 "0x0x0~0xFF:AlvCntValue" 255 "0x0x0~0xFF:AlvCntValue" ;
VAL_ 2521143041 L_UWB_BLE_SLV_FD_Crc11Val 0 "0x0x0~0xFFFF:CRCValue" 65535 "0x0x0~0xFFFF:CRCValue" ;
VAL_ 2521143041 L_UWB_BLE_SLV_FD_AlvCnt11Val 0 "0x0x0~0xFF:AlvCntValue" 255 "0x0x0~0xFF:AlvCntValue" ;
VAL_ 2533739265 L_UWB_FRNK_FD_Crc7Val 0 "0x0x0~0xFFFF:CRCValue" 65535 "0x0x0~0xFFFF:CRCValue" ;
VAL_ 2533739265 L_UWB_FRNK_FD_AlvCnt7Val 0 "0x0x0~0xFF:AlvCntValue" 255 "0x0x0~0xFF:AlvCntValue" ;
VAL_ 1087 CCU_01_Crc1Val 0 "0x0x0~0xFF:CRCValue" 255 "0x0x0~0xFF:CRCValue" ;
VAL_ 1087 CCU_01_AlvCnt1Val 0 "AlvCntValue" 1 "AlvCntValue" 2 "AlvCntValue" 3 "AlvCntValue" 4 "AlvCntValue" 5 "AlvCntValue" 6 "AlvCntValue" 7 "AlvCntValue" 8 "AlvCntValue" 9 "AlvCntValue" 10 "AlvCntValue" 11 "AlvCntValue" 12 "AlvCntValue" 13 "AlvCntValue" 14 "AlvCntValue" 15 "AlvCntValue" ;
VAL_ 1087 CCU_ForcedPowerOffReq 0 "OFF" 1 "ON in the non-sleep state" 2 "ON in the normal-sleep state" 3 "Reserved" ;
VAL_ 2214592730 L_UWB_BLE_SLV_FD_Crc22Val 0 "0x0x0~0xFFFF:CRCValue" 65535 "0x0x0~0xFFFF:CRCValue" ;
VAL_ 2214592730 L_UWB_BLE_SLV_FD_AlvCnt22Val 0 "0x0x0~0xFF:AlvCntValue" 255 "0x0x0~0xFF:AlvCntValue" ;
VAL_ 2214592730 SLV_DisconnectDKID 0 "0x0x0~0xFF:DK ID" 255 "0x0x0~0xFF:DK ID" ;
VAL_ 2214592730 SLV_DisconnectReason 0 "Default" 1 "L2CAP Creation Fail" 2 "OP RQ Not_Received" 3 "New Device Timeout" 4 "SMP Pairing Fail" 5 "DK Local Termination" 6 "Delete All and IRK Update" 7 "Disconnected by device" 8 "Supervision Timeout" 9 "Other reasons" ;
VAL_ 2525340161 L_UWB_FL_FD_Crc6Val 0 "0x0x0~0xFFFF:CRCValue" 65535 "0x0x0~0xFFFF:CRCValue" ;
VAL_ 2525340161 L_UWB_FL_FD_AlvCnt6Val 0 "0x0x0~0xFF:AlvCntValue" 255 "0x0x0~0xFF:AlvCntValue" ;
VAL_ 2214592720 L_UWB_FR_FD_Crc1Val 0 "0x0x0~0xFFFF:CRCValue" 65535 "0x0x0~0xFFFF:CRCValue" ;
VAL_ 2214592720 L_UWB_FR_FD_AlvCnt1Val 0 "0x0x0~0xFF:AlvCntValue" 255 "0x0x0~0xFF:AlvCntValue" ;
VAL_ 2214592720 UWB_FR_UWB_Decrypt_FB 0 "Default" 1 "Positive" 2 "Negative" 3 "RESERVED" 4 "RESERVED" 5 "RESERVED" 6 "RESERVED" 7 "RESERVED" 8 "RESERVED" 9 "RESERVED" 10 "RESERVED" 11 "RESERVED" 12 "RESERVED" 13 "RESERVED" 14 "RESERVED" 15 "RESERVED" ;
VAL_ 2214592720 UWB_FR_MST_Decrypt_FB 0 "Default" 1 "Positive" 2 "Negative" 3 "RESERVED" 4 "RESERVED" 5 "RESERVED" 6 "RESERVED" 7 "RESERVED" 8 "RESERVED" 9 "RESERVED" 10 "RESERVED" 11 "RESERVED" 12 "RESERVED" 13 "RESERVED" 14 "RESERVED" 15 "RESERVED" ;
VAL_ 2214592720 UWB_FR_OTA_Rsp 0 "Default" 1 "Request_Success" 2 "Request_Fail" 3 "Erase_Success" 4 "Erase_Fail" 5 "RESERVED" 6 "RESERVED" 7 "Verify_Success" 8 "Verify_Fail" 9 "RESERVED" 10 "RESERVED" 11 "Pause_Response" 12 "RESERVED" 13 "RESERVED" 14 "RESERVED" 15 "RESERVED" ;
VAL_ 2214592720 UWB_FR_UWB_IC_Status 0 "Status_OK" 1 "Status_Rejected" 2 "Status_Failed" 3 "Status_Syntax_Error" 4 "Status_Invalid_Param" 5 "Status_Invalid_Range" 6 "Status_Invalid_Message" 7 "Status_Unknow_GID" 8 "Status_Unknow_OID" 9 "Status_Read_Only" 10 "Status_Com_Retry" 11 "RESERVED" 12 "RESERVED" 13 "RESERVED" 14 "RESERVED" 15 "RESERVED" 17 "Session_Not_Exist" 18 "Session_Duplicate" 19 "Session_Active" 20 "Session_Max" 21 "Session_Not_Config" 22 "Session_Ongonig" 23 "RESERVED" 24 "RESERVED" 25 "RESERVED" 26 "Error_Slot_Len" 27 "Error_Slot_Per_RR" 28 "Error_STS_IDX" 29 "RESERVED" 30 "RESERVED" 31 "RESERVED" 32 "RESERVED" 33 "Init_Rejected" 34 "Init_Failed" 35 "Start_Rejected" 36 "Start_Failed" 37 "0x25~0xFF:RESERVED" 255 "0x25~0xFF:RESERVED" ;
VAL_ 2214592721 L_UWB_FR_FD_Crc2Val 0 "0x0x0~0xFFFF:CRCValue" 65535 "0x0x0~0xFFFF:CRCValue" ;
VAL_ 2214592721 L_UWB_FR_FD_AlvCnt2Val 0 "0x0x0~0xFF:AlvCntValue" 255 "0x0x0~0xFF:AlvCntValue" ;
